VERSION ""

NS_ :

BS_:

BU_: ICC DVR EPC BBCM EAMP CMSM SBOX FLZCU_HCU_IC FLZCU_IC HCU_IC FLZCU_Signal_IC CGW TBOX BNCM CWC FRZCU

BO_ 1072 FLZCU_31: 16 FLZCU_HCU_IC
 SG_ LHTurnlightSts : 19|1@0+ (1,0) [0|1] ""  ICC,DVR
 SG_ RHTurnlightSts : 20|1@0+ (1,0) [0|1] ""  ICC,DVR
 SG_ LHFdoorSts : 23|2@0+ (1,0) [0|3] ""  ICC
 SG_ LHFSeatBeltSW : 31|1@0+ (1,0) [0|1] ""  ICC,DVR
 SG_ TrunkSts : 37|2@0+ (1,0) [0|3] ""  ICC
 SG_ RLWinPosn : 47|7@0+ (1,0) [0|100] "%"  ICC
 SG_ SeatHeatLevelsFL : 49|2@0+ (1,0) [0|3] ""  ICC
 SG_ SeatHeatLevelsRL : 61|2@0+ (1,0) [0|3] ""  ICC
 SG_ SeatVentLevelsFL : 63|2@0+ (1,0) [0|3] ""  ICC
 SG_ SeatVentLevelsRL : 87|2@0+ (1,0) [0|3] ""  ICC
 SG_ FLWinPosn : 94|7@0+ (1,0) [0|100] "%"  ICC
 SG_ FLZCU_FrontWiperMaintenanceSts : 109|2@0+ (1,0) [0|3] ""  ICC
 SG_ FLZCU_RearWiperMaintenanceSts : 107|2@0+ (1,0) [0|3] ""  ICC

BO_ 1209 VCU_2_G: 8 FLZCU_HCU_IC
 SG_ VCU_2_G_CRC : 7|8@0+ (1,0) [0|255] ""  ICC
 SG_ VCU_2_G_RollgCntr : 11|4@0+ (1,0) [0|14] ""  ICC
 SG_ VCU_2_G_Resd : 15|4@0+ (1,0) [0|15] ""  ICC
 SG_ VCU_2_G_GasPedalPosInvalidData : 24|1@0+ (1,0) [0|1] ""  ICC,DVR
 SG_ VCU_2_G_PowerLimit : 25|1@0+ (1,0) [0|1] ""  ICC
 SG_ VCU_2_G_BrakeLightReq : 26|1@0+ (1,0) [0|1] ""  ICC
 SG_ VCU_2_G_VehicleSystemFailure : 27|1@0+ (1,0) [0|1] ""  ICC
 SG_ VCU_2_G_BootloadSts : 29|1@0+ (1,0) [0|1] ""  ICC
 SG_ VCU_2_G_DischgSts : 30|1@0+ (1,0) [0|1] ""  ICC
 SG_ VCU_2_G_BrakePedalStsValidData : 31|1@0+ (1,0) [0|1] ""  ICC,DVR
 SG_ VCU_2_G_ExhibitionMod : 32|1@0+ (1,0) [0|1] ""  ICC
 SG_ VCU_2_G_BrakePedalSts : 36|1@0+ (1,0) [0|1] ""  ICC,DVR
 SG_ VCU_2_G_DCDCEnable : 37|1@0+ (1,0) [0|1] ""  ICC
 SG_ VCU_2_G_HVReady : 38|1@0+ (1,0) [0|1] ""  ICC
 SG_ Res_VCU_2_G_Brake_state : 39|1@0+ (1,0) [0|1] ""  ICC
 SG_ VCU_2_G_VCUEnergyflow : 43|4@0+ (1,0) [0|15] ""  ICC
 SG_ VCU_2_G_DrvGearShiftFailureIndcn : 53|4@0+ (1,0) [0|15] ""  ICC
 SG_ VCU_2_G_GasPedalPosition : 49|10@0+ (0.1,0) [0|100] "%"  ICC,DVR

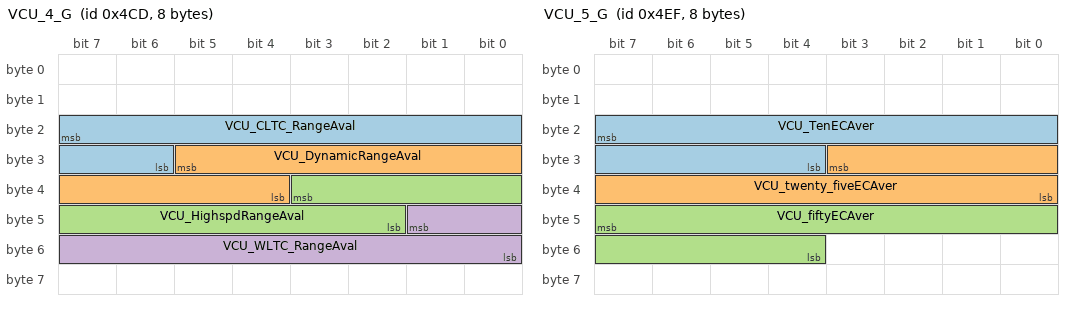
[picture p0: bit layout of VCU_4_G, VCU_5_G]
BO_ 1229 VCU_4_G: 8 FLZCU_HCU_IC
 SG_ VCU_CLTC_RangeAval : 23|10@0+ (1,0) [0|1022] "KM"  ICC
 SG_ VCU_DynamicRangeAval : 29|10@0+ (1,0) [0|1022] "KM"  ICC
 SG_ VCU_HighspdRangeAval : 35|10@0+ (1,0) [0|1022] "KM"  ICC
 SG_ VCU_WLTC_RangeAval : 41|10@0+ (1,0) [0|1022] "KM"  ICC

BO_ 1263 VCU_5_G: 8 FLZCU_HCU_IC
 SG_ VCU_TenECAver : 23|12@0+ (0.01,-10) [-10|25] "kwh"  ICC
 SG_ VCU_twenty_fiveECAver : 27|12@0+ (0.01,-10) [-10|25] "kwh"  ICC
 SG_ VCU_fiftyECAver : 47|12@0+ (0.01,-10) [-10|25] "kwh"  ICC

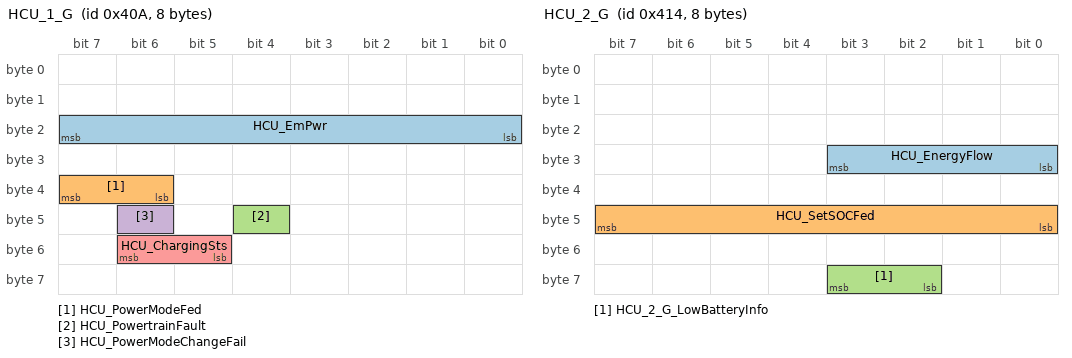
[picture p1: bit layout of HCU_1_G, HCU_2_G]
BO_ 1034 HCU_1_G: 8 FLZCU_HCU_IC
 SG_ HCU_EmPwr : 23|8@0+ (1,-128) [-100|100] "%"  ICC
 SG_ HCU_PowerModeFed : 39|2@0+ (1,0) [0|3] ""  ICC
 SG_ HCU_PowertrainFault : 44|1@0+ (1,0) [0|1] ""  ICC
 SG_ HCU_PowerModeChangeFail : 46|1@0+ (1,0) [0|1] ""  ICC
 SG_ HCU_ChargingSts : 54|2@0+ (1,0) [0|3] ""  ICC

BO_ 1044 HCU_2_G: 8 FLZCU_HCU_IC
 SG_ HCU_EnergyFlow : 27|4@0+ (1,0) [0|15] ""  ICC
 SG_ HCU_SetSOCFed : 47|8@0+ (1,0) [0|100] ""  ICC
 SG_ HCU_2_G_LowBatteryInfo : 59|2@0+ (1,0) [0|3] ""  ICC

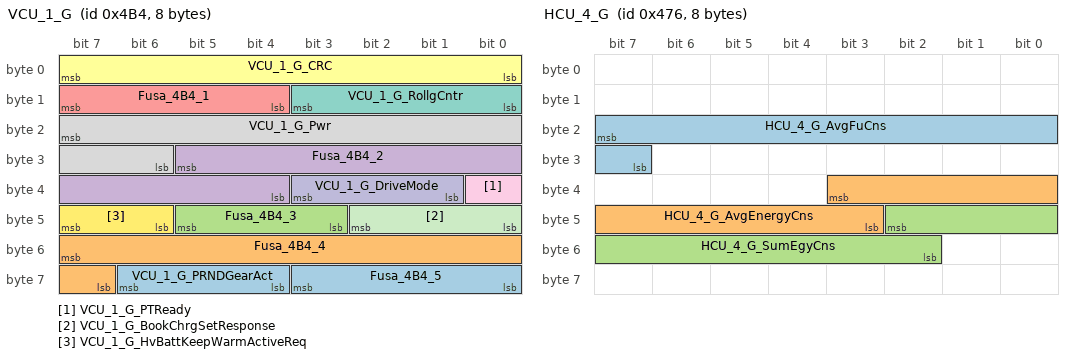
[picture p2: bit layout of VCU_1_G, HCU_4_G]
BO_ 1204 VCU_1_G: 8 FLZCU_HCU_IC
 SG_ Fusa_4B4_5 : 59|4@0+ (1,0) [0|15] ""  ICC
 SG_ Fusa_4B4_4 : 55|9@0+ (1,0) [0|511] ""  ICC
 SG_ Fusa_4B4_3 : 45|3@0+ (1,0) [0|7] ""  ICC
 SG_ Fusa_4B4_2 : 29|10@0+ (1,0) [0|1023] ""  ICC
 SG_ Fusa_4B4_1 : 15|4@0+ (1,0) [0|15] ""  ICC
 SG_ VCU_1_G_CRC : 7|8@0+ (1,0) [0|255] ""  ICC,BBCM
 SG_ VCU_1_G_RollgCntr : 11|4@0+ (1,0) [0|14] ""  ICC,BBCM
 SG_ VCU_1_G_Pwr : 23|10@0+ (1,-500) [-500|500] ""  ICC
 SG_ VCU_1_G_PTReady : 32|1@0+ (1,0) [0|1] ""  ICC
 SG_ VCU_1_G_DriveMode : 35|3@0+ (1,0) [0|7] ""  ICC
 SG_ VCU_1_G_BookChrgSetResponse : 42|3@0+ (1,0) [0|7] ""  ICC
 SG_ VCU_1_G_HvBattKeepWarmActiveReq : 47|2@0+ (1,0) [0|3] ""  ICC
 SG_ VCU_1_G_PRNDGearAct : 62|3@0+ (1,0) [0|7] ""  ICC,DVR,EPC,BBCM,EAMP,CMSM,SBOX

BO_ 1057 VCU_7_G: 32 FLZCU_HCU_IC
 SG_ VCU_TowingMode : 33|2@0+ (1,0) [0|3] ""  ICC
 SG_ VCU_EngyConsuPer50Km : 111|12@0+ (0.1,-100) [-100|100] ""  ICC
 SG_ VCU_BookChrgSetFailRes : 154|3@0+ (1,0) [0|7] ""  ICC
 SG_ VCU_BookChrgFailRes : 158|4@0+ (1,0) [0|15] ""  ICC
 SG_ VCU_BookChrgStsFb : 215|2@0+ (1,0) [0|3] ""  ICC
 SG_ HCU_EngineSelfMaintain : 231|2@0+ (1,0) [0|3] ""  ICC

BO_ 1043 FLZCU_8: 8 FLZCU_HCU_IC
 SG_ EBS_U_BATT : 7|14@0+ (0.0009765625,3) [3|18] "V"  ICC

BO_ 1022 FLZCU_40: 64 FLZCU_HCU_IC
 SG_ FLZCU_FLogolightInhibitSts : 130|1@0+ (1,0) [0|1] ""  ICC
 SG_ MaintenanceOdometer_Backup_3FEh : 175|24@0+ (0.1,0) [0|999999.9] ""  ICC
 SG_ FLZCU_CarMode : 23|3@0+ (1,0) [0|7] ""  ICC,BBCM
 SG_ FLZCU_SteerWhlposSts : 20|3@0+ (1,0) [0|7] ""  ICC
 SG_ FLZCU_MedStatusFb : 17|2@0+ (1,0) [0|3] ""  ICC,BBCM
 SG_ FLZCU_MedFailCause : 31|4@0+ (1,0) [0|15] ""  ICC
 SG_ FLZCU_MedAreaFb : 27|4@0+ (1,0) [0|15] ""  ICC
 SG_ FLZCU_MedClosePrompt : 39|2@0+ (1,0) [0|3] ""  ICC
 SG_ FLZCU_NapArea2Fb : 37|3@0+ (1,0) [0|7] ""  ICC
 SG_ FLZCU_2LSeatLvltargetCmd : 34|7@0+ (1,-1) [-1|100] "%"  ICC
 SG_ FLZCU_2LSeatBackAgtargetCmd : 43|7@0+ (1,-1) [-1|100] "%"  ICC
 SG_ FLZCU_2LSeatLegSpprttargetCmd : 52|7@0+ (1,-1) [-1|100] "%"  ICC
 SG_ FLZCU_FLWinThermalStatus : 61|1@0+ (1,0) [0|1] ""  ICC
 SG_ FLZCU_RLWinThermalStatus : 60|1@0+ (1,0) [0|1] ""  ICC
 SG_ FLZCU_MonoAmbLigSts : 59|1@0+ (1,0) [0|1] ""  ICC
 SG_ FLZCU_LogoChargingSts : 58|2@0+ (1,0) [0|3] ""  ICC
 SG_ FLZCU_2RSeatLvltargetCmd : 87|7@0+ (1,-1) [-1|100] "%"  ICC
 SG_ FLZCU_2RSeatBackAgtargetCmd : 80|7@0+ (1,-1) [-1|100] "%"  ICC
 SG_ FLZCU_2RSeatLegSpprttargetCmd : 89|7@0+ (1,-1) [-1|100] "%"  ICC
 SG_ FLZCU_SeatVentLvlFL2 : 111|4@0+ (1,0) [0|15] ""  ICC
 SG_ FLZCU_SeatVentLvlRL2 : 107|4@0+ (1,0) [0|15] ""  ICC
 SG_ FLZCU_SeatHeatLvlFL2 : 119|4@0+ (1,0) [0|15] ""  ICC
 SG_ FLZCU_SeatHeatLvlRL2 : 115|4@0+ (1,0) [0|15] ""  ICC
 SG_ FLZCU_FLSitPosnSts : 98|3@0+ (1,0) [0|7] ""  ICC
 SG_ FLZCU_SteerOverHeatWarn : 134|1@0+ (1,0) [0|1] ""  ICC

BO_ 1020 FLZCU_41: 64 FLZCU_HCU_IC
 SG_ CSA_2_WiprFrntCmd : 209|2@0+ (1,0) [0|3] ""  ICC
 SG_ ASU_2_RRHeight : 179|12@0+ (0.1,-150) [0|259.4] ""  ICC
 SG_ ASU_2_LRHeight : 175|12@0+ (0.1,-150) [0|259.4] ""  ICC
 SG_ ASU_2_RFHeight : 155|12@0+ (0.1,-150) [0|259.4] ""  ICC
 SG_ ASU_2_LFHeight : 151|12@0+ (0.1,-150) [0|259.4] ""  ICC
 SG_ ASU_2_sensorErrorSts : 143|4@0+ (1,0) [0|15] ""  ICC
 SG_ SAM_1_SteeringAngleSpeed : 23|8@0+ (4,0) [0|1016] "deg/Sec"  ICC
 SG_ SAM_1_SteeringAngle : 31|16@0+ (0.0625,-2048) [-2048|2047.875] "deg"  ICC
 SG_ BMSH_MaxChgPwrPeak : 47|12@0+ (0.1,0) [0|320] "KW"  ICC
 SG_ BMSH_MaxDchgPwrPeak : 51|12@0+ (0.1,0) [0|320] "KW"  ICC
 SG_ FMCU_8_ISGF_SpdAct : 71|16@0+ (1,-32767) [-32767|32766] "rpm"  ICC
 SG_ RMCU_1_Speed : 87|16@0+ (1,-32767) [-32767|32766] "rpm"  ICC
 SG_ SAM_1_SteeringAngleVD : 96|1@0+ (1,0) [0|1] ""  ICC
 SG_ SAM_1_SteeringAngleSpeedVD : 97|1@0+ (1,0) [0|1] ""  ICC
 SG_ CSA_2_AllWarningInfo : 100|3@0+ (1,0) [0|7] ""  ICC
 SG_ RELC_RoofCampLampConfigDisp : 101|1@0+ (1,0) [0|1] ""  ICC
 SG_ RELC_TopLightConfigDisp : 102|1@0+ (1,0) [0|1] ""  ICC
 SG_ EELC_APillarLightConfigDisp : 103|1@0+ (1,0) [0|1] ""  ICC
 SG_ RELC_RoofCampLampStsL : 111|2@0+ (1,0) [0|3] ""  ICC
 SG_ RELC_RoofCampLampStsR : 109|2@0+ (1,0) [0|3] ""  ICC
 SG_ RELC_TopLightSts : 107|2@0+ (1,0) [0|3] ""  ICC
 SG_ EELC_APillarYellowAmbientSts : 105|2@0+ (1,0) [0|3] ""  ICC
 SG_ EELC_APillarWhiteAmbientSts : 119|2@0+ (1,0) [0|3] ""  ICC
 SG_ EELC_APillarSpotLampSts : 117|2@0+ (1,0) [0|3] ""  ICC
 SG_ RMCU_1_TCURErrLvlDis : 127|3@0+ (1,0) [0|4] ""  ICC

BO_ 1142 HCU_4_G: 8 FLZCU_HCU_IC
 SG_ HCU_4_G_AvgFuCns : 23|9@0+ (0.1,0) [0|50] "L/100km"  ICC
 SG_ HCU_4_G_AvgEnergyCns : 35|9@0+ (0.1,0) [0|50] "L/100km"  ICC
 SG_ HCU_4_G_SumEgyCns : 42|9@0+ (0.1,0) [0|50] "L/100km"  ICC

BO_ 1314 HCU_25: 64 FLZCU_HCU_IC
 SG_ DriveModeChangeFailReason_522h : 429|2@0+ (1,0) [0|3] ""  ICC
 SG_ HCU_DeepSnowSts_522h : 427|2@0+ (1,0) [0|3] ""  ICC
 SG_ HCU_CrossBorderSts : 341|2@0+ (1,0) [0|3] ""  ICC
 SG_ HCU_SumElecCns : 339|12@0+ (0.1,-100) [-100|100] "kwh/100km"  ICC
 SG_ HCU_V2lDisChgBck : 17|2@0+ (1,0) [0|3] ""  ICC
 SG_ HCU_DisChgMemFed : 19|2@0+ (1,0) [0|3] ""  ICC
 SG_ HCU_V2VDisChgBck : 21|2@0+ (1,0) [0|3] ""  ICC
 SG_ HCU_V2l_IntlDisChgBck : 23|2@0+ (1,0) [0|3] ""  ICC
 SG_ HCU_FuelDetnOpDefeated : 25|2@0+ (1,0) [0|3] ""  ICC
 SG_ HCU_FuelDetnModSwtFed : 27|2@0+ (1,0) [0|3] ""  ICC
 SG_ HCU_FuelDetnStateFed : 29|2@0+ (1,0) [0|3] ""  ICC
 SG_ HCU_HVDownRepairModeFed : 31|2@0+ (1,0) [0|3] ""  ICC
 SG_ HCU_TrailerMode : 39|2@0+ (1,0) [0|3] ""  ICC
 SG_ HCU_SumFuCns : 37|9@0+ (0.1,0) [0|50] "L/km"  ICC
 SG_ HCU_DrivePowerDispSetFed : 51|2@0+ (1,0) [0|3] ""  ICC
 SG_ HCU_KeyDriveModememory : 49|2@0+ (1,0) [0|3] ""  ICC
 SG_ HCU_DRIFTModeSts : 63|2@0+ (1,0) [0|3] ""  ICC
 SG_ HCU_EXPERTEcoFed : 60|2@0+ (1,0) [0|3] ""  ICC
 SG_ HCU_4LModeFed : 58|1@0+ (1,0) [0|1] ""  ICC
 SG_ HCU_EXPERTNormFed : 57|2@0+ (1,0) [0|3] ""  ICC
 SG_ HCU_SingleRegnRmn : 61|1@0+ (1,0) [0|1] ""  ICC
 SG_ HCU_EXPERTSportFed : 87|2@0+ (1,0) [0|3] ""  ICC
 SG_ HCU_CrossaxisFed : 85|2@0+ (1,0) [0|3] ""  ICC
 SG_ HCU_EXPERTRWDFed : 83|2@0+ (1,0) [0|3] ""  ICC
 SG_ HCU_EXPERTAWDFed : 81|2@0+ (1,0) [0|3] ""  ICC
 SG_ HCU_EXPERTAutoFed : 95|2@0+ (1,0) [0|3] ""  ICC
 SG_ HCU_CLIMBFed : 93|2@0+ (1,0) [0|3] ""  ICC
 SG_ HCU_StopChrgnFed : 91|2@0+ (1,0) [0|3] ""  ICC
 SG_ HCU_StopChrgnModeFed : 89|2@0+ (1,0) [0|3] ""  ICC
 SG_ HCU_ChrgnFctMemSt : 102|2@0+ (1,0) [0|3] ""  ICC
 SG_ HCU_LVPowSupSYSAbn_lit : 100|1@0+ (1,0) [0|1] ""  ICC
 SG_ HCU_IMMOReleaseSignal : 99|1@0+ (1,0) [0|1] ""  ICC
 SG_ HCU_PowerCut : 98|1@0+ (1,0) [0|1] ""  ICC
 SG_ HCU_ParkingChargeReminder : 97|1@0+ (1,0) [0|1] ""  ICC
 SG_ HCU_HEV_FunctionLimit : 96|1@0+ (1,0) [0|1] ""  ICC
 SG_ HCU_SetModeNotChange : 110|1@0+ (1,0) [0|1] ""  ICC
 SG_ HCU_UTURNSnowFed : 111|1@0+ (1,0) [0|1] ""  ICC
 SG_ HCU_DriveInhibit_GearP : 109|1@0+ (1,0) [0|1] ""  ICC
 SG_ HCU_AccleAbility_Limit : 108|1@0+ (1,0) [0|1] ""  ICC
 SG_ HCU_VehicleSpeedMax_Limit : 107|1@0+ (1,0) [0|1] ""  ICC
 SG_ HCU_EngineRunClmReq : 106|1@0+ (1,0) [0|1] ""  ICC
 SG_ HCU_DisconnectChagWarn : 105|1@0+ (1,0) [0|1] ""  ICC
 SG_ HCU_PowerModeChangeInhibit : 104|1@0+ (1,0) [0|1] ""  ICC
 SG_ HCU_DisChargeStopFault : 119|2@0+ (1,0) [0|3] ""  ICC
 SG_ HCU_DedicatedModeInhibit : 117|1@0+ (1,0) [0|1] ""  ICC
 SG_ HCU_LeaveVehicleWarning : 116|1@0+ (1,0) [0|1] ""  ICC
 SG_ HCU_TowingModeEna : 115|1@0+ (1,0) [0|1] ""  ICC
 SG_ HCU_PowerLevel : 114|3@0+ (1,0) [0|7] ""  ICC
 SG_ HCU_FrntEDLSts : 127|4@0+ (1,0) [0|15] ""  ICC
 SG_ HCU_RearEDLSts : 123|4@0+ (1,0) [0|15] ""  ICC
 SG_ HCU_DriveMode_JT : 151|5@0+ (1,0) [0|31] ""  ICC
 SG_ HCU_CruiseLimitSpeedValue : 146|13@0+ (0.0625,0) [0|511.875] "km/h"  ICC
 SG_ HCU_CCOSwtFed : 165|2@0+ (1,0) [0|3] ""  ICC
 SG_ HCU_SinglePedalMemFed : 163|1@0+ (1,0) [0|1] ""  ICC
 SG_ HCU_Pwr : 175|12@0+ (1,-2000) [-2000|2000] "KW"  ICC
 SG_ HCU_SocManageFed : 162|3@0+ (1,0) [0|7] ""  ICC
 SG_ HCU_EgyRegenLevel : 191|3@0+ (1,0) [0|7] ""  ICC
 SG_ HCU_DrvGearShiftFailureIndcn : 179|4@0+ (1,0) [0|15] ""  ICC
 SG_ HCU_EXPERTEESPSet : 188|2@0+ (1,0) [0|3] ""  ICC
 SG_ HCU_UTURNSandFed : 184|1@0+ (1,0) [0|1] ""  ICC
 SG_ HCU_CruiseControlStatus : 186|2@0+ (1,0) [0|3] ""  ICC
 SG_ HCU_LTCDispFed : 215|2@0+ (1,0) [0|3] ""  ICC
 SG_ HCU_UTURNMudFed : 213|1@0+ (1,0) [0|1] ""  ICC
 SG_ HCU_UTURNGrassFed : 212|1@0+ (1,0) [0|1] ""  ICC
 SG_ HCU_EngyFlowToDisp : 211|5@0+ (1,0) [0|31] ""  ICC
 SG_ HCU_DriveModeChangeFail : 222|1@0+ (1,0) [0|1] ""  ICC
 SG_ HCU_iCCO_Warn : 221|4@0+ (1,0) [0|15] ""  ICC
 SG_ HCU_iTAS_Warn : 217|3@0+ (1,0) [0|7] ""  ICC
 SG_ HCU_DraggingModeRemind : 230|3@0+ (1,0) [0|7] ""  ICC
 SG_ HCU_25_EDLFed : 227|2@0+ (1,0) [0|3] ""  ICC
 SG_ HCU_25_Crossaxis_Warn : 225|3@0+ (1,0) [0|7] ""  ICC
 SG_ HCU_iTAS_Active : 238|2@0+ (1,0) [0|3] ""  ICC
 SG_ HCU_ExterTempLowHint : 236|2@0+ (1,0) [0|3] ""  ICC
 SG_ HCU_25_iTAS_SlopWarn : 234|2@0+ (1,0) [0|3] ""  ICC
 SG_ HCU_iTASSceneReq : 232|3@0+ (1,0) [0|7] ""  ICC
 SG_ HCU_DrivingModReq : 245|5@0+ (1,0) [0|31] ""  ICC
 SG_ HCU_25_VehSpdOffroadRmn : 240|1@0+ (1,0) [0|1] ""  ICC
 SG_ HCU_25_LaunchMod_Warn : 303|3@0+ (1,0) [0|7] ""  ICC
 SG_ HCU_25_SetVehSpdOffroad : 300|2@0+ (1,0) [0|3] ""  ICC
 SG_ HCU_25_iDRIFT_Warn : 298|3@0+ (1,0) [0|7] ""  ICC
 SG_ HCU_25_TAB_Warn : 307|3@0+ (1,0) [0|7] ""  ICC
 SG_ HCU_25_CCO_TextDisp : 311|4@0+ (1,0) [0|15] ""  ICC

BO_ 1075 VCC_2: 8 FLZCU_HCU_IC
 SG_ VCC_2_ConfigurationMessageTrg : 23|1@0+ (1,0) [0|1] ""  ICC,BBCM

BO_ 1136 VCC_3: 32 FLZCU_IC
 SG_ VCC_3_CRC : 7|8@0+ (1,0) [0|255] ""  ICC,BBCM
 SG_ VCC_3_RollgCntr : 11|4@0+ (1,0) [0|14] ""  ICC,BBCM
 SG_ VCC_3_Resd1 : 15|4@0+ (1,0) [0|15] ""  ICC,BBCM
 SG_ VCC_3_SN : 23|8@0+ (1,0) [1|32] ""  ICC,BBCM

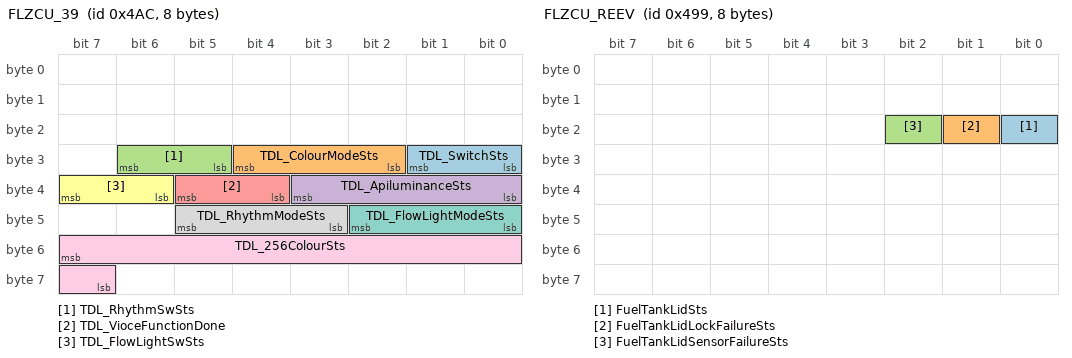
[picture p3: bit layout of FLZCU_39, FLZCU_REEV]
BO_ 1196 FLZCU_39: 8 FLZCU_HCU_IC
 SG_ TDL_SwitchSts : 25|2@0+ (1,0) [0|3] ""  ICC
 SG_ TDL_ColourModeSts : 28|3@0+ (1,0) [0|7] ""  ICC
 SG_ TDL_RhythmSwSts : 30|2@0+ (1,0) [0|3] ""  ICC
 SG_ TDL_ApiluminanceSts : 35|4@0+ (1,0) [0|15] ""  ICC
 SG_ TDL_VioceFunctionDone : 37|2@0+ (1,0) [0|3] ""  ICC
 SG_ TDL_FlowLightSwSts : 39|2@0+ (1,0) [0|3] ""  ICC
 SG_ TDL_FlowLightModeSts : 42|3@0+ (1,0) [0|7] ""  ICC
 SG_ TDL_RhythmModeSts : 45|3@0+ (1,0) [0|7] ""  ICC
 SG_ TDL_256ColourSts : 55|9@0+ (1,0) [0|256] ""  ICC

BO_ 1177 FLZCU_REEV: 8 FLZCU_HCU_IC
 SG_ FuelTankLidSts : 16|1@0+ (1,0) [0|1] ""  ICC
 SG_ FuelTankLidLockFailureSts : 17|1@0+ (1,0) [0|1] ""  ICC
 SG_ FuelTankLidSensorFailureSts : 18|1@0+ (1,0) [0|1] ""  ICC

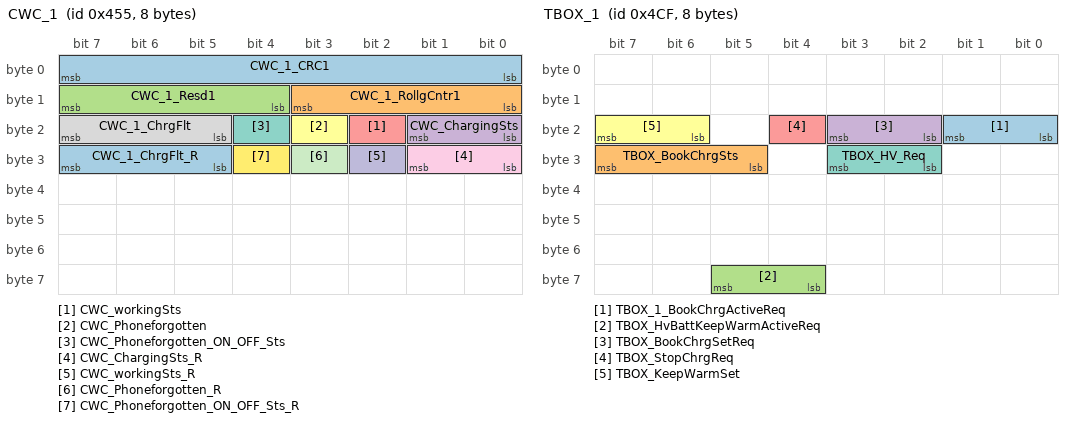
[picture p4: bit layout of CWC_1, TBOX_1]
BO_ 1109 CWC_1: 8 CGW
 SG_ CWC_1_CRC1 : 7|8@0+ (1,0) [0|255] ""  ICC
 SG_ CWC_1_RollgCntr1 : 11|4@0+ (1,0) [0|14] ""  ICC
 SG_ CWC_1_Resd1 : 15|4@0+ (1,0) [0|15] ""  ICC
 SG_ CWC_ChargingSts : 17|2@0+ (1,0) [0|3] ""  ICC
 SG_ CWC_workingSts : 18|1@0+ (1,0) [0|1] ""  ICC
 SG_ CWC_Phoneforgotten : 19|1@0+ (1,0) [0|1] ""  ICC
 SG_ CWC_Phoneforgotten_ON_OFF_Sts : 20|1@0+ (1,0) [0|1] ""  ICC
 SG_ CWC_1_ChrgFlt : 23|3@0+ (1,0) [0|7] ""  ICC
 SG_ CWC_ChargingSts_R : 25|2@0+ (1,0) [0|3] ""  ICC
 SG_ CWC_workingSts_R : 26|1@0+ (1,0) [0|1] ""  ICC
 SG_ CWC_Phoneforgotten_R : 27|1@0+ (1,0) [0|1] ""  ICC
 SG_ CWC_Phoneforgotten_ON_OFF_Sts_R : 28|1@0+ (1,0) [0|1] ""  ICC
 SG_ CWC_1_ChrgFlt_R : 31|3@0+ (1,0) [0|7] ""  ICC

BO_ 1231 TBOX_1: 8 CGW
 SG_ TBOX_1_BookChrgActiveReq : 17|2@0+ (1,0) [0|3] ""  ICC
 SG_ TBOX_BookChrgSts : 31|3@0+ (1,0) [0|7] ""  ICC
 SG_ TBOX_HvBattKeepWarmActiveReq : 61|2@0+ (1,0) [0|3] ""  ICC
 SG_ TBOX_BookChrgSetReq : 19|2@0+ (1,0) [0|3] ""  ICC
 SG_ TBOX_StopChrgReq : 20|1@0+ (1,0) [0|1] ""  ICC
 SG_ TBOX_KeepWarmSet : 23|2@0+ (1,0) [0|3] ""  ICC
 SG_ TBOX_HV_Req : 27|2@0+ (1,0) [0|3] ""  ICC

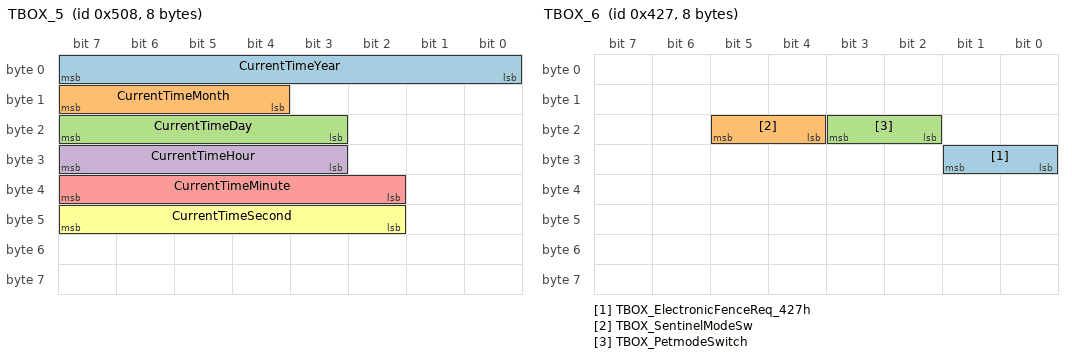
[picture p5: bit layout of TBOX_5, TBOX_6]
BO_ 1288 TBOX_5: 8 CGW
 SG_ CurrentTimeYear : 7|8@0+ (1,2000) [2000|2255] ""  ICC,SBOX
 SG_ CurrentTimeMonth : 15|4@0+ (1,0) [1|12] ""  ICC,SBOX
 SG_ CurrentTimeDay : 23|5@0+ (1,0) [1|31] ""  ICC,SBOX
 SG_ CurrentTimeHour : 31|5@0+ (1,0) [0|23] ""  ICC,SBOX
 SG_ CurrentTimeMinute : 39|6@0+ (1,0) [0|59] ""  ICC,SBOX
 SG_ CurrentTimeSecond : 47|6@0+ (1,0) [0|59] ""  ICC,SBOX

BO_ 1063 TBOX_6: 8 CGW
 SG_ TBOX_ElectronicFenceReq_427h : 25|2@0+ (1,0) [0|3] ""  ICC
 SG_ TBOX_SentinelModeSw : 21|2@0+ (1,0) [0|3] ""  ICC
 SG_ TBOX_PetmodeSwitch : 19|2@0+ (1,0) [0|3] ""  ICC

BO_ 1148 TBOX_7: 32 CGW
 SG_ ReservationSentinelSts_Fed_47Ch : 183|2@0+ (1,0) [0|3] ""  ICC
 SG_ TimeToStopSentinelMinutFed_47Ch : 181|6@0+ (1,0) [0|63] ""  ICC
 SG_ TimeToStopSentinelHourFed_47Ch : 172|5@0+ (1,0) [0|31] ""  ICC
 SG_ TimeToStartSentinelMinutFed_47Ch : 165|6@0+ (1,0) [0|63] ""  ICC
 SG_ TimeToStartSentinelHourFed_47Ch : 158|5@0+ (1,0) [0|31] ""  ICC
 SG_ TimeToStartSentinelDayFed_47Ch : 153|2@0+ (1,0) [0|3] ""  ICC
 SG_ TBOX_BkChrgStartTimeDay : 23|5@0+ (1,0) [1|31] "日"  ICC
 SG_ TBOX_BkChrgStartTimeeHour : 31|5@0+ (1,0) [0|23] "小时"  ICC
 SG_ TBOX_BkChrgStartTimeMin : 39|6@0+ (1,0) [0|59] "分钟"  ICC
 SG_ TBOX_GPSSwitchSts : 33|2@0+ (1,0) [0|3] ""  ICC
 SG_ TBOX_BkChrgStartTimeMonth : 47|4@0+ (1,0) [1|12] "月"  ICC
 SG_ TBOX_BkChrgStartTimeYear : 55|16@0+ (1,1900) [1900|9999] "年"  ICC
 SG_ TBOX_BkChrgDuration : 87|12@0+ (1,0) [0|1440] "min"  ICC
 SG_ TBOX_BkChrgCycleType : 91|3@0+ (1,0) [0|7] ""  ICC
 SG_ TBOX_BkChrgCycleMon : 103|2@0+ (1,0) [0|3] ""  ICC
 SG_ TBOX_BkChrgCycleTues : 101|2@0+ (1,0) [0|3] ""  ICC
 SG_ TBOX_BkChrgCycleWen : 99|2@0+ (1,0) [0|3] ""  ICC
 SG_ TBOX_BkChrgCycleThur : 97|2@0+ (1,0) [0|3] ""  ICC
 SG_ TBOX_BkChrgCycleFri : 111|2@0+ (1,0) [0|3] ""  ICC
 SG_ TBOX_BkChrgCycleSat : 109|2@0+ (1,0) [0|3] ""  ICC
 SG_ TBOX_BkChrgCycleSun : 107|2@0+ (1,0) [0|3] ""  ICC
 SG_ TBOX_KeepWarmStrt : 119|5@0+ (1,0) [1|31] "日"  ICC
 SG_ TBOX_KeepWarmStrtHour : 127|5@0+ (1,0) [0|23] "小时"  ICC
 SG_ TBOX_KeepWarmStrtMin : 151|6@0+ (1,0) [0|59] "分钟"  ICC

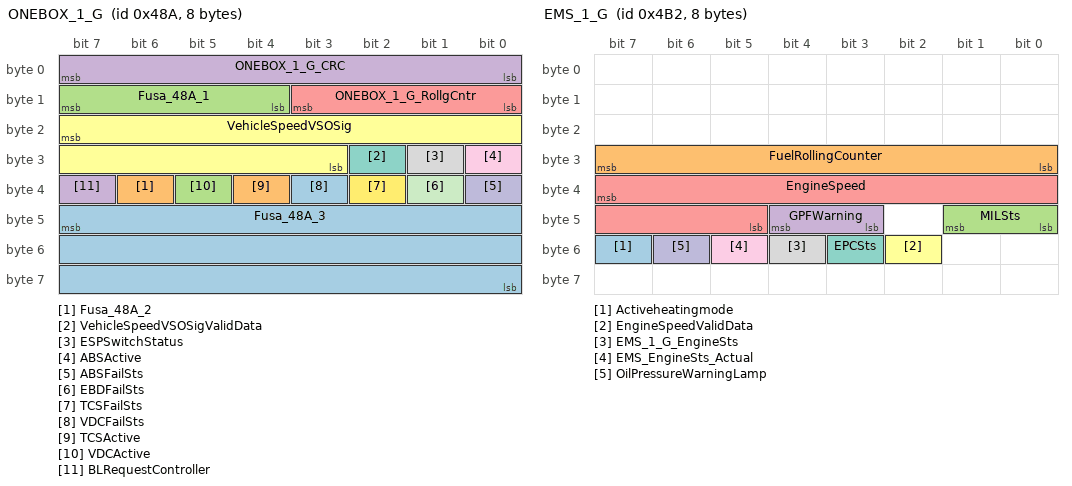
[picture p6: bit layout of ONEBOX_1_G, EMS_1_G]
BO_ 1162 ONEBOX_1_G: 8 CGW
 SG_ Fusa_48A_3 : 47|24@0+ (1,0) [0|16777215] ""  ICC
 SG_ Fusa_48A_2 : 38|1@0+ (1,0) [0|1] ""  ICC
 SG_ Fusa_48A_1 : 15|4@0+ (1,0) [0|15] ""  ICC
 SG_ ONEBOX_1_G_CRC : 7|8@0+ (1,0) [0|255] ""  ICC,BBCM
 SG_ ONEBOX_1_G_RollgCntr : 11|4@0+ (1,0) [0|14] ""  ICC,BBCM
 SG_ VehicleSpeedVSOSig : 23|13@0+ (0.0625,0) [0|511.875] "km/h"  ICC,DVR,EPC,BBCM,EAMP,CMSM,SBOX
 SG_ VehicleSpeedVSOSigValidData : 26|1@0+ (1,0) [0|1] ""  ICC,DVR,EPC,BBCM,EAMP,CMSM,SBOX
 SG_ ESPSwitchStatus : 25|1@0+ (1,0) [0|1] ""  ICC
 SG_ ABSActive : 24|1@0+ (1,0) [0|1] ""  ICC
 SG_ ABSFailSts : 32|1@0+ (1,0) [0|1] ""  ICC
 SG_ EBDFailSts : 33|1@0+ (1,0) [0|1] ""  ICC
 SG_ TCSFailSts : 34|1@0+ (1,0) [0|1] ""  ICC
 SG_ VDCFailSts : 35|1@0+ (1,0) [0|1] ""  ICC
 SG_ TCSActive : 36|1@0+ (1,0) [0|1] ""  ICC
 SG_ VDCActive : 37|1@0+ (1,0) [0|1] ""  ICC
 SG_ BLRequestController : 39|1@0+ (1,0) [0|1] ""  ICC

BO_ 1202 EMS_1_G: 8 CGW
 SG_ Activeheatingmode : 55|1@0+ (1,0) [0|1] ""  ICC
 SG_ FuelRollingCounter : 31|8@0+ (7.88519E-005,0) [0|0.0200283826] "ltr"  ICC
 SG_ MILSts : 41|2@0+ (1,0) [0|3] ""  ICC
 SG_ GPFWarning : 44|2@0+ (1,0) [0|3] ""  ICC
 SG_ EngineSpeed : 39|11@0+ (4,0) [0|8000] "rpm"  ICC
 SG_ EngineSpeedValidData : 50|1@0+ (1,0) [0|1] ""  ICC
 SG_ EPCSts : 51|1@0+ (1,0) [0|1] ""  ICC
 SG_ EMS_1_G_EngineSts : 52|1@0+ (1,0) [0|1] ""  ICC
 SG_ EMS_EngineSts_Actual : 53|1@0+ (1,0) [0|1] ""  ICC,EAMP
 SG_ OilPressureWarningLamp : 54|1@0+ (1,0) [0|1] ""  ICC

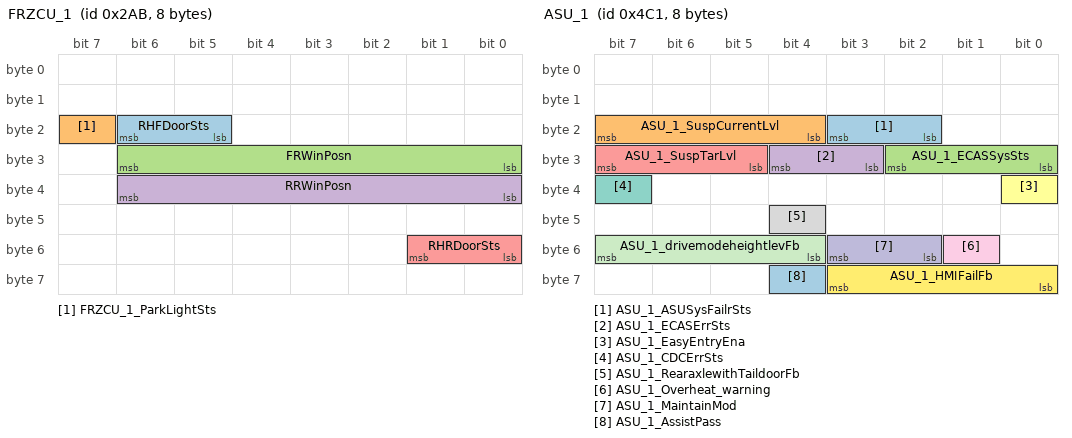
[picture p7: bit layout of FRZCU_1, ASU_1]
BO_ 683 FRZCU_1: 8 CGW
 SG_ RHFDoorSts : 22|2@0+ (1,0) [0|3] ""  ICC,EPC,BBCM,CMSM
 SG_ FRZCU_1_ParkLightSts : 23|1@0+ (1,0) [0|1] ""  ICC
 SG_ FRWinPosn : 30|7@0+ (1,0) [0|100] "%"  ICC
 SG_ RRWinPosn : 38|7@0+ (1,0) [0|100] "%"  ICC
 SG_ RHRDoorSts : 49|2@0+ (1,0) [0|3] ""  ICC,EPC,BBCM,CMSM

BO_ 33 ACU_3: 8 CGW
 SG_ ACU_3_LongitudinalAcceleration : 23|16@0+ (0.001,-2) [-2|2] "g"  ICC
 SG_ ACU_3_LongitudinalAccelerationVD : 39|2@0+ (1,0) [0|3] ""  ICC

BO_ 632 EMS_4: 8 CGW
 SG_ EngineCoolantTemperature : 23|8@0+ (0.75,-48) [-48|142.5] "°C"  ICC

BO_ 1217 ASU_1: 8 CGW
 SG_ ASU_1_ASUSysFailrSts : 19|2@0+ (1,0) [0|3] ""  ICC
 SG_ ASU_1_SuspCurrentLvl : 23|4@0+ (1,0) [0|15] ""  ICC
 SG_ ASU_1_ECASSysSts : 26|3@0+ (1,0) [0|7] ""  ICC
 SG_ ASU_1_ECASErrSts : 28|2@0+ (1,0) [0|3] ""  ICC
 SG_ ASU_1_SuspTarLvl : 31|3@0+ (1,0) [0|7] ""  ICC
 SG_ ASU_1_EasyEntryEna : 32|1@0+ (1,0) [0|1] ""  ICC
 SG_ ASU_1_CDCErrSts : 39|1@0+ (1,0) [0|1] ""  ICC
 SG_ ASU_1_RearaxlewithTaildoorFb : 44|1@0+ (1,0) [0|1] ""  ICC
 SG_ ASU_1_Overheat_warning : 49|1@0+ (1,0) [0|1] ""  ICC
 SG_ ASU_1_MaintainMod : 51|2@0+ (1,0) [0|3] ""  ICC
 SG_ ASU_1_drivemodeheightlevFb : 55|4@0+ (1,0) [0|15] ""  ICC
 SG_ ASU_1_HMIFailFb : 59|4@0+ (1,0) [0|15] ""  ICC
 SG_ ASU_1_AssistPass : 60|1@0+ (1,0) [0|1] ""  ICC

BO_ 258 BMS_1: 48 CGW
 SG_ BMS_1_CRC1 : 7|8@0+ (1,0) [0|255] ""  ICC
 SG_ BMS_1_RollgCntr1 : 11|4@0+ (1,0) [0|14] ""  ICC
 SG_ BMS_1_Resd1 : 15|4@0+ (1,0) [0|15] ""  ICC
 SG_ BMS_PackVoltage : 23|16@0+ (0.1,0) [0|1000] "volt(V)"  ICC
 SG_ BMS_PackCurrent : 39|16@0+ (0.1,-2047) [-2047|2047] "ampere(A)"  ICC
 SG_ BMS_HvBattSts : 51|4@0+ (1,0) [0|15] ""  ICC
 SG_ BMS_SysSelfCheck : 53|2@0+ (1,0) [0|3] ""  ICC
 SG_ BMS_HVBattThermRunaway : 55|2@0+ (1,0) [0|3] ""  ICC
 SG_ BMS_1_CRC2 : 71|8@0+ (1,0) [0|255] ""  ICC
 SG_ BMS_1_RollgCntr2 : 75|4@0+ (1,0) [0|14] ""  ICC
 SG_ BMS_1_Resd2 : 79|4@0+ (1,0) [0|15] ""  ICC
 SG_ BMS_ChargeVoltageReq : 87|14@0+ (0.1,0) [0|1024] "volt(V)"  ICC
 SG_ BMS_ChgCurrReq : 103|14@0+ (0.1,-1024) [-1024|0] "ampere(A)"  ICC
 SG_ BMS_InfraDcUActDc : 119|14@0+ (0.1,0) [0|1024] "volt(V)"  ICC
 SG_ BMS_1_CRC3 : 135|8@0+ (1,0) [0|255] ""  ICC
 SG_ BMS_1_RollgCntr3 : 139|4@0+ (1,0) [0|14] ""  ICC
 SG_ BMS_1_Resd3 : 143|4@0+ (1,0) [0|15] ""  ICC
 SG_ BMS_InfraDcIActDc : 151|14@0+ (0.1,-1024) [-1024|0] "ampere(A)"  ICC
 SG_ BMS_HvBattDynChrgnILim : 167|14@0+ (0.1,-1024) [-1024|0] "ampere(A)"  ICC
 SG_ BMS_HvBattUChrgnLim : 183|14@0+ (0.1,0) [0|1024] "volt(V)"  ICC
 SG_ BMS_1_CRC4 : 199|8@0+ (1,0) [0|255] ""  ICC
 SG_ BMS_1_RollgCntr4 : 203|4@0+ (1,0) [0|14] ""  ICC
 SG_ BMS_1_Resd4 : 207|4@0+ (1,0) [0|15] ""  ICC
 SG_ BMS_DChrgAPlusSt : 217|1@0+ (1,0) [0|1] ""  ICC
 SG_ BMS_ChrgDcIAvl : 215|14@0+ (0.1,-1024) [-1024|0] "ampere(A)"  ICC
 SG_ BMS_Insulation_R : 231|16@0+ (1,0) [0|60000] "kiloohm(kΩ)"  ICC
 SG_ BMS_ChrgDcCnctrDetd : 241|2@0+ (1,0) [0|3] ""  ICC
 SG_ BMS_DCChgMode : 244|3@0+ (1,0) [0|7] ""  ICC
 SG_ BMS_ChrgDcChrgnFltStopReas : 247|3@0+ (1,0) [0|7] ""  ICC
 SG_ BMS_1_CRC5 : 263|8@0+ (1,0) [0|255] ""  ICC
 SG_ BMS_1_RollgCntr5 : 267|4@0+ (1,0) [0|14] ""  ICC
 SG_ BMS_1_Resd5 : 271|4@0+ (1,0) [0|15] ""  ICC
 SG_ BMS_ChargeRequest_Mode : 284|4@0+ (1,0) [0|15] ""  ICC
 SG_ BMS_ChgRemTime : 279|11@0+ (1,0) [0|1440] "min"  ICC
 SG_ BMS_1_StateOfChargeDis : 295|8@0+ (1,0) [0|100] "%"  ICC
 SG_ BMS_StateOfEnergy : 311|16@0+ (0.1,0) [0|999.9] "kWh"  ICC
 SG_ BMS_1_CRC6 : 327|8@0+ (1,0) [0|255] ""  ICC
 SG_ BMS_1_RollgCntr6 : 331|4@0+ (1,0) [0|14] ""  ICC
 SG_ BMS_1_Resd6 : 335|4@0+ (1,0) [0|15] ""  ICC
 SG_ BMS_StateOfHealth : 342|7@0+ (1,0) [0|100] ""  ICC
 SG_ BMS_BlanceState : 343|1@0+ (1,0) [0|1] ""  ICC
 SG_ BMS_IsolationFault : 345|2@0+ (1,0) [0|3] ""  ICC
 SG_ BMS_HVILFault_DC : 346|1@0+ (1,0) [0|1] ""  ICC
 SG_ BMS_HVILFault_FMCU : 347|1@0+ (1,0) [0|1] ""  ICC
 SG_ BMS_HVILFault_RMCU : 348|1@0+ (1,0) [0|1] ""  ICC
 SG_ BMS_SOCDis : 359|14@0+ (0.01,0) [0|100] "%"  ICC
 SG_ BMS_InfraDcIActDcMin : 375|14@0+ (0.1,-1024) [-1024|0] "ampere(A)"  ICC

BO_ 1290 BMS_8: 8 CGW
 SG_ BMS_8_CRC1 : 7|8@0+ (1,0) [0|255] ""  ICC
 SG_ BMS_8_RollgCntr1 : 11|4@0+ (1,0) [0|14] ""  ICC
 SG_ BMS_8_Resd1 : 15|4@0+ (1,0) [0|15] ""  ICC
 SG_ BMS_HvBattCellOverU : 18|3@0+ (1,0) [0|4] ""  ICC
 SG_ BMS_HvBattCellUnderU : 21|3@0+ (1,0) [0|4] ""  ICC
 SG_ BMS_HvBattUnderU : 23|2@0+ (1,0) [0|2] ""  ICC
 SG_ BMS_HvBattDischargeOverCurrent : 26|3@0+ (1,0) [0|4] ""  ICC
 SG_ BMS_HvBattChargeOverCurrent : 29|3@0+ (1,0) [0|4] ""  ICC
 SG_ BMS_HvBattOverU : 31|2@0+ (1,0) [0|2] ""  ICC
 SG_ BMS_HvBattMismatching : 32|1@0+ (1,0) [0|1] ""  ICC
 SG_ BMS_HvBattSocJump : 33|1@0+ (1,0) [0|1] ""  ICC
 SG_ BMS_HvBattCellUUnif : 34|1@0+ (1,0) [0|1] ""  ICC
 SG_ BMS_HvBattLowSoc : 35|1@0+ (1,0) [0|1] ""  ICC
 SG_ BMS_HvBattOverSoc : 36|1@0+ (1,0) [0|1] ""  ICC
 SG_ BMS_HvBattTempUniformity : 37|1@0+ (1,0) [0|1] ""  ICC
 SG_ BMS_BattInterCANErr : 38|1@0+ (1,0) [0|1] ""  ICC
 SG_ BMS_HvBattOverCharging : 39|1@0+ (1,0) [0|1] ""  ICC
 SG_ BMS_HvBattOverTemperature : 47|3@0+ (1,0) [0|4] ""  ICC

BO_ 1163 FMCU_6: 8 CGW
 SG_ FMCU_SysTempOvrInd : 19|1@0+ (1,0) [0|1] ""  ICC

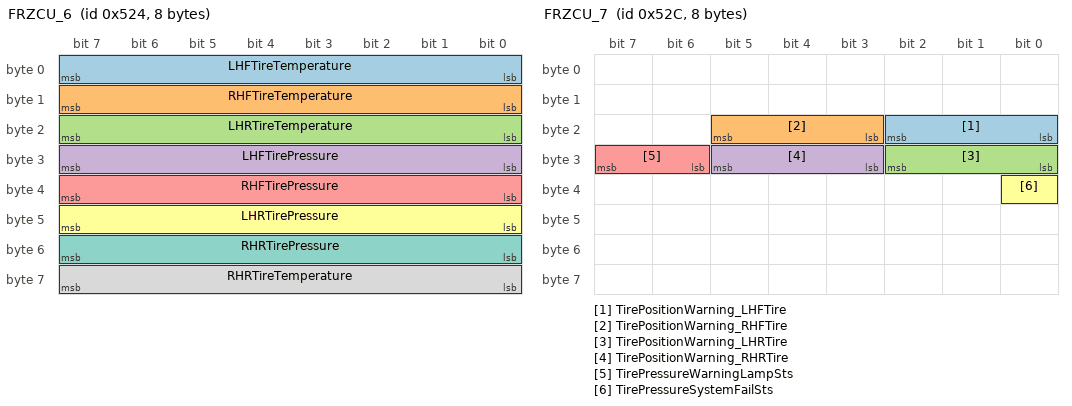
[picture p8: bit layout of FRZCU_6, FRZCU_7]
BO_ 1316 FRZCU_6: 8 CGW
 SG_ LHFTireTemperature : 7|8@0+ (0.65,-40) [-40|125.1] "℃"  ICC
 SG_ RHFTireTemperature : 15|8@0+ (0.65,-40) [-40|125.1] "℃"  ICC
 SG_ LHRTireTemperature : 23|8@0+ (0.65,-40) [-40|125.1] "℃"  ICC
 SG_ LHFTirePressure : 31|8@0+ (1.373,0) [0|350.115] "kPa"  ICC
 SG_ RHFTirePressure : 39|8@0+ (1.373,0) [0|350.115] "kPa"  ICC
 SG_ LHRTirePressure : 47|8@0+ (1.373,0) [0|350.115] "kPa"  ICC
 SG_ RHRTirePressure : 55|8@0+ (1.373,0) [0|350.115] "kPa"  ICC
 SG_ RHRTireTemperature : 63|8@0+ (0.65,-40) [-40|125.1] "℃"  ICC

BO_ 1324 FRZCU_7: 8 CGW
 SG_ TirePositionWarning_LHFTire : 18|3@0+ (1,0) [0|7] ""  ICC
 SG_ TirePositionWarning_RHFTire : 21|3@0+ (1,0) [0|7] ""  ICC
 SG_ TirePositionWarning_LHRTire : 26|3@0+ (1,0) [0|7] ""  ICC
 SG_ TirePositionWarning_RHRTire : 29|3@0+ (1,0) [0|7] ""  ICC
 SG_ TirePressureWarningLampSts : 31|2@0+ (1,0) [0|3] ""  ICC
 SG_ TirePressureSystemFailSts : 32|1@0+ (1,0) [0|1] ""  ICC

BO_ 991 TMS_2: 24 CGW
 SG_ TMS_MotorLoopErrorLevel : 126|3@0+ (1,0) [0|7] ""  ICC
 SG_ TMS_BatteryLoopErrorLevel : 123|3@0+ (1,0) [0|7] ""  ICC

BO_ 1188 TMS_3: 32 CGW
 SG_ FrontDeforestDisplaySts : 16|1@0+ (1,0) [0|1] ""  ICC
 SG_ TMS_DisplayActive : 18|1@0+ (1,0) [0|1] ""  ICC
 SG_ TMS_ZoneSelectionDisplaySts : 19|1@0+ (1,0) [0|1] ""  ICC
 SG_ TMS_AutoDisplaySts : 20|1@0+ (1,0) [0|1] ""  ICC
 SG_ TMS_FiltertchangeDisplaySts : 21|1@0+ (1,0) [0|1] ""  ICC
 SG_ TMS_AUTODefrostOnSts : 22|1@0+ (1,0) [0|1] ""  ICC
 SG_ TMS_AUTODefrostDisplaySts : 23|1@0+ (1,0) [0|1] ""  ICC
 SG_ TMS_RefInSufDispSts : 24|1@0+ (1,0) [0|1] ""  ICC
 SG_ TMS_CooltInSufDispSts : 25|1@0+ (1,0) [0|1] ""  ICC
 SG_ TMS_DLOnOffSts : 26|1@0+ (1,0) [0|1] ""  ICC
 SG_ TMS_DROnOffSts : 27|1@0+ (1,0) [0|1] ""  ICC
 SG_ TMS_PLOnOffSts : 28|1@0+ (1,0) [0|1] ""  ICC
 SG_ WorkingSts : 29|1@0+ (1,0) [0|1] ""  ICC
 SG_ TMS_PROnOffSts : 30|1@0+ (1,0) [0|1] ""  ICC
 SG_ TMS_DCOnOffSts : 31|1@0+ (1,0) [0|1] ""  ICC
 SG_ TMS_ACFastCool : 48|1@0+ (1,0) [0|1] ""  ICC
 SG_ TMS_ACFastHeat : 49|1@0+ (1,0) [0|1] ""  ICC
 SG_ TMS_LoveRemind : 50|1@0+ (1,0) [0|1] ""  ICC
 SG_ TMS_InteCleanCar : 51|1@0+ (1,0) [0|1] ""  ICC
 SG_ TMS_ACVentilationSts : 52|1@0+ (1,0) [0|1] ""  ICC
 SG_ TMS_AutoAirCleanSts : 53|1@0+ (1,0) [0|1] ""  ICC
 SG_ PM25Sts : 54|1@0+ (1,0) [0|1] ""  ICC
 SG_ TMS_ACModeCustomSts : 33|2@0+ (1,0) [0|3] ""  ICC
 SG_ TMS_ACRequestDisplaySts : 36|3@0+ (1,0) [0|7] ""  ICC
 SG_ TMS_AUTODefLevelSts : 39|3@0+ (1,0) [0|7] ""  ICC
 SG_ TMS_KeepWarm : 41|2@0+ (1,0) [0|3] ""  ICC
 SG_ TMS_DSwingSts : 44|3@0+ (1,0) [0|7] ""  ICC
 SG_ TMS_PSwingSts : 47|3@0+ (1,0) [0|7] ""  ICC
 SG_ TMS_TuisongDispSts : 58|3@0+ (1,0) [0|7] ""  ICC
 SG_ TMS_SetTemperature_L_C : 63|5@0+ (0.5,15.5) [15.5|30.5] ""  ICC
 SG_ TMS_SetTemperature_R_C : 68|5@0+ (0.5,15.5) [15.5|30.5] ""  ICC
 SG_ TMS_ModeAdjustDisplaySts : 75|4@0+ (1,0) [0|15] ""  ICC
 SG_ TMS_CirculationModeDisplaySts : 79|2@0+ (1,0) [0|3] ""  ICC
 SG_ TMS_IncarTemp : 87|8@0+ (0.5,-40) [-40|85] ""  ICC
 SG_ TMS_FliterLife : 94|7@0+ (1,0) [0|100] ""  ICC
 SG_ TMS_DLSwingUpDwnWPosn : 102|7@0+ (1,0) [0|100] ""  ICC
 SG_ TMS_DLSwingLeRiWPosn : 110|7@0+ (1,0) [0|100] ""  ICC
 SG_ TMS_DRSwingUpDwnWPosn : 118|7@0+ (1,0) [0|100] ""  ICC
 SG_ TMS_DRSwingLeRiWPosn : 126|7@0+ (1,0) [0|100] ""  ICC
 SG_ TMS_PLSwingUpDwnWPosn : 134|7@0+ (1,0) [0|100] ""  ICC
 SG_ TMS_PLSwingLeRiWPosn : 142|7@0+ (1,0) [0|100] ""  ICC
 SG_ TMS_PRSwingUpDwnWPosn : 150|7@0+ (1,0) [0|100] ""  ICC
 SG_ TMS_PRSwingLeRiWPosn : 158|7@0+ (1,0) [0|100] ""  ICC
 SG_ TMS_DCSwingLeRiWPosn : 166|7@0+ (1,0) [0|100] ""  ICC
 SG_ AirSwingSts : 168|1@0+ (1,0) [0|1] ""  ICC
 SG_ TemperatureUnit : 169|1@0+ (1,0) [0|1] ""  ICC
 SG_ BlowAdvanceOnSts : 170|1@0+ (1,0) [0|1] ""  ICC
 SG_ BlowDelayOffSts : 171|1@0+ (1,0) [0|1] ""  ICC
 SG_ TMS_PM25_ExtSts : 172|1@0+ (1,0) [0|1] ""  ICC
 SG_ TMS_PM25_IncarSts : 173|1@0+ (1,0) [0|1] ""  ICC
 SG_ TMS_AQS_Sts : 174|1@0+ (1,0) [0|1] ""  ICC
 SG_ PM25overproofDisplaySts : 175|1@0+ (1,0) [0|1] ""  ICC
 SG_ AQSDisplaySts : 176|1@0+ (1,0) [0|1] ""  ICC
 SG_ PM25AutoRunSts : 177|1@0+ (1,0) [0|1] ""  ICC
 SG_ PM25AutoRunSetSts : 178|1@0+ (1,0) [0|1] ""  ICC
 SG_ FragranceWelcomeModeSts : 179|1@0+ (1,0) [0|1] ""  ICC
 SG_ FragranceDisplaysts : 180|1@0+ (1,0) [0|1] ""  ICC
 SG_ TMS_AQS_Level : 185|2@0+ (1,0) [0|3] ""  ICC
 SG_ ACRequestCommand : 188|3@0+ (1,0) [0|7] ""  ICC
 SG_ PM25_Outcar_Level : 191|3@0+ (1,0) [0|7] ""  ICC
 SG_ PM25_Incar_Level : 194|3@0+ (1,0) [0|7] ""  ICC
 SG_ SetTemperature_L_F : 215|5@0+ (1,63) [63|93] ""  ICC
 SG_ SetTemperature_R_F : 223|5@0+ (1,63) [63|93] ""  ICC
 SG_ TMS_PM25_incar : 231|10@0+ (1,0) [0|1000] ""  ICC
 SG_ TMS_PM25_ext : 237|10@0+ (1,0) [0|1000] ""  ICC
 SG_ TMS_KeepWarmMemoryFb : 243|2@0+ (1,0) [0|3] ""  ICC

BO_ 612 EPB_R_1: 24 CGW
 SG_ Fusa_264_5 : 40|17@0+ (1,0) [0|131071] ""  ICC
 SG_ Fusa_264_4 : 47|6@0+ (1,0) [0|63] ""  ICC
 SG_ Fusa_264_3 : 24|5@0+ (1,0) [0|31] ""  ICC
 SG_ Fusa_264_2 : 16|7@0+ (1,0) [0|127] ""  ICC
 SG_ Fusa_264_1 : 15|4@0+ (1,0) [0|15] ""  ICC
 SG_ EPB_R_1_CRC1 : 7|8@0+ (1,0) [0|255] ""  ICC
 SG_ EPB_R_1_RollgCntr1 : 11|4@0+ (1,0) [0|14] ""  ICC
 SG_ EPB_1_FltLamp : 18|2@0+ (1,0) [0|3] ""  ICC
 SG_ EPB_1_ParkLamp : 20|2@0+ (1,0) [0|3] ""  ICC
 SG_ EPB_1_ActrSt : 23|3@0+ (1,0) [0|7] ""  ICC,DVR
 SG_ EPB_1_RWUSt : 25|1@0+ (1,0) [0|1] ""  ICC
 SG_ EPB_1_TextDisp : 35|4@0+ (1,0) [0|15] ""  ICC
 SG_ IPB_EPBErrorStatus : 41|1@0+ (1,0) [0|1] ""  ICC

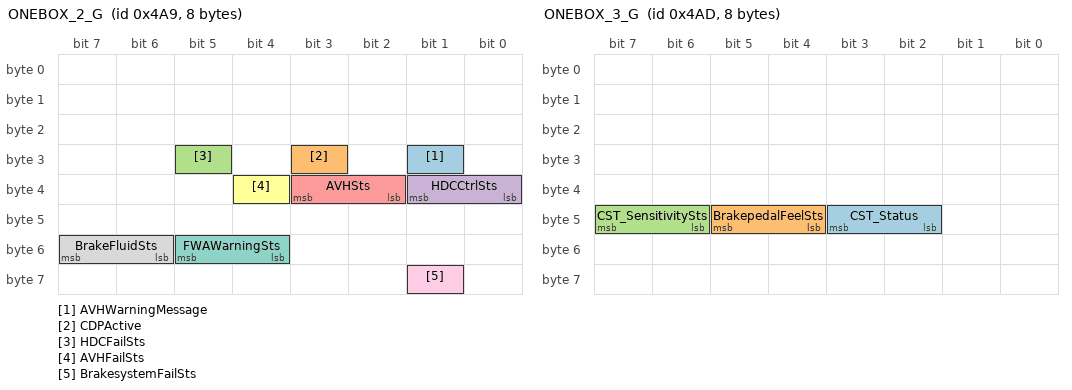
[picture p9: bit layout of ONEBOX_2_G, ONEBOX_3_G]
BO_ 1193 ONEBOX_2_G: 8 CGW
 SG_ AVHWarningMessage : 25|1@0+ (1,0) [0|1] ""  ICC
 SG_ CDPActive : 27|1@0+ (1,0) [0|1] ""  ICC
 SG_ HDCFailSts : 29|1@0+ (1,0) [0|1] ""  ICC
 SG_ HDCCtrlSts : 33|2@0+ (1,0) [0|3] ""  ICC
 SG_ AVHSts : 35|2@0+ (1,0) [0|3] ""  ICC
 SG_ AVHFailSts : 36|1@0+ (1,0) [0|1] ""  ICC
 SG_ FWAWarningSts : 53|2@0+ (1,0) [0|3] ""  ICC
 SG_ BrakeFluidSts : 55|2@0+ (1,0) [0|3] ""  ICC
 SG_ BrakesystemFailSts : 57|1@0+ (1,0) [0|1] ""  ICC

BO_ 1197 ONEBOX_3_G: 8 CGW
 SG_ CST_Status : 43|2@0+ (1,0) [0|3] ""  ICC
 SG_ BrakepedalFeelSts : 45|2@0+ (1,0) [0|3] ""  ICC
 SG_ CST_SensitivitySts : 47|2@0+ (1,0) [0|3] ""  ICC

BO_ 1200 FLZCU_6: 8 CGW
 SG_ EBS_SOC : 7|8@0+ (1,0) [0|100] "%"  ICC

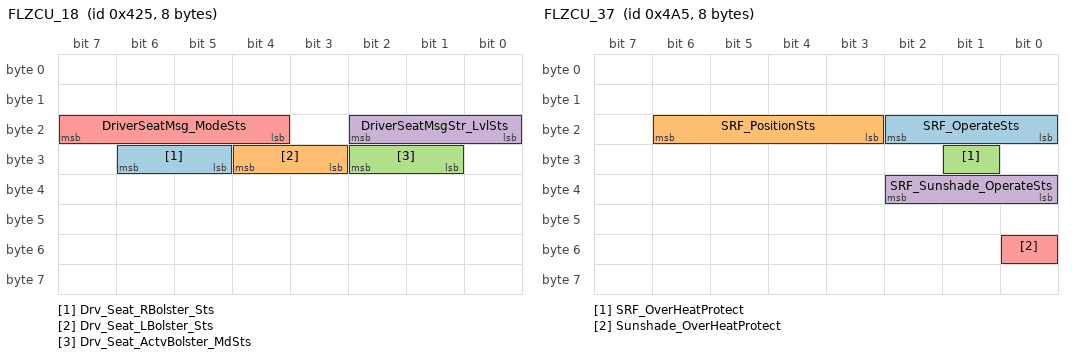
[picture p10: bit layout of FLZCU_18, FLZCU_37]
BO_ 1061 FLZCU_18: 8 CGW
 SG_ Drv_Seat_RBolster_Sts : 30|2@0+ (1,0) [0|3] ""  ICC
 SG_ Drv_Seat_LBolster_Sts : 28|2@0+ (1,0) [0|3] ""  ICC
 SG_ Drv_Seat_ActvBolster_MdSts : 26|2@0+ (1,0) [0|3] ""  ICC
 SG_ DriverSeatMsgStr_LvlSts : 18|3@0+ (1,0) [0|7] ""  ICC
 SG_ DriverSeatMsg_ModeSts : 23|4@0+ (1,0) [0|15] ""  ICC

BO_ 1065 FLZCU_19: 8 CGW
 SG_ LeftSeatMsgStr_LvlSts : 18|3@0+ (1,0) [0|7] ""  ICC
 SG_ LeftSeatMsg_ModeSts : 23|4@0+ (1,0) [0|15] ""  ICC

BO_ 1069 FLZCU_20: 8 CGW
 SG_ PassSeatMsgStr_LvlSts : 18|3@0+ (1,0) [0|7] ""  ICC
 SG_ PassSeatMsg_ModeSts : 23|4@0+ (1,0) [0|15] ""  ICC

BO_ 1087 FLZCU_21: 8 CGW
 SG_ RightSeatMsgStr_LvlSts : 18|3@0+ (1,0) [0|7] ""  ICC
 SG_ RightSeatMsg_ModeSts : 23|4@0+ (1,0) [0|15] ""  ICC

BO_ 1189 FLZCU_37: 8 CGW
 SG_ SRF_OperateSts : 18|3@0+ (1,0) [0|7] ""  ICC
 SG_ SRF_PositionSts : 22|4@0+ (1,0) [0|12] ""  ICC
 SG_ SRF_OverHeatProtect : 25|1@0+ (1,0) [0|1] ""  ICC
 SG_ SRF_Sunshade_OperateSts : 34|3@0+ (1,0) [0|7] ""  ICC
 SG_ Sunshade_OverHeatProtect : 48|1@0+ (1,0) [0|1] ""  ICC

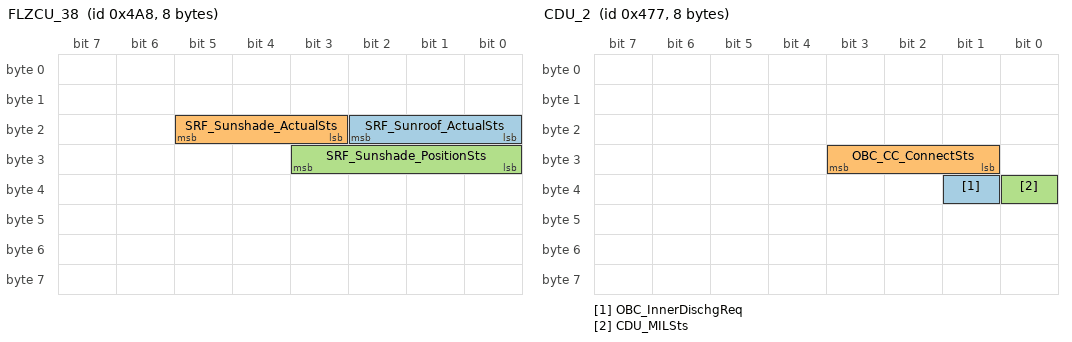
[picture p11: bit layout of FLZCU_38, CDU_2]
BO_ 1192 FLZCU_38: 8 CGW
 SG_ SRF_Sunroof_ActualSts : 18|3@0+ (1,0) [0|7] ""  ICC
 SG_ SRF_Sunshade_ActualSts : 21|3@0+ (1,0) [0|7] ""  ICC
 SG_ SRF_Sunshade_PositionSts : 27|4@0+ (1,0) [0|12] ""  ICC

BO_ 1143 CDU_2: 8 CGW
 SG_ OBC_InnerDischgReq : 33|1@0+ (1,0) [0|1] ""  ICC
 SG_ OBC_CC_ConnectSts : 27|3@0+ (1,0) [0|7] ""  ICC
 SG_ CDU_MILSts : 32|1@0+ (1,0) [0|1] ""  ICC

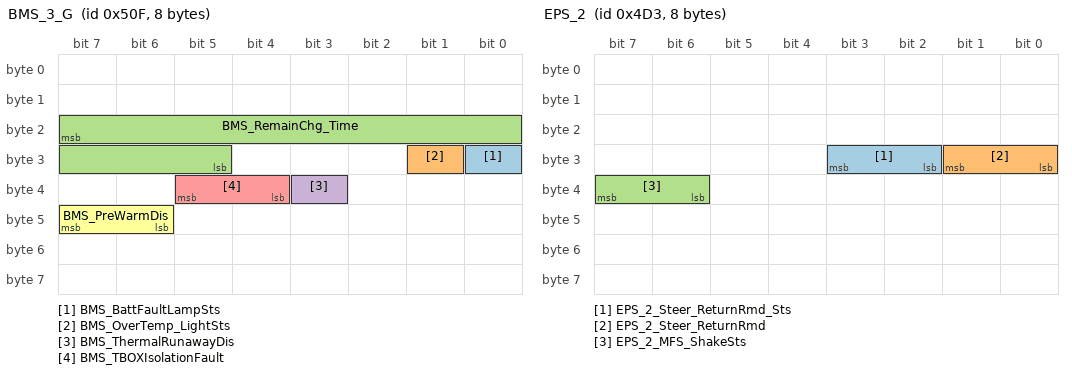
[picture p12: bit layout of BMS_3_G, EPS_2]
BO_ 1295 BMS_3_G: 8 CGW
 SG_ BMS_BattFaultLampSts : 24|1@0+ (1,0) [0|1] ""  ICC
 SG_ BMS_OverTemp_LightSts : 25|1@0+ (1,0) [0|1] ""  ICC
 SG_ BMS_RemainChg_Time : 23|11@0+ (1,0) [0|2047] "min"  ICC
 SG_ BMS_ThermalRunawayDis : 35|1@0+ (1,0) [0|1] ""  ICC
 SG_ BMS_TBOXIsolationFault : 37|2@0+ (1,0) [0|3] ""  ICC
 SG_ BMS_PreWarmDis : 47|2@0+ (1,0) [0|2] ""  ICC

BO_ 1531 BMS_9: 32 CGW
 SG_ BMS_HvBattSoeActDisChaCyc : 23|16@0+ (0.1,0) [0|999.9] "kWh"  ICC
 SG_ BMS_HvBattSoeActReChaCyc : 39|16@0+ (0.1,0) [0|999.9] "kWh"  ICC
 SG_ BMS_HvBattRatedEnergy : 55|14@0+ (0.1,0) [0|999.9] "KW?h"  ICC
 SG_ BMS_HvBattRatedU : 71|14@0+ (0.1,0) [0|999.9] "V"  ICC
 SG_ BMS_HvBattTypeCode : 87|8@0+ (1,0) [0|255] ""  ICC
 SG_ BMS_HvBattManufcCode : 95|32@0+ (1,0) [0|4294967295] ""  ICC
 SG_ BMS_HvBattTempSensorTotalNum : 127|16@0+ (1,0) [0|65534] ""  ICC
 SG_ BMS_HvBattTempSensorTempMaxNum : 143|8@0+ (1,0) [1|250] ""  ICC
 SG_ BMS_HvBattTempSensorTempMinNum : 151|8@0+ (1,0) [1|250] ""  ICC
 SG_ BMS_HvBattTempMaxNum : 159|8@0+ (1,0) [1|250] ""  ICC
 SG_ BMS_HvBattTempMinNum : 167|8@0+ (1,0) [1|250] ""  ICC
 SG_ BMS_BattCellTotalNum : 175|16@0+ (1,0) [0|65531] ""  ICC
 SG_ BMS_HvBattVoltMaxNum : 191|8@0+ (1,0) [1|250] ""  ICC
 SG_ BMS_HvBattVoltMinNum : 199|8@0+ (1,0) [1|250] ""  ICC
 SG_ BMS_ActualSOCMin : 207|12@0+ (0.025,0) [0|100] "%"  ICC
 SG_ BMS_ActualSOCMax : 211|12@0+ (0.025,0) [0|100] "%"  ICC

BO_ 1224 BMS_12: 16 CGW
 SG_ BMS_HvBattCellVoltMax_Num : 23|8@0+ (1,0) [0|250] ""  ICC
 SG_ BMS_HvBattCellVoltMax : 31|16@0+ (0.001,0) [0|15] "V"  ICC
 SG_ BMS_HvBattCellVoltMin_Num : 47|8@0+ (1,0) [0|250] ""  ICC
 SG_ BMS_HvBattCellVoltMin : 55|16@0+ (0.001,0) [0|15] "V"  ICC
 SG_ BMS_Chg_Sts : 87|4@0+ (1,0) [0|15] ""  ICC

BO_ 1235 EPS_2: 8 CGW
 SG_ EPS_2_Steer_ReturnRmd_Sts : 27|2@0+ (1,0) [0|3] ""  ICC
 SG_ EPS_2_Steer_ReturnRmd : 25|2@0+ (1,0) [0|3] ""  ICC
 SG_ EPS_2_MFS_ShakeSts : 39|2@0+ (1,0) [0|3] ""  ICC

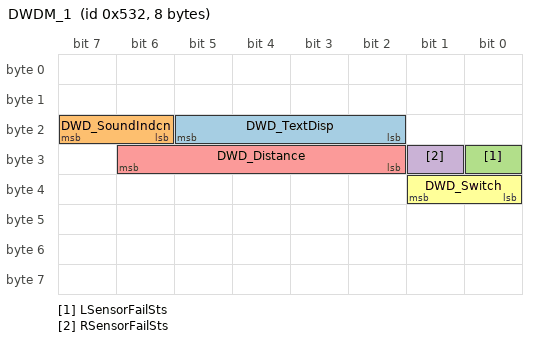
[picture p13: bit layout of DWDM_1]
BO_ 1330 DWDM_1: 8 CGW
 SG_ DWD_TextDisp : 21|4@0+ (1,0) [0|15] ""  ICC
 SG_ DWD_SoundIndcn : 23|2@0+ (1,0) [0|3] ""  ICC
 SG_ LSensorFailSts : 24|1@0+ (1,0) [0|1] ""  ICC
 SG_ RSensorFailSts : 25|1@0+ (1,0) [0|1] ""  ICC
 SG_ DWD_Distance : 30|5@0+ (1,0) [0|31] ""  ICC
 SG_ DWD_Switch : 33|2@0+ (1,0) [0|3] ""  ICC

BO_TX_BU_ 1072 : FLZCU_HCU_IC,FLZCU_IC,FLZCU_Signal_IC;
BO_TX_BU_ 1209 : FLZCU_HCU_IC,HCU_IC;
BO_TX_BU_ 1229 : FLZCU_HCU_IC,HCU_IC;
BO_TX_BU_ 1034 : FLZCU_HCU_IC,HCU_IC;
BO_TX_BU_ 1044 : FLZCU_HCU_IC,HCU_IC;
BO_TX_BU_ 1204 : FLZCU_HCU_IC,HCU_IC;
BO_TX_BU_ 1057 : FLZCU_HCU_IC,HCU_IC;
BO_TX_BU_ 1043 : FLZCU_HCU_IC,FLZCU_Signal_IC;
BO_TX_BU_ 1022 : FLZCU_HCU_IC,FLZCU_IC;
BO_TX_BU_ 1020 : FLZCU_HCU_IC,FLZCU_Signal_IC;
BO_TX_BU_ 1142 : FLZCU_HCU_IC,HCU_IC;
BO_TX_BU_ 1314 : FLZCU_HCU_IC,HCU_IC;
BO_TX_BU_ 1075 : FLZCU_HCU_IC,FLZCU_IC;
BO_TX_BU_ 1136 : FLZCU_HCU_IC,FLZCU_IC;
BO_TX_BU_ 1196 : FLZCU_HCU_IC,FLZCU_Signal_IC;
BO_TX_BU_ 1177 : FLZCU_HCU_IC,FLZCU_IC;
CM_ SG_ 1072 LHTurnlightSts "转向灯（当前可发）";
CM_ SG_ 1072 RHTurnlightSts "转向灯（当前可发）";
CM_ SG_ 1072 LHFdoorSts "主驾门状态（PT3阶段可发）";
CM_ SG_ 1072 LHFSeatBeltSW "安全带检测开关，0为未插入，1为插入";
CM_ SG_ 1072 TrunkSts "（由27E拆帧)";
CM_ SG_ 1072 RLWinPosn "Rear Left Window Position车窗（当前可发）";
CM_ SG_ 1072 SeatHeatLevelsFL "捷途需要改9档";
CM_ SG_ 1072 SeatHeatLevelsRL "捷途需要改9档";
CM_ SG_ 1072 SeatVentLevelsFL "捷途需要改9档";
CM_ SG_ 1072 SeatVentLevelsRL "捷途需要改9档";
CM_ SG_ 1072 FLWinPosn "Front Left Window Position车窗（当前可发）";
CM_ SG_ 1072 FLZCU_FrontWiperMaintenanceSts "前雨刮维修模式开关状态反馈（当前可发）";
CM_ SG_ 1072 FLZCU_RearWiperMaintenanceSts "后雨刮维修模式开关状态反馈（当前可发）";
CM_ SG_ 1209 VCU_2_G_CRC "Profile1A:E2E CRC (SAE J1850 CRC-8) for 8 Bytes
DataID:0x005D";
CM_ SG_ 1209 VCU_2_G_RollgCntr "Profile1A:E2E Rolling message counter(the maximum value of Alive counter is 14)";
CM_ SG_ 1209 VCU_2_G_Resd "Profile1A:E2E Reserved";
CM_ SG_ 1209 VCU_2_G_GasPedalPosInvalidData "油门踏板位置有效位";
CM_ SG_ 1209 VCU_2_G_PowerLimit "power limitation indication功率限制/乌龟灯";
CM_ SG_ 1209 VCU_2_G_BrakeLightReq "break light during regeneration (calibration)制动灯请求";
CM_ SG_ 1209 VCU_2_G_VehicleSystemFailure "vehicle system failure系统故障灯";
CM_ SG_ 1209 VCU_2_G_BootloadSts "0x1:software flash刷写状态（股份信号，D01预留）";
CM_ SG_ 1209 VCU_2_G_DischgSts "ICM indication Discharging state放电状态";
CM_ SG_ 1209 VCU_2_G_BrakePedalStsValidData "制动踏板位置有效位";
CM_ SG_ 1209 VCU_2_G_ExhibitionMod "展厅模式";
CM_ SG_ 1209 VCU_2_G_BrakePedalSts "制动踏板位置";
CM_ SG_ 1209 VCU_2_G_DCDCEnable "DCDC使能";
CM_ SG_ 1209 VCU_2_G_HVReady "HV Ready";
CM_ SG_ 1209 Res_VCU_2_G_Brake_state "break signal
RVM legal request（股份信号，D01预留）";
CM_ SG_ 1209 VCU_2_G_VCUEnergyflow "能量流（股份信号，D01未使用）";
CM_ SG_ 1209 VCU_2_G_DrvGearShiftFailureIndcn "0x0:No Indication；（仪表不显示）
0x1:换挡请踩刹车；（驾驶员期望换挡但没有踩下制动踏板时以此提示驾驶员。触发后驾驶员踩下制动踏板或4s后停发）
0x2:换挡车速过高
0x3:换挡请拔下充电枪（P挡且交流枪连接或直流枪连接时拨动换挡杆）
0x4: EPB无法锁止
0x5: EPB无法释放
0x6: 无法切换行驶方向（车辆D/R挡时EGS通讯丢失）
0x7: 换挡杆需求维修（EGS通讯丢失超过3个驾驶循环或发生故障AllWarningInfo!=0x0）
（股份信号，D01未使用）";
CM_ SG_ 1209 VCU_2_G_GasPedalPosition "Driver/Cruise control
This signal including compositive informations which are actual gas pedal position and dummy Cruise control gas pedal position油门踏板位置";
CM_ SG_ 1229 VCU_CLTC_RangeAval "Remain CLTC available range（CLTC续航里程）";
CM_ SG_ 1229 VCU_DynamicRangeAval "Remain  Dynamic available range动态续航里程（股份信号D01未使用）";
CM_ SG_ 1229 VCU_HighspdRangeAval "Remain highspeed range高速续航里程（股份信号D01未使用）";
CM_ SG_ 1229 VCU_WLTC_RangeAval "Remain WLTC available range（WLTC续航里程）";
CM_ SG_ 1263 VCU_TenECAver "average consumption per ten KM";
CM_ SG_ 1263 VCU_twenty_fiveECAver "average consumption per twenty five KM";
CM_ SG_ 1263 VCU_fiftyECAver "average consumption per fifty KM";
CM_ SG_ 1034 HCU_EmPwr "E-Motor power indication电机功率显示";
CM_ SG_ 1034 HCU_PowerModeFed "Power mode Feedback动力模式反馈";
CM_ SG_ 1034 HCU_PowertrainFault "Powertrain fault动力系统故障";
CM_ SG_ 1034 HCU_PowerModeChangeFail "(Once triggered,send 5 frames 'Active 'immediately, then send 'No active')动力模式切换失败";
CM_ SG_ 1034 HCU_ChargingSts "charge status充电状态指示";
CM_ SG_ 1044 HCU_EnergyFlow "Energy Flow（股份信号D01不使用)";
CM_ SG_ 1044 HCU_SetSOCFed "Set SOC Feedback SOC设置反馈";
CM_ SG_ 1044 HCU_2_G_LowBatteryInfo "No Request  无需显示
Request  弹窗提示“动力电池电量过低，请立即插枪充电或切换到Ready充电”（股份信号D01不使用)";
CM_ SG_ 1204 VCU_1_G_CRC "Profile1A:E2E CRC (SAE J1850 CRC-8) for 8 Bytes
DataID:0x005C";
CM_ SG_ 1204 VCU_1_G_RollgCntr "Profile1A:E2E Rolling message counter(the maximum value of Alive counter is 14)";
CM_ SG_ 1204 VCU_1_G_Pwr "instant power（股份信号D01未使用）";
CM_ SG_ 1204 VCU_1_G_PTReady "PT Ready indication";
CM_ SG_ 1204 VCU_1_G_DriveMode "Driving modes（股份信号D01未使用）";
CM_ SG_ 1204 VCU_1_G_HvBattKeepWarmActiveReq "插枪保温开启请求";
CM_ SG_ 1204 VCU_1_G_PRNDGearAct "Gear indication实际档位";
CM_ SG_ 1057 VCU_TowingMode "上报拖车模式提醒信息";
CM_ SG_ 1057 VCU_EngyConsuPer50Km "最近行驶50Km换算的平均百公里电耗";
CM_ SG_ 1057 VCU_BookChrgSetFailRes "预约失败原因反馈";
CM_ SG_ 1057 VCU_BookChrgFailRes "无法进+AA2082+N20+A2082:AB2082";
CM_ SG_ 1057 VCU_BookChrgStsFb "预约充电状态";
CM_ SG_ 1057 HCU_EngineSelfMaintain "增程发动机自启维护";
CM_ SG_ 1043 EBS_U_BATT "Current measured battery voltage, max value is 18V.Invalid Raw Value:16383.";
CM_ SG_ 1022 FLZCU_CarMode "整车模式";
CM_ SG_ 1022 FLZCU_SteerWhlposSts "管柱电机运行状态
0x0:不工作
0x1:伸长调节中
0x2:缩短调节中
0x3:角度上调中
0x4:角度下调中";
CM_ SG_ 1022 FLZCU_MedStatusFb "冥想模式状态反馈";
CM_ SG_ 1022 FLZCU_MedFailCause "冥想模式开启失败 原因反馈
0x0:Not Active 
0x1:档位非P 档 
0x2:车速≠0km/h 
0x3:前舱盖未关 
0x4:后背门未关 
0x5:左前门未关 
0x6:右前门未关 
0x7:左后门未关 
0x8:右后门未关 
0x9:低压电池电压低，不满足开启条件 
0xA:高压电池电量低，不满足开启条件 
0xB:制动踏板被踩下，不满足开启条件
0xC:电源档位非Comfortable档，不满足开启条件(新增)";
CM_ SG_ 1022 FLZCU_MedAreaFb "冥想模式开启区域设置反馈";
CM_ SG_ 1022 FLZCU_MedClosePrompt "冥想模式关闭提示信号
0x0:Not Active
0x1:低压电池电量低，关闭冥想模式 
0x2:高压电池电量低，关闭冥想模式";
CM_ SG_ 1022 FLZCU_NapArea2Fb "小憩模式开启区域2设置反馈";
CM_ SG_ 1022 FLZCU_2LSeatLvltargetCmd "小憩模式二排左前后设置";
CM_ SG_ 1022 FLZCU_2LSeatBackAgtargetCmd "小憩模式二排左靠背设置";
CM_ SG_ 1022 FLZCU_2LSeatLegSpprttargetCmd "小憩模式二排左腿托设置";
CM_ SG_ 1022 FLZCU_FLWinThermalStatus "左前车窗热保护状态
0：未触发热保护
1：热保护触发中";
CM_ SG_ 1022 FLZCU_RLWinThermalStatus "左后车窗热保护状态
0：未触发热保护
1：热保护触发中";
CM_ SG_ 1022 FLZCU_MonoAmbLigSts "单色氛围灯状态";
CM_ SG_ 1022 FLZCU_LogoChargingSts "前LOGO充电灯效开关状态反馈";
CM_ SG_ 1022 FLZCU_2RSeatLvltargetCmd "小憩模式二排右前后设置";
CM_ SG_ 1022 FLZCU_2RSeatBackAgtargetCmd "小憩模式二排右靠背设置";
CM_ SG_ 1022 FLZCU_2RSeatLegSpprttargetCmd "小憩模式二排右腿托设置";
CM_ SG_ 1022 FLZCU_SeatVentLvlFL2 "主驾座椅通风状态--捷途使用
9档通风给TBOX和ICC";
CM_ SG_ 1022 FLZCU_SeatVentLvlRL2 "二排左侧座椅通风状态--捷途使用
9档通风给TBOX和ICC";
CM_ SG_ 1022 FLZCU_SeatHeatLvlFL2 "主驾座椅加热状态--捷途使用
9档加热给TBOX和ICC";
CM_ SG_ 1022 FLZCU_SeatHeatLvlRL2 "二排左侧座椅加热状态--捷途使用
9档加热给TBOX和ICC";
CM_ SG_ 1022 FLZCU_FLSitPosnSts "主驾座椅记忆位置反馈（含后视镜、管柱）
车机座椅记忆页面有三个位置显示，需新增该信号";
CM_ SG_ 1022 FLZCU_SteerOverHeatWarn "管柱热保护提醒";
CM_ SG_ 1020 BMSH_MaxChgPwrPeak "Maximum Charge Power Peak";
CM_ SG_ 1020 BMSH_MaxDchgPwrPeak "Maximum Discharge Power Peak";
CM_ SG_ 1020 FMCU_8_ISGF_SpdAct "ISG motor actual speed前发电机实际转速";
CM_ SG_ 1020 RMCU_1_Speed "RMCU motor actual speed后驱动电机转速";
CM_ SG_ 1020 CSA_2_AllWarningInfo "EGS全部报警信号
T1C项目，EGS此信号发0x0、0x1、0x4，仪表接收";
CM_ SG_ 1020 RELC_RoofCampLampConfigDisp "车顶生态灯配置显示";
CM_ SG_ 1020 RELC_TopLightConfigDisp "车顶射灯配置显示";
CM_ SG_ 1020 EELC_APillarLightConfigDisp "A柱射灯配置显示";
CM_ SG_ 1020 RELC_RoofCampLampStsL "左侧露营灯状态反馈";
CM_ SG_ 1020 RELC_RoofCampLampStsR "右侧露营灯状态反馈";
CM_ SG_ 1020 RELC_TopLightSts "车顶射灯状态反馈";
CM_ SG_ 1020 EELC_APillarYellowAmbientSts "A柱黄色氛围灯状态反馈";
CM_ SG_ 1020 EELC_APillarWhiteAmbientSts "A柱白色氛围灯状态反馈";
CM_ SG_ 1020 EELC_APillarSpotLampSts "A柱射灯状态反馈";
CM_ SG_ 1020 RMCU_1_TCURErrLvlDis "TCUR故障等级";
CM_ SG_ 1142 HCU_4_G_AvgFuCns "Avg Fuel Consumption
近50km平均百公里油耗 L/100km";
CM_ SG_ 1142 HCU_4_G_AvgEnergyCns "Avg Energy Consumption
近50km平均百公里能耗 L/100km";
CM_ SG_ 1142 HCU_4_G_SumEgyCns "Sum Energy Consumption
自清零后累计百公里能耗 L/100km";
CM_ SG_ 1314 HCU_SumElecCns "自清零后累计百公里电耗显示(仅仪表使用)";
CM_ SG_ 1314 HCU_V2lDisChgBck "V2L外放电开关反馈";
CM_ SG_ 1314 HCU_DisChgMemFed "V2L外放电记忆开关反馈";
CM_ SG_ 1314 HCU_V2VDisChgBck "V2V放电开关反馈";
CM_ SG_ 1314 HCU_V2l_IntlDisChgBck "V2L内放电开关反馈";
CM_ SG_ 1314 HCU_FuelDetnOpDefeated "燃油检测开启失败提示";
CM_ SG_ 1314 HCU_FuelDetnModSwtFed "燃油检测开关反馈";
CM_ SG_ 1314 HCU_FuelDetnStateFed "燃油检测模式状态反馈";
CM_ SG_ 1314 HCU_HVDownRepairModeFed "断高压维修模式开关反馈";
CM_ SG_ 1314 HCU_TrailerMode "被拖模式开关反馈";
CM_ SG_ 1314 HCU_SumFuCns "自清零后累计百公里油耗显示(仅仪表使用)";
CM_ SG_ 1314 HCU_DrivePowerDispSetFed "驱动系统功率显示方式开关反馈";
CM_ SG_ 1314 HCU_KeyDriveModememory "驾驶模式记忆开关反馈";
CM_ SG_ 1314 HCU_DRIFTModeSts "通过大屏设置漂移模式灵敏度开关反馈
0x0:不动作
0x1:入门
0x2:大师
0x3:专家";
CM_ SG_ 1314 HCU_EXPERTEcoFed "专家模式动力设置柔和模式开关反馈";
CM_ SG_ 1314 HCU_4LModeFed "低速四驱开关反馈";
CM_ SG_ 1314 HCU_EXPERTNormFed "专家模式动力设置标准模式开关反馈";
CM_ SG_ 1314 HCU_SingleRegnRmn "当车机收到HCU发送信号“HCU_SingleRegnRmn =0x1”时，弹框提示“单踏板受限已退出，请注意安全驾驶！”，并播放报警音持续3s；
当车机收到HCU发送信号“HCU_SingleRegnRmn=0x0”时，停止提示，并停止报警音；";
CM_ SG_ 1314 HCU_EXPERTSportFed "专家模式动力设置激进模式开关反馈";
CM_ SG_ 1314 HCU_CrossaxisFed "专家模式交叉轴模式开关设置反馈";
CM_ SG_ 1314 HCU_EXPERTRWDFed "专家模式驱动形式后驱开关设置反馈";
CM_ SG_ 1314 HCU_EXPERTAWDFed "专家模式驱动形式四驱开关设置反馈";
CM_ SG_ 1314 HCU_EXPERTAutoFed "专家模式驱动形式Auto开关设置反馈";
CM_ SG_ 1314 HCU_CLIMBFed "防溜设置开关反馈";
CM_ SG_ 1314 HCU_StopChrgnFed "驻车发电开关反馈";
CM_ SG_ 1314 HCU_StopChrgnModeFed "驻车发电模式开关反馈";
CM_ SG_ 1314 HCU_ChrgnFctMemSt "强制保电记忆开关反馈";
CM_ SG_ 1314 HCU_LVPowSupSYSAbn_lit "低压供电系统异常状态";
CM_ SG_ 1314 HCU_IMMOReleaseSignal "防盗报警指示灯信号";
CM_ SG_ 1314 HCU_PowerCut "仪表文字提示“动力即将切断，请靠边停车”";
CM_ SG_ 1314 HCU_ParkingChargeReminder "仪表文字提示“请先驻车再充电”";
CM_ SG_ 1314 HCU_HEV_FunctionLimit "仪表文字提示“HEV模式不可用”";
CM_ SG_ 1314 HCU_SetModeNotChange "仪表文字提示“模式禁止切换”";
CM_ SG_ 1314 HCU_UTURNSnowFed "极限调头雪地场景反馈";
CM_ SG_ 1314 HCU_DriveInhibit_GearP "仪表文字提示“动力受限，进入P挡后无法再次行驶，请尽快联系售后检修”";
CM_ SG_ 1314 HCU_AccleAbility_Limit "仪表文字提示“加速性能受限，请尽快联系售后检修”";
CM_ SG_ 1314 HCU_VehicleSpeedMax_Limit "仪表文字提示“最高车速受限，请尽快联系售后检修”";
CM_ SG_ 1314 HCU_EngineRunClmReq "仪表文字提示“空调请求发动机运行中”";
CM_ SG_ 1314 HCU_DisconnectChagWarn "仪表文字提示“请拔下充电枪”";
CM_ SG_ 1314 HCU_PowerModeChangeInhibit "仪表文字提示“为保障越野性能，模式无法切换”";
CM_ SG_ 1314 HCU_DisChargeStopFault "0x1时仪表文字提示“电池电量过低，放电停止”0x2时仪表文字提示“燃油不足，放电停止”";
CM_ SG_ 1314 HCU_DedicatedModeInhibit "仪表文字提示“当前模式不可用，请切换至越野模式”";
CM_ SG_ 1314 HCU_LeaveVehicleWarning "仪表声音提醒";
CM_ SG_ 1314 HCU_TowingModeEna "大屏被拖提醒文字提示ICC接收
0x1时，大屏文字提示“切换至被拖模式需满足以下条件：1、挡位处于P挡；2、踩下刹车；3、车辆不在充电状态”";
CM_ SG_ 1314 HCU_PowerLevel "仪表驱动能力等级";
CM_ SG_ 1314 HCU_FrntEDLSts "前差速锁状态
0x0: 不锁
0x1: 解锁
0x2：锁止
0x3：切换提醒
0x4：不满足锁止条件
0x5：差速锁无法锁止故障
0x6：差速锁无法解锁故障
0x7：提示需挂入后锁和4L
0x8：提示开启后锁
0x9：提示开启4L";
CM_ SG_ 1314 HCU_RearEDLSts "后差速锁状态
0x0:不锁
0x1:解锁
0x2:锁止
0x3:切换提醒
0x4:不满足锁止条件
0x5:差速锁无法锁止故障
0x6:差速锁无法解锁故障";
CM_ SG_ 1314 HCU_DriveMode_JT "驾驶模式反馈
0x0:经济
0x1:标准
0x2:运动
0x3:雪/草地
0x4:泥地
0x5:越野
0x6:沙地
0x7:岩石
0x8:专家
0x9:智能
0xA:涉水
0xB:极限掉头
0xC:漂移
0xD:拖挂
0xE:越野竞速
0xF~0x1F：预留";
CM_ SG_ 1314 HCU_CruiseLimitSpeedValue "定速巡航设定车速";
CM_ SG_ 1314 HCU_CCOSwtFed "越野蠕行开关反馈";
CM_ SG_ 1314 HCU_SinglePedalMemFed "单踏板记忆开关反馈";
CM_ SG_ 1314 HCU_Pwr "instant_power动力系统瞬时功率";
CM_ SG_ 1314 HCU_SocManageFed "Soc_Manage_Feedback电量模式反馈";
CM_ SG_ 1314 HCU_EgyRegenLevel "power_regeneration_level能量回收等级";
CM_ SG_ 1314 HCU_DrvGearShiftFailureIndcn "换挡失败提醒";
CM_ SG_ 1314 HCU_EXPERTEESPSet "关闭牵引力控制系统&车身稳定控制系统（TCS&VDC_OFF）
全开（TCS、VDC等与ESP有关功能全部开启）
全关（TCS、VDC及RMI放侧翻、DTC发动机拖滞力矩管理）";
CM_ SG_ 1314 HCU_UTURNSandFed "极限调头沙地场景开关反馈";
CM_ SG_ 1314 HCU_CruiseControlStatus "定速巡航指示灯";
CM_ SG_ 1314 HCU_LTCDispFed "续航里程选择开关反馈";
CM_ SG_ 1314 HCU_UTURNMudFed "极限调头泥地场景开关反馈";
CM_ SG_ 1314 HCU_UTURNGrassFed "极限调头草地场景反馈";
CM_ SG_ 1314 HCU_EngyFlowToDisp "能量流显示
0x0：初始化
0x1：无能量流状态
0x2：发动机单独运行
0x3：纯电前驱
0x4：纯电前驱回馈
0x5：纯电后驱
0x6：纯电后驱回馈
0x7：纯电四驱
0x8：纯电四驱回馈
0x9：串联前驱电池充电
0xA：串联前驱电池放电
0xB：串联前驱电池无电流
0xC：串联前驱回馈
0xD：串联后驱电池充电
0xE：串联后驱电池放电
0xF：串联后驱电池无电流
0x10：串联后驱回馈
0x11：串联四驱电池充电
0x12：串联四驱电池放电
0x13：串联四驱电池无电流
0x14：串联四驱回馈
0x15：并联前驱电池充电
0x16：并联前驱电池放电
0x17：并联前驱电池无电流
0x18：并联前驱回馈
0x19：并联四驱电池充电
0x1A：并联四驱电池放电
0x1B：并联四驱电池无电流
0x1C：并联四驱回馈
0x1D：原地发电电池充电
0x1E：原地发电电池放电
0x1F：原地发电电池无电流";
CM_ SG_ 1314 HCU_DriveModeChangeFail "驾驶模式切换不满足条件，提示“请停车后退出当前驾驶模式”";
CM_ SG_ 1314 HCU_iCCO_Warn "越野蠕行功能提示
0x0: 无提示
0x1:请释放EPB
0x2:当前车速过高，请减速
0x3:请关好车门，系好安全带
0x4:请切换至D档开启越野蠕行
0x5:请关闭 APA/ACC/CC巡航
0x6:请退出HDC陡坡缓降
0x7:请手动切换驾驶模式至雪地或泥地或沙地或岩石
0x8:请踩制动踏板
0x9:iCCO越野蠕行已退出";
CM_ SG_ 1314 HCU_iTAS_Warn "极限掉头功能提示
0x0: 无提示
0x1:iTAS功能已激活，无法锁止后桥差速锁
0x2:请释放EPB
0x3:当前车速过高，请减速
0x4：制动盘温度过高，极限掉头功能已退出
0x5：车辆被卡住，极限掉头功能退出
0x6：极限掉头使用时间到达极限，功能退出
0x7：请切换至D档开启极限掉头";
CM_ SG_ 1314 HCU_DraggingModeRemind "拖挂模式功能提示
0x0: 无提示
0x1:禁用ECO和越野模式
0x2:拖挂模式下仅支持Normal和Sport
0x3:ECO和越野模式恢复
0x4~0x7：预留";
CM_ SG_ 1314 HCU_25_EDLFed "中央差速锁显示信号";
CM_ SG_ 1314 HCU_25_Crossaxis_Warn "交叉轴功能提示
0x0: 无提示
0x1:请释放EPB
0x2:当前车速过高，交叉轴功能已退出
0x3:请切换至D档开启交叉轴功能
0x4:请关好车门，系好安全带
0x5:请将车辆静止后踩制动踏板
0x6:进入交叉轴模式后进行空簧高度调节";
CM_ SG_ 1314 HCU_iTAS_Active "极限掉头激活状态（仪表）";
CM_ SG_ 1314 HCU_ExterTempLowHint "环境温度过低提示
0x0:无提示
0x1：环境温度低切换为HEV模式
0x2：环境温度过低发动机运行中";
CM_ SG_ 1314 HCU_25_iTAS_SlopWarn "极限调头坡度条件不满足提醒
0x0:无提示
0x1:地面坡度过大
0x2~0x3:Reserved";
CM_ SG_ 1314 HCU_iTASSceneReq "iTAS场景选择信息";
CM_ SG_ 1314 HCU_DrivingModReq "HCU给IPB映射驾驶模式";
CM_ SG_ 1314 HCU_25_VehSpdOffroadRmn "漂移，掉头，专家，交叉轴，越野蠕行，越野竞速功能，用户在车辆未静止状态下点退出按钮或硬开关，仪表接收该信号0x1后显示“请将车辆禁止后再设置”";
CM_ SG_ 1314 HCU_25_LaunchMod_Warn "越野竞速弹射模式弹窗提示
0x0:无提示
0x1:弹射模式已激活，松开制动踏板，开始弹射
0x2:弹射模式已退出
0x3:条件不满足，弹射模式不可用
0x4~0x7:Reserved";
CM_ SG_ 1314 HCU_25_SetVehSpdOffroad "越野模式切换车速条件不满足提示
0x0:无提示
0x1:请将车辆静止后再设置
0x2~0x3:Reserved";
CM_ SG_ 1314 HCU_25_iDRIFT_Warn "漂移模式功能提示
0x0:无提示
0x1:请关好车门，系好安全带
0x2:请将车辆停止
0x3:系统故障，漂移模式暂无法开启
0x4:进入漂移模式后进行空簧高度调节";
CM_ SG_ 1314 HCU_25_TAB_Warn "TAB功能提醒（T1J Fl2华为智驾项目使用）";
CM_ SG_ 1314 HCU_25_CCO_TextDisp "CC0功能提示信息
越野蠕行功能提示";
CM_ SG_ 1136 VCC_3_CRC "Profile1A:E2E CRC (SAE J1850 CRC-8) for 32 Bytes
DataID:0x0070";
CM_ SG_ 1136 VCC_3_RollgCntr "Profile1A:E2E Rolling message counter(the maximum value of Alive counter is 14)";
CM_ SG_ 1136 VCC_3_Resd1 "Profile1A:E2E Reserved";
CM_ SG_ 1136 VCC_3_SN "Message ID信号值.当VCC成功被写入配置信息时，VCC以100ms的周期滚动发送报文，Message ID信号值从1到32循环发送。";
CM_ SG_ 1196 TDL_SwitchSts "氛围灯开关状态反馈";
CM_ SG_ 1196 TDL_ColourModeSts "氛围灯颜色模式反馈";
CM_ SG_ 1196 TDL_RhythmSwSts "氛围灯音乐律动状态反馈";
CM_ SG_ 1196 TDL_ApiluminanceSts "氛围灯亮度反馈";
CM_ SG_ 1196 TDL_VioceFunctionDone "语音唤醒功能反馈";
CM_ SG_ 1196 TDL_FlowLightSwSts "流水灯开关状态反馈";
CM_ SG_ 1196 TDL_FlowLightModeSts "流水灯模式状态反馈";
CM_ SG_ 1196 TDL_RhythmModeSts "音乐律动模式反馈";
CM_ SG_ 1196 TDL_256ColourSts "多元颜色状态反馈";
CM_ SG_ 1177 FuelTankLidSts "加油小门开关状态";
CM_ SG_ 1177 FuelTankLidLockFailureSts "加油小门门锁故障状态";
CM_ SG_ 1177 FuelTankLidSensorFailureSts "油箱门位置传感器故障信号";
CM_ SG_ 1109 CWC_1_CRC1 "Profile1A:E2E CRC (SAE J1850 CRC-8) for 8 Bytes
DataID:No ASIL requirements.Not configure
CRC Reserved.";
CM_ SG_ 1109 CWC_1_RollgCntr1 "Profile1A:E2E Rolling message counter(the maximum value of Alive counter is 14)";
CM_ SG_ 1109 CWC_1_Resd1 "Profile1A:E2E Reserved";
CM_ SG_ 1109 CWC_ChargingSts "无线充电器充电状态(DVD接收显示)
0x0: 没有充电
0x1: 充电中
0x2: 充电完成
0x3：充电故障";
CM_ SG_ 1109 CWC_workingSts "无线充电器工作状态(DVD接收显示)
0x0: 无线充电器关闭
0x1: 无线充电器打开";
CM_ SG_ 1109 CWC_Phoneforgotten "手机是否遗忘在无线充电器上(DVD接收驱动手机遗忘报警)
0x0:手机没有遗忘
0x1:手机遗忘提醒";
CM_ SG_ 1109 CWC_Phoneforgotten_ON_OFF_Sts "手机遗忘提醒功能是否打开
0x0:功能关闭
0x1:功能打开";
CM_ SG_ 1109 CWC_1_ChrgFlt "无线充电器充电故障
charge fault
0x5:NFC_card_protect_L(左舵车，右侧信号无效)";
CM_ SG_ 1109 CWC_ChargingSts_R "无线充电器充电状态(DVD接收显示)
0x0: 副驾手机没有充电
0x1: 副驾手机充电中
0x2: 副驾手机充电完成
0x3：副驾手机充电故障";
CM_ SG_ 1109 CWC_workingSts_R "无线充电器工作状态(DVD接收显示)
0x0: 副驾无线充电器关闭
0x1: 副驾无线充电器打开";
CM_ SG_ 1109 CWC_Phoneforgotten_R "手机是否遗忘在无线充电器上(DVD接收驱动手机遗忘报警)
0x0:副驾手机没有遗忘
0x1:副驾手机遗忘提醒";
CM_ SG_ 1109 CWC_Phoneforgotten_ON_OFF_Sts_R "副驾手机遗忘提醒功能是否打开
0x0:功能关闭
0x1:功能打开";
CM_ SG_ 1109 CWC_1_ChrgFlt_R "副驾手机无线充电器充电故障
charge fault
0x5:NFC_card_protect_R(右舵车，左侧信号无效)";
CM_ SG_ 1231 TBOX_1_BookChrgActiveReq "起始充电时间到/请求充电;
VCU/IHU收服务化信号，TBOX同步转成CAN信号BNCM收；";
CM_ SG_ 1231 TBOX_BookChrgSts "预约充电状态";
CM_ SG_ 1231 TBOX_HvBattKeepWarmActiveReq "电池保温请求";
CM_ SG_ 1231 TBOX_BookChrgSetReq "TBOX预约充电开启/取消设置请求";
CM_ SG_ 1231 TBOX_StopChrgReq "结束充电请求";
CM_ SG_ 1231 TBOX_KeepWarmSet "TBOX插枪保温设置";
CM_ SG_ 1231 TBOX_HV_Req "TBOX远程高压上下电";
CM_ SG_ 1288 CurrentTimeYear "GPS时间（年）";
CM_ SG_ 1288 CurrentTimeMonth "GPS时间（月）";
CM_ SG_ 1288 CurrentTimeDay "GPS时间（日）";
CM_ SG_ 1288 CurrentTimeHour "GPS时间（时）";
CM_ SG_ 1288 CurrentTimeMinute "GPS时间（分）";
CM_ SG_ 1288 CurrentTimeSecond "GPS时间（秒）";
CM_ SG_ 1063 TBOX_PetmodeSwitch "宠物模式远程开关信号";
CM_ SG_ 1148 TBOX_BkChrgStartTimeDay "预约充电开始时间设置-日";
CM_ SG_ 1148 TBOX_BkChrgStartTimeeHour "预约充电开始时间设置-时";
CM_ SG_ 1148 TBOX_BkChrgStartTimeMin "预约充电开始时间设置-分";
CM_ SG_ 1148 TBOX_GPSSwitchSts "GPS定位开关设置";
CM_ SG_ 1148 TBOX_BkChrgStartTimeMonth "预约充电开始时间设置-月";
CM_ SG_ 1148 TBOX_BkChrgStartTimeYear "预约充电开始时间设置-年";
CM_ SG_ 1148 TBOX_BkChrgDuration "远程预约充电时长设置";
CM_ SG_ 1148 TBOX_BkChrgCycleType "远程预约充电周期循环方式";
CM_ SG_ 1148 TBOX_BkChrgCycleMon "预约充电周期循环_每周一循环";
CM_ SG_ 1148 TBOX_BkChrgCycleTues "预约充电周期循环_每周二循环";
CM_ SG_ 1148 TBOX_BkChrgCycleWen "预约充电周期循环_每周三循环";
CM_ SG_ 1148 TBOX_BkChrgCycleThur "预约充电周期循环_每周四循环";
CM_ SG_ 1148 TBOX_BkChrgCycleFri "预约充电周期循环_每周五循环";
CM_ SG_ 1148 TBOX_BkChrgCycleSat "预约充电周期循环_每周六循环";
CM_ SG_ 1148 TBOX_BkChrgCycleSun "预约充电周期循环_每周日循环";
CM_ SG_ 1148 TBOX_KeepWarmStrt "插枪保温开始时间设置-日";
CM_ SG_ 1148 TBOX_KeepWarmStrtHour "插枪保温开始时间设置-时";
CM_ SG_ 1148 TBOX_KeepWarmStrtMin "插枪保温开始时间设置-分";
CM_ SG_ 1162 ONEBOX_1_G_CRC "Profile1A:E2E CRC (SAE J1850 CRC-8) for 8 Bytes
DataID:0x0056";
CM_ SG_ 1162 ONEBOX_1_G_RollgCntr "Profile1A:E2E Rolling message counter(the maximum value of Alive counter is 14)";
CM_ SG_ 1162 VehicleSpeedVSOSig "Vehicle Speed";
CM_ SG_ 1162 VehicleSpeedVSOSigValidData "Valid check bit of the signal VehicleSpeedVSOSig";
CM_ SG_ 1162 ESPSwitchStatus "“1” means VDC and Engine Traction Control System (PTC) Function and Brake Traction Control System (BTC) Function disabled and Ignit ESP lamp.";
CM_ SG_ 1162 ABSActive "ABS Active";
CM_ SG_ 1162 ABSFailSts "ABS Fail Status";
CM_ SG_ 1162 EBDFailSts "EBD Fail Status";
CM_ SG_ 1162 TCSFailSts "After IGN OFF, this signal should be set to 0 for avoiding ICM ESP warning.";
CM_ SG_ 1162 VDCFailSts "After IGN OFF, this signal should be set to 0 for avoiding ICM ESP warning.";
CM_ SG_ 1162 TCSActive "TCS Active";
CM_ SG_ 1162 VDCActive "VDC Active";
CM_ SG_ 1162 BLRequestController "BL Request Controller";
CM_ SG_ 1202 FuelRollingCounter "Instantaneous fuel consumption pulse signal
瞬时油耗脉冲信号";
CM_ SG_ 1202 MILSts "MIL Status";
CM_ SG_ 1202 GPFWarning "This signal indicates the status of GPF warning which need ICM to  inform driver. 
0x1: Green light, may display 'GPF is full. Need  highspeed road drive to clean GPF”
0x2: Yellow light, may display'GPF is overlimited. Need to contact 4s to check and repair GPF'";
CM_ SG_ 1202 EngineSpeed "Engine Speed
PHEV上此信号发送真实转速（给BCM使用）";
CM_ SG_ 1202 EngineSpeedValidData "Valid check bit of the signal EngineSpeed";
CM_ SG_ 1202 EPCSts "EPC status";
CM_ SG_ 1202 EMS_1_G_EngineSts "Engine Status
If this value is 1, indicate that  the engine is started successfully. 
在PHEV上，此信号发送模拟的发动机状态；";
CM_ SG_ 1202 EMS_EngineSts_Actual "PHEV上，根据发动机真实的状态发送";
CM_ SG_ 1202 OilPressureWarningLamp "Oil Pressure Worning Lamp
机油压力报警灯";
CM_ SG_ 683 FRZCU_1_ParkLightSts "位置灯状态";
CM_ SG_ 683 FRWinPosn "Front_Right_Window_Position";
CM_ SG_ 683 RRWinPosn "Rear_Right_Window_Position";
CM_ SG_ 33 ACU_3_LongitudinalAcceleration "Longitudinal acceleration signal
Sensor accuracy：0.0027680342857143 g";
CM_ SG_ 33 ACU_3_LongitudinalAccelerationVD "If hasn’t been calibrated, after initialization, this signal ‘s value is always10(invalid)";
CM_ SG_ 632 EngineCoolantTemperature "Engine coolant temperture
发动机水温";
CM_ SG_ 1217 ASU_1_ASUSysFailrSts "ASU System failure state.";
CM_ SG_ 1217 ASU_1_SuspCurrentLvl "Suspension Current High Level
0x0：无效
0x1：非常高的等级
0x2：介于非常高和高的等级之间
0x3：高等级
0x4：介于高等级和正常等级之间
0x5：正常等级
0x6：介于正常和低等级之间
0x7：低等级
0x8：介于低等级和极低等级之间
0x9：非常低的等级
0xA：方便上下车高度等级
0xB：便利装载高度等级
0xC~0xF：预留";
CM_ SG_ 1217 ASU_1_ECASSysSts "ECAS System State";
CM_ SG_ 1217 ASU_1_ECASErrSts "ECAS Error Status";
CM_ SG_ 1217 ASU_1_SuspTarLvl "Suspension Target High Level
0x0：无要求
0x1：非常高的等级
0x2：高等级
0x3：正常等级
0x4：低等级
0x5：非常低的等级
0x6：方便上下车高度等级
0x7：便利装载高度等级";
CM_ SG_ 1217 ASU_1_EasyEntryEna "easy Entry Enable.";
CM_ SG_ 1217 ASU_1_CDCErrSts "CDC error Satus";
CM_ SG_ 1217 ASU_1_RearaxlewithTaildoorFb "自动便利装载";
CM_ SG_ 1217 ASU_1_Overheat_warning "空气弹簧过热保护提示";
CM_ SG_ 1217 ASU_1_MaintainMod "indicate the AirSuspension is in maintain mode or not.";
CM_ SG_ 1217 ASU_1_drivemodeheightlevFb "高度调节与驾驶模式关联反馈";
CM_ SG_ 1217 ASU_1_HMIFailFb "ASU HMI failure feedback
悬架人机交互失效反馈";
CM_ SG_ 1217 ASU_1_AssistPass "Assist in passing feedback
辅助通过反馈";
CM_ SG_ 258 BMS_1_CRC1 "Profile1A:E2E CRC (SAE J1850 CRC-8) for 8 Bytes
DataID:0x0014";
CM_ SG_ 258 BMS_1_RollgCntr1 "Profile1A:E2E Rolling message counter(the maximum value of Alive counter is 14)";
CM_ SG_ 258 BMS_1_Resd1 "Profile1A:E2E Reserved";
CM_ SG_ 258 BMS_PackVoltage "Battery Voltage";
CM_ SG_ 258 BMS_PackCurrent "Baattery Current(direction:discharge+ charge -)";
CM_ SG_ 258 BMS_HvBattSts "Battery State";
CM_ SG_ 258 BMS_SysSelfCheck "BMS Slef Check State";
CM_ SG_ 258 BMS_HVBattThermRunaway "Thermal Run-away";
CM_ SG_ 258 BMS_1_CRC2 "Profile1A:E2E CRC (SAE J1850 CRC-8) for 8 Bytes
DataID:No ASIL requirements.Not configure
CRC Reserved.";
CM_ SG_ 258 BMS_1_RollgCntr2 "Profile1A:E2E Rolling message counter(the maximum value of Alive counter is 14)";
CM_ SG_ 258 BMS_1_Resd2 "Profile1A:E2E Reserved";
CM_ SG_ 258 BMS_ChargeVoltageReq "Chagre Voltage Request indiction(only for BMS internal analysis)";
CM_ SG_ 258 BMS_ChgCurrReq "Chagre Current Request t indiction(only for BMS internal analysis)";
CM_ SG_ 258 BMS_InfraDcUActDc "DC-charge station actual ouput voltage(only for BMS internal analysis)";
CM_ SG_ 258 BMS_1_CRC3 "Profile1A:E2E CRC (SAE J1850 CRC-8) for 8 Bytes
DataID:0x0015";
CM_ SG_ 258 BMS_1_RollgCntr3 "Profile1A:E2E Rolling message counter(the maximum value of Alive counter is 14)";
CM_ SG_ 258 BMS_1_Resd3 "Profile1A:E2E Reserved";
CM_ SG_ 258 BMS_InfraDcIActDc "DC-charge station actual ouput current(only for BMS internal analysis)";
CM_ SG_ 258 BMS_HvBattDynChrgnILim "battery chagre current limit";
CM_ SG_ 258 BMS_HvBattUChrgnLim "battery chagre voltage limit";
CM_ SG_ 258 BMS_1_CRC4 "Profile1A:E2E CRC (SAE J1850 CRC-8) for 8 Bytes
DataID:0x0016";
CM_ SG_ 258 BMS_1_RollgCntr4 "Profile1A:E2E Rolling message counter(the maximum value of Alive counter is 14)";
CM_ SG_ 258 BMS_1_Resd4 "Profile1A:E2E Reserved";
CM_ SG_ 258 BMS_DChrgAPlusSt "DC A+ status";
CM_ SG_ 258 BMS_ChrgDcIAvl "DC-charge station charging current limit";
CM_ SG_ 258 BMS_Insulation_R "insulation resistance";
CM_ SG_ 258 BMS_ChrgDcCnctrDetd "CC2 connect state";
CM_ SG_ 258 BMS_DCChgMode "DC charge mode";
CM_ SG_ 258 BMS_ChrgDcChrgnFltStopReas "Dc charge stop reason";
CM_ SG_ 258 BMS_1_CRC5 "Profile1A:E2E CRC (SAE J1850 CRC-8) for 8 Bytes
DataID:0x0017";
CM_ SG_ 258 BMS_1_RollgCntr5 "Profile1A:E2E Rolling message counter(the maximum value of Alive counter is 14)";
CM_ SG_ 258 BMS_1_Resd5 "Profile1A:E2E Reserved";
CM_ SG_ 258 BMS_ChargeRequest_Mode "charge request mode";
CM_ SG_ 258 BMS_ChgRemTime "remain charging time";
CM_ SG_ 258 BMS_1_StateOfChargeDis "battery indication SOC";
CM_ SG_ 258 BMS_StateOfEnergy "battery SOE";
CM_ SG_ 258 BMS_1_CRC6 "Profile1A:E2E CRC (SAE J1850 CRC-8) for 8 Bytes
DataID:0x0018";
CM_ SG_ 258 BMS_1_RollgCntr6 "Profile1A:E2E Rolling message counter(the maximum value of Alive counter is 14)";
CM_ SG_ 258 BMS_1_Resd6 "Profile1A:E2E Reserved";
CM_ SG_ 258 BMS_StateOfHealth "battery SOH";
CM_ SG_ 258 BMS_BlanceState "battery balance state";
CM_ SG_ 258 BMS_IsolationFault "battery insulation fault state";
CM_ SG_ 258 BMS_HVILFault_DC "DC internal HVIL fault
捷途使用该信号发送BMS电池包内部高压互锁故障状态";
CM_ SG_ 258 BMS_HVILFault_FMCU "FMCU internal HVIL fault
捷途使用该信号发送BMS电池包前端高压互锁故障状态";
CM_ SG_ 258 BMS_HVILFault_RMCU "RMCU internal HVIL fault
捷途使用该信号发送BMS电池包后端高压互锁故障状态";
CM_ SG_ 258 BMS_SOCDis "battery indication SOC";
CM_ SG_ 258 BMS_InfraDcIActDcMin "DC-charge station actual ouput current(only for BMS internal analysis)";
CM_ SG_ 1290 BMS_8_CRC1 "Profile1A:E2E CRC (SAE J1850 CRC-8) for 8 Bytes
DataID:0x0023";
CM_ SG_ 1290 BMS_8_RollgCntr1 "Profile1A:E2E Rolling message counter(the maximum value of Alive counter is 14)";
CM_ SG_ 1290 BMS_8_Resd1 "Profile1A:E2E Reserved";
CM_ SG_ 1290 BMS_HvBattCellOverU "battey cell over voltage fault";
CM_ SG_ 1290 BMS_HvBattCellUnderU "battey cell under voltage fault";
CM_ SG_ 1290 BMS_HvBattUnderU "battey over voltage fault";
CM_ SG_ 1290 BMS_HvBattDischargeOverCurrent "dischagre over current";
CM_ SG_ 1290 BMS_HvBattChargeOverCurrent "chagre over current";
CM_ SG_ 1290 BMS_HvBattOverU "battey under voltage fault";
CM_ SG_ 1290 BMS_HvBattMismatching "battery system dis-match";
CM_ SG_ 1290 BMS_HvBattSocJump "battery SOC jump";
CM_ SG_ 1290 BMS_HvBattCellUUnif "battery cell voltage difference fault";
CM_ SG_ 1290 BMS_HvBattLowSoc "SOC too low";
CM_ SG_ 1290 BMS_HvBattOverSoc "SOC too high";
CM_ SG_ 1290 BMS_HvBattTempUniformity "battery temperature difference fault";
CM_ SG_ 1290 BMS_BattInterCANErr "BMS inter CAN fault";
CM_ SG_ 1290 BMS_HvBattOverCharging "battery over charge";
CM_ SG_ 1290 BMS_HvBattOverTemperature "battery over temperature";
CM_ SG_ 1163 FMCU_SysTempOvrInd "Indicator of overheat warning lamp前驱动电机控制器过温报警灯";
CM_ SG_ 1316 LHFTireTemperature "左前轮胎温度";
CM_ SG_ 1316 RHFTireTemperature "右前轮胎温度";
CM_ SG_ 1316 LHRTireTemperature "左后轮胎温度";
CM_ SG_ 1316 LHFTirePressure "左前轮胎胎压";
CM_ SG_ 1316 RHFTirePressure "右前轮胎胎压";
CM_ SG_ 1316 LHRTirePressure "左后轮胎胎压";
CM_ SG_ 1316 RHRTirePressure "左后轮胎胎压";
CM_ SG_ 1316 RHRTireTemperature "右后轮胎温度";
CM_ SG_ 1324 TirePositionWarning_LHFTire "左前方位轮胎胎压报警，含快速失压、低压、高压、高温。";
CM_ SG_ 1324 TirePositionWarning_RHFTire "右前方位轮胎胎压报警，含快速失压、低压、高压、高温。";
CM_ SG_ 1324 TirePositionWarning_LHRTire "左后方位轮胎胎压报警，含快速失压、低压、高压、高温。";
CM_ SG_ 1324 TirePositionWarning_RHRTire "右后方位轮胎胎压报警，含快速失压、低压、高压、高温。";
CM_ SG_ 1324 TirePressureWarningLampSts "胎压报警灯状态，含熄灭、闪烁（快速失压）、常亮（低压）三种状态";
CM_ SG_ 1324 TirePressureSystemFailSts "胎压系统故障";
CM_ SG_ 991 TMS_MotorLoopErrorLevel "Motor Loop Error Level
电驱回路故障等级";
CM_ SG_ 991 TMS_BatteryLoopErrorLevel "Battery Loop Error Level
电池回路故障等级";
CM_ SG_ 1188 FrontDeforestDisplaySts "前除霜工作指示灯
0x0:Off
0x1:On";
CM_ SG_ 1188 TMS_DisplayActive "空调信息显示状态
CLM检测到有面板击键或DVD控制命令，则发送active-1，DVD切屏显示空调信息；如果10秒没有检测到击键或命令，空调发_not_active-0，DVD停止显示空调信息；";
CM_ SG_ 1188 TMS_ZoneSelectionDisplaySts "Zone_Display_Status
空调温区状态显示";
CM_ SG_ 1188 TMS_AutoDisplaySts "Auto_Display_Status
空调自动状态显示";
CM_ SG_ 1188 TMS_FiltertchangeDisplaySts "Filter_replacement_reminder
滤芯重置提示";
CM_ SG_ 1188 TMS_AUTODefrostOnSts "AutoDefrost_Status
自动除雾开关状态";
CM_ SG_ 1188 TMS_AUTODefrostDisplaySts "When_the_AC_is_turned_on,_the_automatic_defogging_function_is_turned_on,_and_sends_this_signal
自动除雾工作状态";
CM_ SG_ 1188 TMS_RefInSufDispSts "Refrigerant_Insufficient_Display_Status
冷媒不足弹窗提醒";
CM_ SG_ 1188 TMS_CooltInSufDispSts "coolant_Insufficient_Display_Status
冷却液不足弹窗提醒";
CM_ SG_ 1188 TMS_DLOnOffSts "Driver_Left_On_Off_Status
主驾左出风口开关状态";
CM_ SG_ 1188 TMS_DROnOffSts "Driver_Right_On_Off_Status
主驾右出风口开关状态";
CM_ SG_ 1188 TMS_PLOnOffSts "Passenger_Left_On_Off_Status
副驾左出风口开关状态";
CM_ SG_ 1188 WorkingSts "Not_active-关闭空调
Active--打开空调
0x0:Off
0x1:On";
CM_ SG_ 1188 TMS_PROnOffSts "Passenger_Right_On_Off_Status
副驾右出风口开关状态";
CM_ SG_ 1188 TMS_DCOnOffSts "Driver_Center_On_Off_Status
中上出风口开关状态";
CM_ SG_ 1188 TMS_ACFastCool "AC_Fast_Cooling_Working_Status
空调极速降温工作状态";
CM_ SG_ 1188 TMS_ACFastHeat "AC_Fast_Heating_Working_Status
空调快速升温工作状态";
CM_ SG_ 1188 TMS_LoveRemind "Love_Remind_Working_Status
爱心提醒工作状态";
CM_ SG_ 1188 TMS_InteCleanCar "Intelligent_Clean_Car_Working_Status
智能除味工作状态";
CM_ SG_ 1188 TMS_ACVentilationSts "AC_Ventilation_Working_Status
新风系统通风状态";
CM_ SG_ 1188 TMS_AutoAirCleanSts "Auto_Air_Clean_Status
座舱自动清洁设置项状态";
CM_ SG_ 1188 PM25Sts "PM2.5_Status
0x0:Off
0x1:On";
CM_ SG_ 1188 TMS_ACModeCustomSts "AC_custom_mode_status_feedback
空调定制模式状态反馈";
CM_ SG_ 1188 TMS_ACRequestDisplaySts "AC请求指示
压缩机状态显示信号,和发给EMS的AC请求信号需区分开";
CM_ SG_ 1188 TMS_AUTODefLevelSts "AUTO_Defrost_Level_Status
自动除雾等级信息";
CM_ SG_ 1188 TMS_KeepWarm "Keep_Warm_Working_Status
恒温模式工作状态";
CM_ SG_ 1188 TMS_DSwingSts "Driver_Air_Swing_Mode_Status
主驾扫风模式显示";
CM_ SG_ 1188 TMS_PSwingSts "Passenge_rAir_Swing_Mode_Status
副驾扫风模式显示";
CM_ SG_ 1188 TMS_TuisongDispSts "Tuisong_Display_Status
不当操作体现";
CM_ SG_ 1188 TMS_SetTemperature_L_C "在单区模式下，调节左旋钮可以同时设定左右两边的温度设定。在双区模式下，左旋钮设定左区温度，右旋钮设定右区温度。
DVD未收到设定温值时，以及收到设定温值为startup_对应的1F时，DVD屏幕上温度显示区域均显示空白。";
CM_ SG_ 1188 TMS_ModeAdjustDisplaySts "Blower_Mode_Display_Status
出风模式现实状态";
CM_ SG_ 1188 TMS_CirculationModeDisplaySts "Circulation_Mode_Status
循环风门状态";
CM_ SG_ 1188 TMS_IncarTemp "Incar_Temperature
车内温度";
CM_ SG_ 1188 TMS_FliterLife "Fliter_Life
滤芯寿命";
CM_ SG_ 1188 TMS_DLSwingUpDwnWPosn "Driver_Left_Swing_Up_Down_Working_Position
主驾左上下扫风电机工作位置";
CM_ SG_ 1188 TMS_DLSwingLeRiWPosn "Driver_Left_Swing_Left_Right_Working_Position
主驾左左右扫风电机工作位置";
CM_ SG_ 1188 TMS_DRSwingUpDwnWPosn "Driver_Right_Swing_Up_Down_Working_Position
主驾右上下扫风电机工作位置";
CM_ SG_ 1188 TMS_DRSwingLeRiWPosn "Driver_Right_Swing_Left_Right_Working_Position
主驾右左右扫风电机工作位置";
CM_ SG_ 1188 TMS_PLSwingUpDwnWPosn "Passenger_Left_Swing_Up_Down_Working_Position
副驾左上下扫风电机工作位置";
CM_ SG_ 1188 TMS_PLSwingLeRiWPosn "Passenger_Left_Swing_Left_Right_Working_Position
副驾左左右扫风电机工作位置";
CM_ SG_ 1188 TMS_PRSwingUpDwnWPosn "Passenger_Right_Swing_Up_Down_Working_Position
副驾右上下扫风电机工作位置";
CM_ SG_ 1188 TMS_PRSwingLeRiWPosn "Passenger_Right_Swing_Left_Right_Working_Position
副驾右左右扫风电机工作位置";
CM_ SG_ 1188 TMS_DCSwingLeRiWPosn "Driver_Center_Swing_Left_Right_Working_Position
主驾中上左右扫风电机工作位置";
CM_ SG_ 1188 AirSwingSts "Air_Swing_Status
扫风状态显示";
CM_ SG_ 1188 BlowAdvanceOnSts "Blower_Advance_On_Status
鼓风机提前通风运行状态";
CM_ SG_ 1188 BlowDelayOffSts "Blower_Delay_Off_Status
鼓风机延迟关闭状态";
CM_ SG_ 1188 TMS_PM25_ExtSts "External_PM2.5_sensor_fault_signal,_send_0X1_to_indicate_short_circuit_or_open_circuit_fault
车外PM2.5传感器故障状态";
CM_ SG_ 1188 TMS_PM25_IncarSts "Incar_PM2.5_sensor_fault_signal,_send_0X1_to_indicate_short_circuit_or_open_circuit_fault
车内PM2.5传感器故障状态";
CM_ SG_ 1188 TMS_AQS_Sts "Send_0X1_to_indicate_a_sensor_failure
AQS传感器故障状态";
CM_ SG_ 1188 PM25overproofDisplaySts "When_the_air_purification_is_not_turned_on_and_the_INcar_PM2.5_exceeds_the_upper_limit,_the_DVD_pop-up_window_prompts_the_user_to_turn_on_the_air_purification_function
PM2.5超标提醒";
CM_ SG_ 1188 AQSDisplaySts "AQS_Display_Status
AQS状态显示";
CM_ SG_ 1188 PM25AutoRunSts "When_the_air_quality_is_poor_and_the_air_purification_automatic_operation_setting_item_is_turned_on,This_signal_indicates_the_actual_working_mode_of_air_purification
PM2.5自动运行状态";
CM_ SG_ 1188 PM25AutoRunSetSts "Air_purification_automatic_operation_status_feedback
PM2.5自动运行开关状态";
CM_ SG_ 1188 FragranceWelcomeModeSts "Welcome_mode_status_feedback
迎宾模式状态反馈";
CM_ SG_ 1188 FragranceDisplaysts "Indicates_the_display_status_of_the_fragrance_interface";
CM_ SG_ 1188 TMS_AQS_Level "AQS_Level
AQS污染等级";
CM_ SG_ 1188 ACRequestCommand "AC_Request
AC请求指示";
CM_ SG_ 1188 PM25_Outcar_Level "Six_levels_of_out-car_air_quality_assessed_according_to_out-car_PM2.5
车外PM2.5等级";
CM_ SG_ 1188 PM25_Incar_Level "Six_levels_of_in-car_air_quality_assessed_according_to_in-car_PM2.5
车内PM2.5等级";
CM_ SG_ 1188 SetTemperature_L_F "SetLTemp_Fahrenheit";
CM_ SG_ 1188 SetTemperature_R_F "SetRTemp_Fahrenheit";
CM_ SG_ 1188 TMS_PM25_incar "In-car_PM2.5_value
车内PM2.5数值";
CM_ SG_ 1188 TMS_PM25_ext "OUTcar_PM2.5_value
车外PM2.5数值";
CM_ SG_ 1188 TMS_KeepWarmMemoryFb "Keep_Warm_Memory_Status
恒温模式记忆状态";
CM_ SG_ 612 EPB_R_1_CRC1 "Profile1A:E2E CRC (SAE J1850 CRC-8) for 8 Bytes
DataID:0x002B";
CM_ SG_ 612 EPB_R_1_RollgCntr1 "Profile1A:E2E Rolling message counter(the maximum value of Alive counter is 14)";
CM_ SG_ 612 EPB_1_FltLamp "EPB故障状态
诊断和转毂测试模式时闪烁";
CM_ SG_ 612 EPB_1_ParkLamp "EPB驻车灯状态
动态制动时闪烁";
CM_ SG_ 612 EPB_1_ActrSt "Current state of APB actuator connected to ECU
EPB卡钳执行状态

备注：
①一边夹紧一边释放，按博世最新平台策略，一按照Applied外发。
②0x5:CompletelyReleased（IPB2.0实际按照Reserved）
③0x6:Half Applied（IPB2.0实际按照Reserved）";
CM_ SG_ 612 EPB_1_RWUSt "EPB 后轮防抱死工作状态：
0x1:active仪表持续提示“紧急制动开启”且仪表红“P”灯闪烁，同时点亮制动尾灯，最后1帧信号显示完后结束";
CM_ SG_ 612 EPB_1_TextDisp "EPB文本提示
备注：
0x1:驻车坡度过大，请注意安全
0x2:IPB2.0实际按照Reserved
0x3:请关好车门并系好安全带
0x4:请同时踩下制动踏板
0x5:IPB2.0新增禁止P档手动释放EPB文字提示“请切换到非P档解除电子驻车”";
CM_ SG_ 612 IPB_EPBErrorStatus "用于EPB故障显示";
CM_ SG_ 1193 AVHWarningMessage "AVH Warning Message";
CM_ SG_ 1193 CDPActive "CDP Active";
CM_ SG_ 1193 HDCFailSts "After IGN OFF, this signal should be set to 0 for avoiding ICM HDC warning.";
CM_ SG_ 1193 HDCCtrlSts "HDC Ctrl Sts";
CM_ SG_ 1193 AVHSts "Auto Hold Status";
CM_ SG_ 1193 AVHFailSts "AVH Fail Status";
CM_ SG_ 1193 FWAWarningSts "FWA:Fading warning Assist
Indicate FWA state, dashboard need warn driver";
CM_ SG_ 1197 CST_Status "CST:Comfortable stop";
CM_ SG_ 1200 EBS_SOC "Battery state of charge calculated from IBS; 101-254 reserved;Invalid Raw Value:255.";
CM_ SG_ 1061 DriverSeatMsgStr_LvlSts "0x0:关
0x1:低
0x2:中
0x3:高";
CM_ SG_ 1061 DriverSeatMsg_ModeSts "0x0:无动作
0x1:脉冲模式
0x2:波浪模式
0x3:猫步模式
0x4:单排模式
0x5:交叉模式
0x6:蝶形模式
0x7:腰部按摩模式
0x8:蛇形模式
0x9:特殊模式1
0xA:特殊模式2
0xB:特殊模式3
0xC:特殊模式4";
CM_ SG_ 1065 LeftSeatMsgStr_LvlSts "0x0:关
0x1:低
0x2:中
0x3:高";
CM_ SG_ 1065 LeftSeatMsg_ModeSts "0x0:无动作
0x1:脉冲模式
0x2:波浪模式
0x3:猫步模式
0x4:单排模式
0x5:交叉模式
0x6:蝶形模式
0x7:腰部按摩模式
0x8:蛇形模式
0x9:特殊模式1
0xA:特殊模式2
0xB:特殊模式3
0xC:特殊模式4";
CM_ SG_ 1069 PassSeatMsgStr_LvlSts "0x0:关
0x1:低
0x2:中
0x3:高";
CM_ SG_ 1069 PassSeatMsg_ModeSts "0x0:无动作
0x1:脉冲模式
0x2:波浪模式
0x3:猫步模式
0x4:单排模式
0x5:交叉模式
0x6:蝶形模式
0x7:腰部按摩模式
0x8:蛇形模式
0x9:特殊模式1
0xA:特殊模式2
0xB:特殊模式3
0xC:特殊模式4";
CM_ SG_ 1087 RightSeatMsgStr_LvlSts "0x0:关
0x1:低
0x2:中
0x3:高";
CM_ SG_ 1087 RightSeatMsg_ModeSts "0x0:无动作
0x1:脉冲模式
0x2:波浪模式
0x3:猫步模式
0x4:单排模式
0x5:交叉模式
0x6:蝶形模式
0x7:腰部按摩模式
0x8:蛇形模式
0x9:特殊模式1
0xA:特殊模式2
0xB:特殊模式3
0xC:特殊模式4";
CM_ SG_ 1189 SRF_OperateSts "天窗玻璃运行状态";
CM_ SG_ 1189 SRF_PositionSts "天窗玻璃开度值";
CM_ SG_ 1189 SRF_OverHeatProtect "天窗过热保护激活状态";
CM_ SG_ 1189 SRF_Sunshade_OperateSts "遮阳帘状运行状态";
CM_ SG_ 1189 Sunshade_OverHeatProtect "遮阳帘过热保护激活状态";
CM_ SG_ 1192 SRF_Sunroof_ActualSts "天窗的实际状态";
CM_ SG_ 1192 SRF_Sunshade_ActualSts "遮阳帘的实际状态";
CM_ SG_ 1192 SRF_Sunshade_PositionSts "遮阳帘开度值";
CM_ SG_ 1143 OBC_CC_ConnectSts "CC connect states";
CM_ SG_ 1143 CDU_MILSts "CDU请求点亮MIL灯
OBD方案增加
0x1表示点亮MIL灯";
CM_ SG_ 1295 BMS_BattFaultLampSts "高压电池故障灯显示";
CM_ SG_ 1295 BMS_OverTemp_LightSts "BMS_OverTemp_LightSts";
CM_ SG_ 1295 BMS_RemainChg_Time "BMS_RemainChg_Time";
CM_ SG_ 1295 BMS_ThermalRunawayDis "Thermal run-away";
CM_ SG_ 1295 BMS_TBOXIsolationFault "battery insulation fault state";
CM_ SG_ 1295 BMS_PreWarmDis "preheat and keepwarm indication";
CM_ SG_ 1531 BMS_HvBattSoeActDisChaCyc "actual discahrge power acumulation in one driving cycle";
CM_ SG_ 1531 BMS_HvBattSoeActReChaCyc "actual recahrge power acumulation in one driving cycle";
CM_ SG_ 1531 BMS_HvBattRatedEnergy "battery  rated energy";
CM_ SG_ 1531 BMS_HvBattRatedU "battery  rated voltage";
CM_ SG_ 1531 BMS_HvBattTypeCode "battery type";
CM_ SG_ 1531 BMS_HvBattManufcCode "battery manufacture code";
CM_ SG_ 1531 BMS_HvBattTempSensorTotalNum "battery cell temperature sensor numbers";
CM_ SG_ 1531 BMS_HvBattTempSensorTempMaxNum "highest cell temperature sensor number";
CM_ SG_ 1531 BMS_HvBattTempSensorTempMinNum "lowest cell temperature sensor number";
CM_ SG_ 1531 BMS_HvBattTempMaxNum "highest temperature module number";
CM_ SG_ 1531 BMS_HvBattTempMinNum "lowest temperature module number";
CM_ SG_ 1531 BMS_BattCellTotalNum "battery cell numbers";
CM_ SG_ 1531 BMS_HvBattVoltMaxNum "highest cell voltage module number";
CM_ SG_ 1531 BMS_HvBattVoltMinNum "lowest cell voltage module number";
CM_ SG_ 1531 BMS_ActualSOCMin "最小真实SOC";
CM_ SG_ 1531 BMS_ActualSOCMax "最大真实SOC";
CM_ SG_ 1224 BMS_HvBattCellVoltMax_Num "highest voltage cell number";
CM_ SG_ 1224 BMS_HvBattCellVoltMax "highest cell voltage";
CM_ SG_ 1224 BMS_HvBattCellVoltMin_Num "lowest voltage cell number";
CM_ SG_ 1224 BMS_HvBattCellVoltMin "lowest cell voltage";
CM_ SG_ 1224 BMS_Chg_Sts "BMS_Chg_Sts";
CM_ SG_ 1235 EPS_2_Steer_ReturnRmd_Sts "Steer  wheeel return Sts(捷途D01）";
CM_ SG_ 1235 EPS_2_Steer_ReturnRmd "Steer  wheeel return remind(捷途D01）";
CM_ SG_ 1235 EPS_2_MFS_ShakeSts "方向盘震动反馈(捷途D01）";
CM_ SG_ 1330 DWD_TextDisp "报警提示内容";
CM_ SG_ 1330 DWD_SoundIndcn "报警声音提示";
CM_ SG_ 1330 LSensorFailSts "0x0：传感器正常
0x1：传感器故障";
CM_ SG_ 1330 RSensorFailSts "0x0：传感器正常
0x1：传感器故障";
CM_ SG_ 1330 DWD_Distance "报警距离分段";
CM_ SG_ 1330 DWD_Switch "涉水雷达开关状态";
BA_DEF_ BO_  "GenMsgCycleTimeFast" INT 0 50000;
BA_DEF_ BO_  "GenMsgNrOfRepetition" INT 0 999999;
BA_DEF_ BO_  "GenMsgDelayTime" INT 0 1000;
BA_DEF_ BO_  "VFrameFormat" ENUM  "StandardCAN","ExtendedCAN","reserved","reserved","reserved","reserved","reserved","reserved","reserved","reserved","reserved","reserved","reserved","reserved","StandardCAN_FD","ExtendedCAN_FD";
BA_DEF_ BO_  "GenMsgILSupport" ENUM  "No","Yes";
BA_DEF_ BO_  "NmMessage" ENUM  "No","Yes";
BA_DEF_ BO_  "GenMsgSendType" ENUM  "Cycle","Event","IfActive","CE","CA","NoMsgSendType";
BA_DEF_ BO_  "GenMsgCycleTime" INT 0 50000;
BA_DEF_ BO_  "CANFD_BRS" INT 0 1;
BA_DEF_ BO_  "NmAsrMessage" ENUM  "No","Yes";
BA_DEF_ BO_  "GRC_ASIL" ENUM  "vector_leerstring","QM","A","B","C","D";
BA_DEF_ BO_  "GRC_History" STRING ;
BA_DEF_ SG_  "GenSigStartValue" FLOAT 0 100000000000;
BA_DEF_ SG_  "GenSigInactiveValue" INT 0 100000;
BA_DEF_ SG_  "GenSigInvalidValue" INT 0 251610920;
BA_DEF_ SG_  "GenSigSendType" ENUM  "Cycle","OnChange","OnWrite","IfActive","OnChangeWithRepetition","OnWriteWithRepetition","IfActiveWithRepetition","NoSigSendType","OnChangeAndIfActive","OnChangeAndIfActiveWithRepetition","CA","CE","Event";
BA_DEF_ SG_  "GRC_Sig_ASIL" ENUM  "vector_leerstring","QM","A","B","C","D";
BA_DEF_ SG_  "E2EDataId" INT 0 0;
BA_DEF_ SG_  "E2EProfile" STRING ;
BA_DEF_ SG_  "E2EDataLength" INT 0 512;
BA_DEF_DEF_  "GenMsgCycleTimeFast" 0;
BA_DEF_DEF_  "GenMsgNrOfRepetition" 0;
BA_DEF_DEF_  "GenMsgDelayTime" 0;
BA_DEF_DEF_  "VFrameFormat" "StandardCAN";
BA_DEF_DEF_  "GenMsgILSupport" "No";
BA_DEF_DEF_  "NmMessage" "No";
BA_DEF_DEF_  "GenMsgSendType" "NoMsgSendType";
BA_DEF_DEF_  "GenMsgCycleTime" 0;
BA_DEF_DEF_  "CANFD_BRS" 0;
BA_DEF_DEF_  "NmAsrMessage" "No";
BA_DEF_DEF_  "GRC_ASIL" "";
BA_DEF_DEF_  "GRC_History" "";
BA_DEF_DEF_  "GenSigStartValue" 0;
BA_DEF_DEF_  "GenSigInactiveValue" 0;
BA_DEF_DEF_  "GenSigInvalidValue" 0;
BA_DEF_DEF_  "GenSigSendType" "NoSigSendType";
BA_DEF_DEF_  "GRC_Sig_ASIL" "";
BA_DEF_DEF_  "E2EDataId" 0;
BA_DEF_DEF_  "E2EProfile" "";
BA_DEF_DEF_  "E2EDataLength" 0;
BA_ "CANFD_BRS" BO_ 1072 1;
BA_ "GenMsgSendType" BO_ 1072 0;
BA_ "GenMsgCycleTime" BO_ 1072 100;
BA_ "GenMsgILSupport" BO_ 1072 1;
BA_ "GRC_History" BO_ 1072 "[{'approvedBy':'贾少辉','author':'吴慧','changesComments':'同步股份，补充所有未填写的初始值,补充为0x0','date':'2024/12/13','ecu':'FLZCU_31(0x430)','ecuName':'FLZCU,ICC,DVR','reviewedBy':'杨华','revision':'V2.1'},{'approvedBy':'贾少辉','author':'吴慧','ch";
BA_ "VFrameFormat" BO_ 1072 14;
BA_ "CANFD_BRS" BO_ 1209 1;
BA_ "GenMsgSendType" BO_ 1209 0;
BA_ "GenMsgCycleTime" BO_ 1209 100;
BA_ "GenMsgILSupport" BO_ 1209 1;
BA_ "GRC_History" BO_ 1209 "[{'approvedBy':'贾少辉','author':'吴慧','changesComments':'信号名更改为VCU_2_G_GasPedalPosInvalidData同步汪苇更新','date':'2024/11/28','ecu':'VCU_2_G(0x4B9)','ecuName':'ICC,DVR','reviewedBy':'杨华','revision':'V2.0'},{'approvedBy':'贾少辉','author':'吴慧";
BA_ "VFrameFormat" BO_ 1209 14;
BA_ "CANFD_BRS" BO_ 1229 1;
BA_ "GenMsgSendType" BO_ 1229 0;
BA_ "GenMsgCycleTime" BO_ 1229 100;
BA_ "GenMsgILSupport" BO_ 1229 1;
BA_ "GRC_History" BO_ 1229 "[{'approvedBy':'贾少辉','author':'吴慧','changesComments':'同步CH网段，补充所有未填写的初始值,补充为0x0','date':'2024/12/13','ecu':'VCU_4_G(0x4CD)','ecuName':'HCU,FLZCU,ICC','reviewedBy':'杨华','revision':'V2.1'}]";
BA_ "VFrameFormat" BO_ 1229 14;
BA_ "CANFD_BRS" BO_ 1263 1;
BA_ "GenMsgSendType" BO_ 1263 0;
BA_ "GenMsgCycleTime" BO_ 1263 100;
BA_ "GenMsgILSupport" BO_ 1263 1;
BA_ "GRC_History" BO_ 1263 "[{'approvedBy':'贾少辉','author':'吴慧','changesComments':'同步股份，补充所有未填写的初始值,补充为0x0和0x3E8，股份信号','date':'2024/12/14','ecu':'VCU_5_G(0x4EF)','ecuName':'ICC','reviewedBy':'杨华','revision':'V2.1'}]";
BA_ "VFrameFormat" BO_ 1263 14;
BA_ "CANFD_BRS" BO_ 1034 1;
BA_ "GenMsgSendType" BO_ 1034 0;
BA_ "GenMsgCycleTime" BO_ 1034 100;
BA_ "GenMsgILSupport" BO_ 1034 1;
BA_ "GRC_History" BO_ 1034 "[{'approvedBy':'贾少辉','author':'吴慧','changesComments':'同步PT网段，补充所有未填写的初始值,补充为0x0和0x80','date':'2024/12/14','ecu':'HCU_1_G(0x40A)','ecuName':'ICC,HCU,FLZCU','reviewedBy':'杨华','revision':'V2.1'},{'approvedBy':'贾少辉','author':'吴";
BA_ "VFrameFormat" BO_ 1034 14;
BA_ "CANFD_BRS" BO_ 1044 1;
BA_ "GenMsgSendType" BO_ 1044 0;
BA_ "GenMsgCycleTime" BO_ 1044 100;
BA_ "GenMsgILSupport" BO_ 1044 1;
BA_ "GRC_History" BO_ 1044 "[{'approvedBy':'贾少辉','author':'吴慧','changesComments':'同步GL网段，补充所有未填写的初始值,补充为0x0','date':'2024/12/13','ecu':'HCU_2_G(0x414)','ecuName':'HCU,FLZCU,ICC','reviewedBy':'杨华','revision':'V2.1'}]";
BA_ "VFrameFormat" BO_ 1044 14;
BA_ "CANFD_BRS" BO_ 1204 1;
BA_ "GenMsgSendType" BO_ 1204 0;
BA_ "GenMsgCycleTime" BO_ 1204 100;
BA_ "GenMsgILSupport" BO_ 1204 1;
BA_ "GRC_History" BO_ 1204 "[{'approvedBy':'贾少辉','author':'吴慧','changesComments':'李思思BBCM新增接收E2E信号CRC计数信号','date':'2024/11/27','ecu':'VCU_1_G(0x4B4)','ecuName':'BBCM,FLZCU,HCU','reviewedBy':'杨华','revision':'V2.0'},{'approvedBy':'贾少辉','author':'吴慧','changesC";
BA_ "VFrameFormat" BO_ 1204 14;
BA_ "CANFD_BRS" BO_ 1057 1;
BA_ "GenMsgSendType" BO_ 1057 0;
BA_ "GenMsgCycleTime" BO_ 1057 100;
BA_ "GenMsgILSupport" BO_ 1057 1;
BA_ "GRC_History" BO_ 1057 "[{'approvedBy':'贾少辉','author':'吴慧','changesComments':'同步PT网段，补充所有未填写的初始值,补充为0x0','date':'2024/12/14','ecu':'VCU_7_G(0x421)','ecuName':'ICC,HCU,FLZCU','reviewedBy':'杨华','revision':'V2.1'}]";
BA_ "VFrameFormat" BO_ 1057 14;
BA_ "CANFD_BRS" BO_ 1043 1;
BA_ "GenMsgSendType" BO_ 1043 0;
BA_ "GenMsgCycleTime" BO_ 1043 100;
BA_ "GenMsgILSupport" BO_ 1043 1;
BA_ "GRC_History" BO_ 1043 "[{'approvedBy':'贾少辉','author':'吴慧','changesComments':'1、EBS_I_RANGE增加无效值0x3;\n2、EBS_U_BATT增加无效值0x3FFF;\n3、EBS_I_BATT最大值变更为65535总线值改为0xFFFF，增加无效值0xFFFF;\n4、EBS_T_BATT增加无效值为0xFF;\n5、EBS_IBATT_QUIESCENT最大值改为0.";
BA_ "VFrameFormat" BO_ 1043 14;
BA_ "CANFD_BRS" BO_ 1022 1;
BA_ "GenMsgSendType" BO_ 1022 0;
BA_ "GenMsgCycleTime" BO_ 1022 100;
BA_ "GenMsgILSupport" BO_ 1022 1;
BA_ "GRC_History" BO_ 1022 "[{'approvedBy':'贾少辉','author':'吴慧','changesComments':'李思思BBCM反馈小憩模式功能规范,BBCM不接受小憩模式相关这6个信号','date':'2024/11/20','ecu':'FLZCU_40(0x3FE)','ecuName':'FLZCU,BBCM','reviewedBy':'杨华','revision':'V1.3.1'},{'approvedBy':'贾少辉',";
BA_ "VFrameFormat" BO_ 1022 14;
BA_ "CANFD_BRS" BO_ 1020 1;
BA_ "GenMsgSendType" BO_ 1020 0;
BA_ "GenMsgCycleTime" BO_ 1020 100;
BA_ "GenMsgILSupport" BO_ 1020 1;
BA_ "GRC_History" BO_ 1020 "[{'approvedBy':'贾少辉','author':'吴慧','changesComments':'删除拆帧路由，ICC不接收RMCU_1_OutputTorque，由报文0x1E5处理为0x3FC刘标朱钊','date':'2024/10/31','ecu':'FLZCU_41(0x3FC)','ecuName':'ICC','reviewedBy':'杨华','revision':'V1.3.1'},{'approvedBy':'贾�";
BA_ "VFrameFormat" BO_ 1020 14;
BA_ "CANFD_BRS" BO_ 1142 1;
BA_ "GenMsgSendType" BO_ 1142 0;
BA_ "GenMsgCycleTime" BO_ 1142 100;
BA_ "GenMsgILSupport" BO_ 1142 1;
BA_ "GRC_History" BO_ 1142 "[{'approvedBy':'贾少辉','author':'吴慧','changesComments':'黄诚刚HCU百公里油耗/能耗单位统一由L/km改为L/100km','date':'2024/11/18','ecu':'HCU_4_G(0x476)','ecuName':'FLZCU,HCU,ICC','reviewedBy':'杨华','revision':'V1.3.1'},{'approvedBy':'贾少辉','author':'�";
BA_ "VFrameFormat" BO_ 1142 14;
BA_ "CANFD_BRS" BO_ 1314 1;
BA_ "GenMsgSendType" BO_ 1314 0;
BA_ "GenMsgCycleTime" BO_ 1314 100;
BA_ "GenMsgILSupport" BO_ 1314 1;
BA_ "GRC_History" BO_ 1314 "[{'approvedBy':'贾少辉','author':'吴慧','changesComments':'ICC新增接收HCU_25_VehSpdOffroadRmn魏睿','date':'2024/11/4','ecu':'HCU_25(0x522)','ecuName':'HCU,ICC','reviewedBy':'杨华','revision':'V1.3.1'},{'approvedBy':'贾少辉','author':'吴慧','changesCommen";
BA_ "VFrameFormat" BO_ 1314 14;
BA_ "CANFD_BRS" BO_ 1075 1;
BA_ "GenMsgSendType" BO_ 1075 1;
BA_ "GenMsgCycleTimeFast" BO_ 1075 100;
BA_ "GenMsgNrOfRepetition" BO_ 1075 3;
BA_ "GenMsgDelayTime" BO_ 1075 5;
BA_ "GenMsgILSupport" BO_ 1075 1;
BA_ "GRC_History" BO_ 1075 "[{'approvedBy':'贾少辉','author':'吴慧','changesComments':'同步CH网段，补充所有未填写的初始值,补充为0x0','date':'2024/12/12','ecu':'VCC_2(0x433)','ecuName':'ICC,BBCM,FLZCU','reviewedBy':'杨华','revision':'V2.1'}]";
BA_ "VFrameFormat" BO_ 1075 14;
BA_ "CANFD_BRS" BO_ 1136 1;
BA_ "GenMsgSendType" BO_ 1136 1;
BA_ "GenMsgCycleTimeFast" BO_ 1136 100;
BA_ "GenMsgNrOfRepetition" BO_ 1136 95;
BA_ "GenMsgDelayTime" BO_ 1136 5;
BA_ "GenMsgILSupport" BO_ 1136 1;
BA_ "GRC_History" BO_ 1136 "[{'approvedBy':'贾少辉','author':'吴慧','changesComments':'参考GL网段更新：修改VCC_3_SN最小值最大值初始值等','date':'2024/12/11','ecu':'VCC_3(0x470)','ecuName':'ICC,BBCM,FLZCU','reviewedBy':'杨华','revision':'V2.1'},{'approvedBy':'贾少辉','author':'吴慧'";
BA_ "VFrameFormat" BO_ 1136 14;
BA_ "CANFD_BRS" BO_ 1196 1;
BA_ "GenMsgSendType" BO_ 1196 0;
BA_ "GenMsgCycleTime" BO_ 1196 100;
BA_ "GenMsgILSupport" BO_ 1196 1;
BA_ "VFrameFormat" BO_ 1196 14;
BA_ "CANFD_BRS" BO_ 1177 1;
BA_ "GenMsgSendType" BO_ 1177 0;
BA_ "GenMsgCycleTime" BO_ 1177 100;
BA_ "GenMsgILSupport" BO_ 1177 1;
BA_ "VFrameFormat" BO_ 1177 14;
BA_ "CANFD_BRS" BO_ 1109 1;
BA_ "GenMsgSendType" BO_ 1109 0;
BA_ "GenMsgCycleTime" BO_ 1109 100;
BA_ "GenMsgILSupport" BO_ 1109 1;
BA_ "VFrameFormat" BO_ 1109 14;
BA_ "CANFD_BRS" BO_ 1231 1;
BA_ "GenMsgSendType" BO_ 1231 3;
BA_ "GenMsgCycleTime" BO_ 1231 100;
BA_ "GenMsgCycleTimeFast" BO_ 1231 100;
BA_ "GenMsgNrOfRepetition" BO_ 1231 3;
BA_ "GenMsgDelayTime" BO_ 1231 5;
BA_ "GenMsgILSupport" BO_ 1231 1;
BA_ "VFrameFormat" BO_ 1231 14;
BA_ "CANFD_BRS" BO_ 1288 1;
BA_ "GenMsgSendType" BO_ 1288 0;
BA_ "GenMsgCycleTime" BO_ 1288 500;
BA_ "GenMsgILSupport" BO_ 1288 1;
BA_ "VFrameFormat" BO_ 1288 14;
BA_ "CANFD_BRS" BO_ 1063 1;
BA_ "GenMsgSendType" BO_ 1063 1;
BA_ "GenMsgCycleTimeFast" BO_ 1063 100;
BA_ "GenMsgNrOfRepetition" BO_ 1063 3;
BA_ "GenMsgDelayTime" BO_ 1063 5;
BA_ "GenMsgILSupport" BO_ 1063 1;
BA_ "VFrameFormat" BO_ 1063 14;
BA_ "CANFD_BRS" BO_ 1148 1;
BA_ "GenMsgSendType" BO_ 1148 0;
BA_ "GenMsgCycleTime" BO_ 1148 100;
BA_ "GenMsgILSupport" BO_ 1148 1;
BA_ "GRC_History" BO_ 1148 "[{'approvedBy':'贾少辉','author':'吴慧','changesComments':'章攀TBOX新增发送：GPS定位开启和关闭设置TBOX_GPSSwitchSts信号，ICC接收','date':'2025/3/24','ecu':'TBOX_7(0x47C)','ecuName':'ICC','reviewedBy':'杨华','revision':'V2.3'}]";
BA_ "VFrameFormat" BO_ 1148 14;
BA_ "CANFD_BRS" BO_ 1162 1;
BA_ "GenMsgSendType" BO_ 1162 0;
BA_ "GenMsgCycleTime" BO_ 1162 100;
BA_ "GenMsgILSupport" BO_ 1162 1;
BA_ "GRC_ASIL" BO_ 1162 3;
BA_ "GRC_History" BO_ 1162 "[{'approvedBy':'贾少辉','author':'吴慧','changesComments':'李思思BBCM新增接收E2E信号CRC计数信号','date':'2024/11/1','ecu':'ONEBOX_1_G(0x48A)','ecuName':'BBCM','reviewedBy':'杨华','revision':'V1.3.1'},{'approvedBy':'贾少辉','author':'吴慧','changesComment";
BA_ "VFrameFormat" BO_ 1162 14;
BA_ "CANFD_BRS" BO_ 1202 1;
BA_ "GenMsgSendType" BO_ 1202 0;
BA_ "GenMsgCycleTime" BO_ 1202 100;
BA_ "GenMsgILSupport" BO_ 1202 1;
BA_ "VFrameFormat" BO_ 1202 14;
BA_ "CANFD_BRS" BO_ 683 1;
BA_ "GenMsgSendType" BO_ 683 0;
BA_ "GenMsgCycleTime" BO_ 683 20;
BA_ "GenMsgILSupport" BO_ 683 1;
BA_ "GRC_ASIL" BO_ 683 2;
BA_ "GRC_History" BO_ 683 "[{'approvedBy':'贾少辉','author':'吴慧','changesComments':'同步GL网段新增RKE_ButtAct信号，无接收端','date':'2024/12/30','ecu':'FRZCU_1(0x2AB)','ecuName':'CGW','reviewedBy':'杨华','revision':'V2.1'},{'approvedBy':'贾少辉','author':'吴慧','changesComments'";
BA_ "VFrameFormat" BO_ 683 14;
BA_ "CANFD_BRS" BO_ 33 1;
BA_ "GenMsgSendType" BO_ 33 0;
BA_ "GenMsgCycleTime" BO_ 33 10;
BA_ "GenMsgILSupport" BO_ 33 1;
BA_ "GRC_History" BO_ 33 "[{'approvedBy':'贾少辉','author':'吴慧','changesComments':'ACU_3_LongitudinalAcceleration、ACU_3_LongitudinalAccelerationVD根据ACU工程师确认，更新初始值、无效值(汪苇)','date':'2024/10/23','ecu':'ACU_3(0x021)','ecuName':'CGW,ICC','reviewedBy':'杨华','revi";
BA_ "VFrameFormat" BO_ 33 14;
BA_ "CANFD_BRS" BO_ 632 1;
BA_ "GenMsgSendType" BO_ 632 0;
BA_ "GenMsgCycleTime" BO_ 632 50;
BA_ "GenMsgILSupport" BO_ 632 1;
BA_ "GRC_History" BO_ 632 "[{'approvedBy':'贾少辉','author':'吴慧','changesComments':'EMS修改EMS_4_EngineSts信号备注，无接收端','date':'2024/11/28','ecu':'EMS_4（0x278）','ecuName':'CGW','reviewedBy':'杨华','revision':'V2.0'}]";
BA_ "VFrameFormat" BO_ 632 14;
BA_ "CANFD_BRS" BO_ 1217 1;
BA_ "GenMsgSendType" BO_ 1217 0;
BA_ "GenMsgCycleTime" BO_ 1217 100;
BA_ "GenMsgILSupport" BO_ 1217 1;
BA_ "GRC_History" BO_ 1217 "[{'approvedBy':'贾少辉','author':'吴慧','changesComments':'同步SU网段，补充所有未填写的初始值,补充为0x0','date':'2024/12/13','ecu':'ASU_1(0x4C1)','ecuName':'ICC','reviewedBy':'杨华','revision':'V2.1'},{'approvedBy':'贾少辉','author':'吴慧','changesCommen";
BA_ "VFrameFormat" BO_ 1217 14;
BA_ "CANFD_BRS" BO_ 258 1;
BA_ "GenMsgSendType" BO_ 258 0;
BA_ "GenMsgCycleTime" BO_ 258 10;
BA_ "GenMsgILSupport" BO_ 258 1;
BA_ "GRC_History" BO_ 258 "[{'approvedBy':'贾少辉','author':'吴慧','changesComments':'同步EP网段，补充所有未填写的初始值,补充为0x0','date':'2024/12/14','ecu':'BMS_1(0x102)','ecuName':'ICC','reviewedBy':'杨华','revision':'V2.1'},{'approvedBy':'贾少辉','author':'吴慧','changesCommen";
BA_ "VFrameFormat" BO_ 258 14;
BA_ "CANFD_BRS" BO_ 1290 1;
BA_ "GenMsgSendType" BO_ 1290 0;
BA_ "GenMsgCycleTime" BO_ 1290 500;
BA_ "GenMsgILSupport" BO_ 1290 1;
BA_ "GRC_History" BO_ 1290 "[{'approvedBy':'贾少辉','author':'吴慧','changesComments':'同步EP网段，补充所有未填写的初始值,补充为0x0','date':'2024/12/14','ecu':'BMS_8(0x50A)','ecuName':'ICC','reviewedBy':'杨华','revision':'V2.1'},{'approvedBy':'贾少辉','author':'吴慧','changesCommen";
BA_ "VFrameFormat" BO_ 1290 14;
BA_ "CANFD_BRS" BO_ 1163 1;
BA_ "GenMsgSendType" BO_ 1163 0;
BA_ "GenMsgCycleTime" BO_ 1163 100;
BA_ "GenMsgILSupport" BO_ 1163 1;
BA_ "GRC_History" BO_ 1163 "[{'approvedBy':'贾少辉','author':'吴慧','changesComments':'同步PT网段，补充所有未填写的初始值,补充为0x0和0x7FFF','date':'2024/12/14','ecu':'FMCU_6(0x48B)','ecuName':'ICC','reviewedBy':'杨华','revision':'V2.1'}]";
BA_ "VFrameFormat" BO_ 1163 14;
BA_ "CANFD_BRS" BO_ 1316 1;
BA_ "GenMsgSendType" BO_ 1316 0;
BA_ "GenMsgCycleTime" BO_ 1316 500;
BA_ "GenMsgILSupport" BO_ 1316 1;
BA_ "VFrameFormat" BO_ 1316 14;
BA_ "CANFD_BRS" BO_ 1324 1;
BA_ "GenMsgSendType" BO_ 1324 0;
BA_ "GenMsgCycleTime" BO_ 1324 500;
BA_ "GenMsgILSupport" BO_ 1324 1;
BA_ "GRC_ASIL" BO_ 1324 3;
BA_ "GRC_History" BO_ 1324 "[{'approvedBy':'贾少辉','author':'吴慧','changesComments':'同步GL网段更新：信号值描述0x3：Reserved改成0x3:Low Batter涉及信号\nTirePositionWarning_LHFTire、TirePositionWarning_RHFTire、TirePositionWarning_LHRTire、TirePositionWarning_RHRTire','date':'2024";
BA_ "VFrameFormat" BO_ 1324 14;
BA_ "CANFD_BRS" BO_ 991 1;
BA_ "GenMsgSendType" BO_ 991 0;
BA_ "GenMsgCycleTime" BO_ 991 50;
BA_ "GenMsgILSupport" BO_ 991 1;
BA_ "VFrameFormat" BO_ 991 14;
BA_ "CANFD_BRS" BO_ 1188 1;
BA_ "GenMsgSendType" BO_ 1188 0;
BA_ "GenMsgCycleTime" BO_ 1188 100;
BA_ "GenMsgILSupport" BO_ 1188 1;
BA_ "VFrameFormat" BO_ 1188 14;
BA_ "CANFD_BRS" BO_ 612 1;
BA_ "GenMsgSendType" BO_ 612 0;
BA_ "GenMsgCycleTime" BO_ 612 20;
BA_ "GenMsgILSupport" BO_ 612 1;
BA_ "GRC_History" BO_ 612 "[{'approvedBy':'贾少辉','author':'吴慧','changesComments':'新增一列信息：E2E SignalGroup功能安全信号组','date':'2025/1/13','ecu':'EPB_R_1(0x264)','ecuName':'ICC,DVR','reviewedBy':'杨华','revision':'V2.1.1'}]";
BA_ "VFrameFormat" BO_ 612 14;
BA_ "CANFD_BRS" BO_ 1193 1;
BA_ "GenMsgSendType" BO_ 1193 0;
BA_ "GenMsgCycleTime" BO_ 1193 100;
BA_ "GenMsgILSupport" BO_ 1193 1;
BA_ "GRC_ASIL" BO_ 1193 3;
BA_ "GRC_History" BO_ 1193 "[{'approvedBy':'贾少辉','author':'吴慧','changesComments':'ICC新增接收FWAWarningSts魏睿','date':'2024/11/4','ecu':'ONEBOX_2_G(0x4A9)','ecuName':'ICC','reviewedBy':'杨华','revision':'V1.3.1'},{'approvedBy':'贾少辉','author':'吴慧','changesComments':'新增�";
BA_ "VFrameFormat" BO_ 1193 14;
BA_ "CANFD_BRS" BO_ 1197 1;
BA_ "GenMsgSendType" BO_ 1197 0;
BA_ "GenMsgCycleTime" BO_ 1197 100;
BA_ "GenMsgILSupport" BO_ 1197 1;
BA_ "GRC_History" BO_ 1197 "[{'approvedBy':'贾少辉','author':'吴慧','changesComments':'ICC新增接收BrakepedalFeelSts，信号状态启用：0x2:Offroad','date':'2024/11/28','ecu':'ONEBOX_3_G(0x4AD)','ecuName':'ICC','reviewedBy':'杨华','revision':'V2.0'}]";
BA_ "VFrameFormat" BO_ 1197 14;
BA_ "CANFD_BRS" BO_ 1200 1;
BA_ "GenMsgSendType" BO_ 1200 0;
BA_ "GenMsgCycleTime" BO_ 1200 100;
BA_ "GenMsgILSupport" BO_ 1200 1;
BA_ "GRC_History" BO_ 1200 "[{'approvedBy':'贾少辉','author':'吴慧','changesComments':'LIN转CAN报文路由：发送端删除FLZCU，改为CGW','date':'2024/12/17','ecu':'FLZCU_6(0x4B0)','ecuName':'ICC,FLZCU,CGW','reviewedBy':'杨华','revision':'V2.1'},{'approvedBy':'贾少辉','author':'吴慧','cha";
BA_ "VFrameFormat" BO_ 1200 14;
BA_ "CANFD_BRS" BO_ 1061 1;
BA_ "GenMsgSendType" BO_ 1061 0;
BA_ "GenMsgCycleTime" BO_ 1061 100;
BA_ "GenMsgILSupport" BO_ 1061 1;
BA_ "GRC_History" BO_ 1061 "[{'approvedBy':'贾少辉','author':'吴慧','changesComments':'LIN转CAN报文路由：发送端删除FLZCU，改为CGW','date':'2024/12/17','ecu':'FLZCU_18(0x425)','ecuName':'ICC,FLZCU,CGW','reviewedBy':'杨华','revision':'V2.1'}]";
BA_ "VFrameFormat" BO_ 1061 14;
BA_ "CANFD_BRS" BO_ 1065 1;
BA_ "GenMsgSendType" BO_ 1065 0;
BA_ "GenMsgCycleTime" BO_ 1065 100;
BA_ "GenMsgILSupport" BO_ 1065 1;
BA_ "GRC_History" BO_ 1065 "[{'approvedBy':'贾少辉','author':'吴慧','changesComments':'LIN转CAN报文路由：发送端删除FLZCU，改为CGW','date':'2024/12/17','ecu':'FLZCU_19(0x429)','ecuName':'ICC,FLZCU,CGW','reviewedBy':'杨华','revision':'V2.1'}]";
BA_ "VFrameFormat" BO_ 1065 14;
BA_ "CANFD_BRS" BO_ 1069 1;
BA_ "GenMsgSendType" BO_ 1069 0;
BA_ "GenMsgCycleTime" BO_ 1069 100;
BA_ "GenMsgILSupport" BO_ 1069 1;
BA_ "GRC_History" BO_ 1069 "[{'approvedBy':'贾少辉','author':'吴慧','changesComments':'LIN转CAN报文路由：发送端删除FLZCU，改为CGW','date':'2024/12/17','ecu':'FLZCU_20(0x42D)','ecuName':'ICC,FLZCU,CGW','reviewedBy':'杨华','revision':'V2.1'}]";
BA_ "VFrameFormat" BO_ 1069 14;
BA_ "CANFD_BRS" BO_ 1087 1;
BA_ "GenMsgSendType" BO_ 1087 0;
BA_ "GenMsgCycleTime" BO_ 1087 100;
BA_ "GenMsgILSupport" BO_ 1087 1;
BA_ "GRC_History" BO_ 1087 "[{'approvedBy':'贾少辉','author':'吴慧','changesComments':'LIN转CAN报文路由：发送端删除FLZCU，改为CGW','date':'2024/12/17','ecu':'FLZCU_21(0x43F)','ecuName':'ICC,FLZCU,CGW','reviewedBy':'杨华','revision':'V2.1'}]";
BA_ "VFrameFormat" BO_ 1087 14;
BA_ "CANFD_BRS" BO_ 1189 1;
BA_ "GenMsgSendType" BO_ 1189 0;
BA_ "GenMsgCycleTime" BO_ 1189 100;
BA_ "GenMsgILSupport" BO_ 1189 1;
BA_ "GRC_History" BO_ 1189 "[{'approvedBy':'贾少辉','author':'吴慧','changesComments':'LIN转CAN报文路由：发送端删除FLZCU，改为CGW','date':'2024/12/17','ecu':'FLZCU_37(0x4A5)','ecuName':'ICC,FLZCU,CGW','reviewedBy':'杨华','revision':'V2.1'},{'approvedBy':'贾少辉','author':'吴慧','ch";
BA_ "VFrameFormat" BO_ 1189 14;
BA_ "CANFD_BRS" BO_ 1192 1;
BA_ "GenMsgSendType" BO_ 1192 0;
BA_ "GenMsgCycleTime" BO_ 1192 100;
BA_ "GenMsgILSupport" BO_ 1192 1;
BA_ "GRC_History" BO_ 1192 "[{'approvedBy':'贾少辉','author':'吴慧','changesComments':'LIN转CAN报文路由：发送端删除FLZCU，改为CGW','date':'2024/12/17','ecu':'FLZCU_38(0x4A8)','ecuName':'ICC,FLZCU,CGW','reviewedBy':'杨华','revision':'V2.1'}]";
BA_ "VFrameFormat" BO_ 1192 14;
BA_ "CANFD_BRS" BO_ 1143 1;
BA_ "GenMsgSendType" BO_ 1143 0;
BA_ "GenMsgCycleTime" BO_ 1143 100;
BA_ "GenMsgILSupport" BO_ 1143 1;
BA_ "GRC_History" BO_ 1143 "[{'approvedBy':'贾少辉','author':'吴慧','changesComments':'同步EP网段，补充所有未填写的初始值,补充为0x0和0x28','date':'2024/12/13','ecu':'CDU_2(0x477)','ecuName':'ICC','reviewedBy':'杨华','revision':'V2.1'},{'approvedBy':'贾少辉','author':'吴慧','changes";
BA_ "VFrameFormat" BO_ 1143 14;
BA_ "CANFD_BRS" BO_ 1295 1;
BA_ "GenMsgSendType" BO_ 1295 0;
BA_ "GenMsgCycleTime" BO_ 1295 500;
BA_ "GenMsgILSupport" BO_ 1295 1;
BA_ "GRC_History" BO_ 1295 "[{'approvedBy':'贾少辉','author':'吴慧','changesComments':'同步EP网段，补充所有未填写的初始值,补充为0x0','date':'2024/12/14','ecu':'BMS_3_G(0x50F)','ecuName':'ICC','reviewedBy':'杨华','revision':'V2.1'},{'approvedBy':'贾少辉','author':'吴慧','changesComm";
BA_ "VFrameFormat" BO_ 1295 14;
BA_ "CANFD_BRS" BO_ 1531 1;
BA_ "GenMsgSendType" BO_ 1531 0;
BA_ "GenMsgCycleTime" BO_ 1531 1000;
BA_ "GenMsgILSupport" BO_ 1531 1;
BA_ "GRC_History" BO_ 1531 "[{'approvedBy':'贾少辉','author':'吴慧','changesComments':'同步EP网段，补充所有未填写的初始值,补充为0x0','date':'2024/12/14','ecu':'BMS_9(0x5FB)','ecuName':'ICC','reviewedBy':'杨华','revision':'V2.1'}]";
BA_ "VFrameFormat" BO_ 1531 14;
BA_ "CANFD_BRS" BO_ 1224 1;
BA_ "GenMsgSendType" BO_ 1224 0;
BA_ "GenMsgCycleTime" BO_ 1224 100;
BA_ "GenMsgILSupport" BO_ 1224 1;
BA_ "GRC_History" BO_ 1224 "[{'approvedBy':'贾少辉','author':'吴慧','changesComments':'同步EP网段，补充BMS_Chg_Sts初始值为0x0','date':'2024/12/14','ecu':'BMS_12(0x4C8)','ecuName':'ICC','reviewedBy':'杨华','revision':'V2.1'}]";
BA_ "VFrameFormat" BO_ 1224 14;
BA_ "CANFD_BRS" BO_ 1235 1;
BA_ "GenMsgSendType" BO_ 1235 0;
BA_ "GenMsgCycleTime" BO_ 1235 100;
BA_ "GenMsgILSupport" BO_ 1235 1;
BA_ "GRC_History" BO_ 1235 "[{'approvedBy':'贾少辉','author':'吴慧','changesComments':'同步CH网段，补充所有未填写的初始值,补充为0x0','date':'2024/12/13','ecu':'EPS_2(0x4D3)','ecuName':'CGW','reviewedBy':'杨华','revision':'V2.1'}]";
BA_ "VFrameFormat" BO_ 1235 14;
BA_ "CANFD_BRS" BO_ 1330 1;
BA_ "GenMsgSendType" BO_ 1330 0;
BA_ "GenMsgCycleTime" BO_ 1330 100;
BA_ "GenMsgILSupport" BO_ 1330 1;
BA_ "VFrameFormat" BO_ 1330 14;
BA_ "GRC_Sig_ASIL" SG_ 1072 LHTurnlightSts 3;
BA_ "GenSigSendType" SG_ 1072 LHTurnlightSts 0;
BA_ "GRC_Sig_ASIL" SG_ 1072 RHTurnlightSts 3;
BA_ "GenSigSendType" SG_ 1072 RHTurnlightSts 0;
BA_ "GRC_Sig_ASIL" SG_ 1072 LHFdoorSts 2;
BA_ "GenSigSendType" SG_ 1072 LHFdoorSts 0;
BA_ "GRC_Sig_ASIL" SG_ 1072 LHFSeatBeltSW 2;
BA_ "GenSigSendType" SG_ 1072 LHFSeatBeltSW 0;
BA_ "GRC_Sig_ASIL" SG_ 1072 TrunkSts 2;
BA_ "GenSigSendType" SG_ 1072 TrunkSts 0;
BA_ "GenSigSendType" SG_ 1072 RLWinPosn 0;
BA_ "GenSigInvalidValue" SG_ 1072 RLWinPosn 127;
BA_ "GenSigStartValue" SG_ 1072 RLWinPosn 127;
BA_ "GenSigSendType" SG_ 1072 SeatHeatLevelsFL 0;
BA_ "GenSigSendType" SG_ 1072 SeatHeatLevelsRL 0;
BA_ "GenSigSendType" SG_ 1072 SeatVentLevelsFL 0;
BA_ "GenSigSendType" SG_ 1072 SeatVentLevelsRL 0;
BA_ "GenSigSendType" SG_ 1072 FLWinPosn 0;
BA_ "GenSigInvalidValue" SG_ 1072 FLWinPosn 127;
BA_ "GenSigStartValue" SG_ 1072 FLWinPosn 127;
BA_ "GenSigSendType" SG_ 1072 FLZCU_FrontWiperMaintenanceSts 0;
BA_ "GenSigSendType" SG_ 1072 FLZCU_RearWiperMaintenanceSts 0;
BA_ "GenSigSendType" SG_ 1209 VCU_2_G_CRC 0;
BA_ "E2EDataId" SG_ 1209 VCU_2_G_CRC 93;
BA_ "E2EProfile" SG_ 1209 VCU_2_G_CRC "P01";
BA_ "E2EDataLength" SG_ 1209 VCU_2_G_CRC 64;
BA_ "GenSigSendType" SG_ 1209 VCU_2_G_RollgCntr 0;
BA_ "E2EDataId" SG_ 1209 VCU_2_G_RollgCntr 93;
BA_ "E2EProfile" SG_ 1209 VCU_2_G_RollgCntr "P01";
BA_ "E2EDataLength" SG_ 1209 VCU_2_G_RollgCntr 64;
BA_ "GenSigSendType" SG_ 1209 VCU_2_G_Resd 0;
BA_ "E2EDataId" SG_ 1209 VCU_2_G_Resd 93;
BA_ "E2EProfile" SG_ 1209 VCU_2_G_Resd "P01";
BA_ "E2EDataLength" SG_ 1209 VCU_2_G_Resd 64;
BA_ "GRC_Sig_ASIL" SG_ 1209 VCU_2_G_GasPedalPosInvalidData 3;
BA_ "GenSigSendType" SG_ 1209 VCU_2_G_GasPedalPosInvalidData 0;
BA_ "E2EDataId" SG_ 1209 VCU_2_G_GasPedalPosInvalidData 93;
BA_ "E2EProfile" SG_ 1209 VCU_2_G_GasPedalPosInvalidData "P01";
BA_ "E2EDataLength" SG_ 1209 VCU_2_G_GasPedalPosInvalidData 64;
BA_ "GRC_Sig_ASIL" SG_ 1209 VCU_2_G_PowerLimit 3;
BA_ "GenSigSendType" SG_ 1209 VCU_2_G_PowerLimit 0;
BA_ "E2EDataId" SG_ 1209 VCU_2_G_PowerLimit 93;
BA_ "E2EProfile" SG_ 1209 VCU_2_G_PowerLimit "P01";
BA_ "E2EDataLength" SG_ 1209 VCU_2_G_PowerLimit 64;
BA_ "GenSigSendType" SG_ 1209 VCU_2_G_BrakeLightReq 0;
BA_ "E2EDataId" SG_ 1209 VCU_2_G_BrakeLightReq 93;
BA_ "E2EProfile" SG_ 1209 VCU_2_G_BrakeLightReq "P01";
BA_ "E2EDataLength" SG_ 1209 VCU_2_G_BrakeLightReq 64;
BA_ "GRC_Sig_ASIL" SG_ 1209 VCU_2_G_VehicleSystemFailure 3;
BA_ "GenSigSendType" SG_ 1209 VCU_2_G_VehicleSystemFailure 0;
BA_ "E2EDataId" SG_ 1209 VCU_2_G_VehicleSystemFailure 93;
BA_ "E2EProfile" SG_ 1209 VCU_2_G_VehicleSystemFailure "P01";
BA_ "E2EDataLength" SG_ 1209 VCU_2_G_VehicleSystemFailure 64;
BA_ "GenSigSendType" SG_ 1209 VCU_2_G_BootloadSts 0;
BA_ "E2EDataId" SG_ 1209 VCU_2_G_BootloadSts 93;
BA_ "E2EProfile" SG_ 1209 VCU_2_G_BootloadSts "P01";
BA_ "E2EDataLength" SG_ 1209 VCU_2_G_BootloadSts 64;
BA_ "GenSigSendType" SG_ 1209 VCU_2_G_DischgSts 0;
BA_ "E2EDataId" SG_ 1209 VCU_2_G_DischgSts 93;
BA_ "E2EProfile" SG_ 1209 VCU_2_G_DischgSts "P01";
BA_ "E2EDataLength" SG_ 1209 VCU_2_G_DischgSts 64;
BA_ "GenSigSendType" SG_ 1209 VCU_2_G_BrakePedalStsValidData 0;
BA_ "E2EDataId" SG_ 1209 VCU_2_G_BrakePedalStsValidData 93;
BA_ "E2EProfile" SG_ 1209 VCU_2_G_BrakePedalStsValidData "P01";
BA_ "E2EDataLength" SG_ 1209 VCU_2_G_BrakePedalStsValidData 64;
BA_ "GenSigSendType" SG_ 1209 VCU_2_G_ExhibitionMod 0;
BA_ "E2EDataId" SG_ 1209 VCU_2_G_ExhibitionMod 93;
BA_ "E2EProfile" SG_ 1209 VCU_2_G_ExhibitionMod "P01";
BA_ "E2EDataLength" SG_ 1209 VCU_2_G_ExhibitionMod 64;
BA_ "GRC_Sig_ASIL" SG_ 1209 VCU_2_G_BrakePedalSts 3;
BA_ "GenSigSendType" SG_ 1209 VCU_2_G_BrakePedalSts 0;
BA_ "E2EDataId" SG_ 1209 VCU_2_G_BrakePedalSts 93;
BA_ "E2EProfile" SG_ 1209 VCU_2_G_BrakePedalSts "P01";
BA_ "E2EDataLength" SG_ 1209 VCU_2_G_BrakePedalSts 64;
BA_ "GenSigSendType" SG_ 1209 VCU_2_G_DCDCEnable 0;
BA_ "E2EDataId" SG_ 1209 VCU_2_G_DCDCEnable 93;
BA_ "E2EProfile" SG_ 1209 VCU_2_G_DCDCEnable "P01";
BA_ "E2EDataLength" SG_ 1209 VCU_2_G_DCDCEnable 64;
BA_ "GRC_Sig_ASIL" SG_ 1209 VCU_2_G_HVReady 3;
BA_ "GenSigSendType" SG_ 1209 VCU_2_G_HVReady 0;
BA_ "E2EDataId" SG_ 1209 VCU_2_G_HVReady 93;
BA_ "E2EProfile" SG_ 1209 VCU_2_G_HVReady "P01";
BA_ "E2EDataLength" SG_ 1209 VCU_2_G_HVReady 64;
BA_ "GenSigSendType" SG_ 1209 Res_VCU_2_G_Brake_state 0;
BA_ "E2EDataId" SG_ 1209 Res_VCU_2_G_Brake_state 93;
BA_ "E2EProfile" SG_ 1209 Res_VCU_2_G_Brake_state "P01";
BA_ "E2EDataLength" SG_ 1209 Res_VCU_2_G_Brake_state 64;
BA_ "GenSigSendType" SG_ 1209 VCU_2_G_VCUEnergyflow 0;
BA_ "E2EDataId" SG_ 1209 VCU_2_G_VCUEnergyflow 93;
BA_ "E2EProfile" SG_ 1209 VCU_2_G_VCUEnergyflow "P01";
BA_ "E2EDataLength" SG_ 1209 VCU_2_G_VCUEnergyflow 64;
BA_ "GenSigSendType" SG_ 1209 VCU_2_G_DrvGearShiftFailureIndcn 0;
BA_ "E2EDataId" SG_ 1209 VCU_2_G_DrvGearShiftFailureIndcn 93;
BA_ "E2EProfile" SG_ 1209 VCU_2_G_DrvGearShiftFailureIndcn "P01";
BA_ "E2EDataLength" SG_ 1209 VCU_2_G_DrvGearShiftFailureIndcn 64;
BA_ "GRC_Sig_ASIL" SG_ 1209 VCU_2_G_GasPedalPosition 3;
BA_ "GenSigSendType" SG_ 1209 VCU_2_G_GasPedalPosition 0;
BA_ "GenSigInvalidValue" SG_ 1209 VCU_2_G_GasPedalPosition 1023;
BA_ "E2EDataId" SG_ 1209 VCU_2_G_GasPedalPosition 93;
BA_ "E2EProfile" SG_ 1209 VCU_2_G_GasPedalPosition "P01";
BA_ "E2EDataLength" SG_ 1209 VCU_2_G_GasPedalPosition 64;
BA_ "GenSigSendType" SG_ 1229 VCU_CLTC_RangeAval 0;
BA_ "GenSigSendType" SG_ 1229 VCU_DynamicRangeAval 0;
BA_ "GenSigSendType" SG_ 1229 VCU_HighspdRangeAval 0;
BA_ "GenSigSendType" SG_ 1229 VCU_WLTC_RangeAval 0;
BA_ "GenSigSendType" SG_ 1263 VCU_TenECAver 0;
BA_ "GenSigInvalidValue" SG_ 1263 VCU_TenECAver 4095;
BA_ "GenSigStartValue" SG_ 1263 VCU_TenECAver 1000;
BA_ "GenSigSendType" SG_ 1263 VCU_twenty_fiveECAver 0;
BA_ "GenSigInvalidValue" SG_ 1263 VCU_twenty_fiveECAver 4095;
BA_ "GenSigStartValue" SG_ 1263 VCU_twenty_fiveECAver 1000;
BA_ "GenSigSendType" SG_ 1263 VCU_fiftyECAver 0;
BA_ "GenSigInvalidValue" SG_ 1263 VCU_fiftyECAver 4095;
BA_ "GenSigStartValue" SG_ 1263 VCU_fiftyECAver 1000;
BA_ "GenSigSendType" SG_ 1034 HCU_EmPwr 0;
BA_ "GenSigStartValue" SG_ 1034 HCU_EmPwr 128;
BA_ "GRC_Sig_ASIL" SG_ 1034 HCU_PowerModeFed 2;
BA_ "GenSigSendType" SG_ 1034 HCU_PowerModeFed 0;
BA_ "GenSigSendType" SG_ 1034 HCU_PowertrainFault 0;
BA_ "GenSigSendType" SG_ 1034 HCU_PowerModeChangeFail 0;
BA_ "GenSigSendType" SG_ 1034 HCU_ChargingSts 0;
BA_ "GenSigSendType" SG_ 1044 HCU_EnergyFlow 0;
BA_ "GenSigSendType" SG_ 1044 HCU_SetSOCFed 0;
BA_ "GenSigInvalidValue" SG_ 1044 HCU_SetSOCFed 255;
BA_ "GenSigSendType" SG_ 1044 HCU_2_G_LowBatteryInfo 0;
BA_ "GenSigSendType" SG_ 1204 Fusa_4B4_5 0;
BA_ "GenSigSendType" SG_ 1204 Fusa_4B4_4 0;
BA_ "GenSigSendType" SG_ 1204 Fusa_4B4_3 0;
BA_ "GenSigSendType" SG_ 1204 Fusa_4B4_2 0;
BA_ "GenSigSendType" SG_ 1204 Fusa_4B4_1 0;
BA_ "GenSigSendType" SG_ 1204 VCU_1_G_CRC 0;
BA_ "E2EDataId" SG_ 1204 VCU_1_G_CRC 92;
BA_ "E2EProfile" SG_ 1204 VCU_1_G_CRC "P01";
BA_ "E2EDataLength" SG_ 1204 VCU_1_G_CRC 64;
BA_ "GenSigSendType" SG_ 1204 VCU_1_G_RollgCntr 0;
BA_ "E2EDataId" SG_ 1204 VCU_1_G_RollgCntr 92;
BA_ "E2EProfile" SG_ 1204 VCU_1_G_RollgCntr "P01";
BA_ "E2EDataLength" SG_ 1204 VCU_1_G_RollgCntr 64;
BA_ "GenSigSendType" SG_ 1204 VCU_1_G_Pwr 0;
BA_ "GenSigStartValue" SG_ 1204 VCU_1_G_Pwr 500;
BA_ "E2EDataId" SG_ 1204 VCU_1_G_Pwr 92;
BA_ "E2EProfile" SG_ 1204 VCU_1_G_Pwr "P01";
BA_ "E2EDataLength" SG_ 1204 VCU_1_G_Pwr 64;
BA_ "GRC_Sig_ASIL" SG_ 1204 VCU_1_G_PTReady 3;
BA_ "GenSigSendType" SG_ 1204 VCU_1_G_PTReady 0;
BA_ "E2EDataId" SG_ 1204 VCU_1_G_PTReady 92;
BA_ "E2EProfile" SG_ 1204 VCU_1_G_PTReady "P01";
BA_ "E2EDataLength" SG_ 1204 VCU_1_G_PTReady 64;
BA_ "GRC_Sig_ASIL" SG_ 1204 VCU_1_G_DriveMode 3;
BA_ "GenSigSendType" SG_ 1204 VCU_1_G_DriveMode 0;
BA_ "GenSigStartValue" SG_ 1204 VCU_1_G_DriveMode 6;
BA_ "E2EDataId" SG_ 1204 VCU_1_G_DriveMode 92;
BA_ "E2EProfile" SG_ 1204 VCU_1_G_DriveMode "P01";
BA_ "E2EDataLength" SG_ 1204 VCU_1_G_DriveMode 64;
BA_ "GenSigSendType" SG_ 1204 VCU_1_G_BookChrgSetResponse 0;
BA_ "E2EDataId" SG_ 1204 VCU_1_G_BookChrgSetResponse 92;
BA_ "E2EProfile" SG_ 1204 VCU_1_G_BookChrgSetResponse "P01";
BA_ "E2EDataLength" SG_ 1204 VCU_1_G_BookChrgSetResponse 64;
BA_ "GenSigSendType" SG_ 1204 VCU_1_G_HvBattKeepWarmActiveReq 0;
BA_ "E2EDataId" SG_ 1204 VCU_1_G_HvBattKeepWarmActiveReq 92;
BA_ "E2EProfile" SG_ 1204 VCU_1_G_HvBattKeepWarmActiveReq "P01";
BA_ "E2EDataLength" SG_ 1204 VCU_1_G_HvBattKeepWarmActiveReq 64;
BA_ "GRC_Sig_ASIL" SG_ 1204 VCU_1_G_PRNDGearAct 3;
BA_ "GenSigSendType" SG_ 1204 VCU_1_G_PRNDGearAct 0;
BA_ "E2EDataId" SG_ 1204 VCU_1_G_PRNDGearAct 92;
BA_ "E2EProfile" SG_ 1204 VCU_1_G_PRNDGearAct "P01";
BA_ "E2EDataLength" SG_ 1204 VCU_1_G_PRNDGearAct 64;
BA_ "GenSigSendType" SG_ 1057 VCU_TowingMode 0;
BA_ "GenSigSendType" SG_ 1057 VCU_EngyConsuPer50Km 0;
BA_ "GenSigSendType" SG_ 1057 VCU_BookChrgSetFailRes 0;
BA_ "GenSigSendType" SG_ 1057 VCU_BookChrgFailRes 0;
BA_ "GenSigSendType" SG_ 1057 VCU_BookChrgStsFb 0;
BA_ "GenSigSendType" SG_ 1057 HCU_EngineSelfMaintain 0;
BA_ "GenSigSendType" SG_ 1043 EBS_U_BATT 0;
BA_ "GenSigInvalidValue" SG_ 1043 EBS_U_BATT 16383;
BA_ "GenSigStartValue" SG_ 1043 EBS_U_BATT 16383;
BA_ "GenSigSendType" SG_ 1022 FLZCU_FLogolightInhibitSts 0;
BA_ "GenSigSendType" SG_ 1022 MaintenanceOdometer_Backup_3FEh 0;
BA_ "GenSigSendType" SG_ 1022 FLZCU_CarMode 0;
BA_ "GenSigSendType" SG_ 1022 FLZCU_SteerWhlposSts 0;
BA_ "GenSigSendType" SG_ 1022 FLZCU_MedStatusFb 0;
BA_ "GenSigSendType" SG_ 1022 FLZCU_MedFailCause 0;
BA_ "GenSigSendType" SG_ 1022 FLZCU_MedAreaFb 0;
BA_ "GenSigSendType" SG_ 1022 FLZCU_MedClosePrompt 0;
BA_ "GenSigSendType" SG_ 1022 FLZCU_NapArea2Fb 0;
BA_ "GenSigSendType" SG_ 1022 FLZCU_2LSeatLvltargetCmd 0;
BA_ "GenSigInvalidValue" SG_ 1022 FLZCU_2LSeatLvltargetCmd 127;
BA_ "GenSigSendType" SG_ 1022 FLZCU_2LSeatBackAgtargetCmd 0;
BA_ "GenSigInvalidValue" SG_ 1022 FLZCU_2LSeatBackAgtargetCmd 127;
BA_ "GenSigSendType" SG_ 1022 FLZCU_2LSeatLegSpprttargetCmd 0;
BA_ "GenSigInvalidValue" SG_ 1022 FLZCU_2LSeatLegSpprttargetCmd 127;
BA_ "GenSigSendType" SG_ 1022 FLZCU_FLWinThermalStatus 0;
BA_ "GenSigSendType" SG_ 1022 FLZCU_RLWinThermalStatus 0;
BA_ "GenSigSendType" SG_ 1022 FLZCU_MonoAmbLigSts 0;
BA_ "GenSigSendType" SG_ 1022 FLZCU_LogoChargingSts 0;
BA_ "GenSigSendType" SG_ 1022 FLZCU_2RSeatLvltargetCmd 0;
BA_ "GenSigInvalidValue" SG_ 1022 FLZCU_2RSeatLvltargetCmd 127;
BA_ "GenSigSendType" SG_ 1022 FLZCU_2RSeatBackAgtargetCmd 0;
BA_ "GenSigInvalidValue" SG_ 1022 FLZCU_2RSeatBackAgtargetCmd 127;
BA_ "GenSigSendType" SG_ 1022 FLZCU_2RSeatLegSpprttargetCmd 0;
BA_ "GenSigInvalidValue" SG_ 1022 FLZCU_2RSeatLegSpprttargetCmd 127;
BA_ "GenSigSendType" SG_ 1022 FLZCU_SeatVentLvlFL2 0;
BA_ "GenSigSendType" SG_ 1022 FLZCU_SeatVentLvlRL2 0;
BA_ "GenSigSendType" SG_ 1022 FLZCU_SeatHeatLvlFL2 0;
BA_ "GenSigSendType" SG_ 1022 FLZCU_SeatHeatLvlRL2 0;
BA_ "GenSigSendType" SG_ 1022 FLZCU_FLSitPosnSts 0;
BA_ "GenSigSendType" SG_ 1022 FLZCU_SteerOverHeatWarn 0;
BA_ "GenSigSendType" SG_ 1020 CSA_2_WiprFrntCmd 0;
BA_ "GenSigStartValue" SG_ 1020 ASU_2_RRHeight 1500;
BA_ "GenSigSendType" SG_ 1020 ASU_2_RRHeight 0;
BA_ "GenSigStartValue" SG_ 1020 ASU_2_LRHeight 1500;
BA_ "GenSigSendType" SG_ 1020 ASU_2_LRHeight 0;
BA_ "GenSigStartValue" SG_ 1020 ASU_2_RFHeight 1500;
BA_ "GenSigSendType" SG_ 1020 ASU_2_RFHeight 0;
BA_ "GenSigStartValue" SG_ 1020 ASU_2_LFHeight 1500;
BA_ "GenSigSendType" SG_ 1020 ASU_2_LFHeight 0;
BA_ "GenSigSendType" SG_ 1020 ASU_2_sensorErrorSts 0;
BA_ "GenSigSendType" SG_ 1020 SAM_1_SteeringAngleSpeed 0;
BA_ "GenSigInvalidValue" SG_ 1020 SAM_1_SteeringAngleSpeed 255;
BA_ "GenSigStartValue" SG_ 1020 SAM_1_SteeringAngleSpeed 255;
BA_ "GenSigSendType" SG_ 1020 SAM_1_SteeringAngle 0;
BA_ "GenSigInvalidValue" SG_ 1020 SAM_1_SteeringAngle 65535;
BA_ "GenSigStartValue" SG_ 1020 SAM_1_SteeringAngle 65535;
BA_ "GenSigSendType" SG_ 1020 BMSH_MaxChgPwrPeak 0;
BA_ "GenSigInvalidValue" SG_ 1020 BMSH_MaxChgPwrPeak 4095;
BA_ "GenSigSendType" SG_ 1020 BMSH_MaxDchgPwrPeak 0;
BA_ "GenSigInvalidValue" SG_ 1020 BMSH_MaxDchgPwrPeak 4095;
BA_ "GRC_Sig_ASIL" SG_ 1020 FMCU_8_ISGF_SpdAct 2;
BA_ "GenSigSendType" SG_ 1020 FMCU_8_ISGF_SpdAct 0;
BA_ "GenSigInvalidValue" SG_ 1020 FMCU_8_ISGF_SpdAct 65535;
BA_ "GenSigStartValue" SG_ 1020 FMCU_8_ISGF_SpdAct 32767;
BA_ "GRC_Sig_ASIL" SG_ 1020 RMCU_1_Speed 4;
BA_ "GenSigSendType" SG_ 1020 RMCU_1_Speed 0;
BA_ "GenSigInvalidValue" SG_ 1020 RMCU_1_Speed 65535;
BA_ "GenSigStartValue" SG_ 1020 RMCU_1_Speed 32767;
BA_ "GenSigSendType" SG_ 1020 SAM_1_SteeringAngleVD 0;
BA_ "GenSigStartValue" SG_ 1020 SAM_1_SteeringAngleVD 1;
BA_ "GenSigSendType" SG_ 1020 SAM_1_SteeringAngleSpeedVD 0;
BA_ "GenSigStartValue" SG_ 1020 SAM_1_SteeringAngleSpeedVD 1;
BA_ "GRC_Sig_ASIL" SG_ 1020 CSA_2_AllWarningInfo 3;
BA_ "GenSigSendType" SG_ 1020 CSA_2_AllWarningInfo 0;
BA_ "GenSigStartValue" SG_ 1020 CSA_2_AllWarningInfo 7;
BA_ "GenSigSendType" SG_ 1020 RELC_RoofCampLampConfigDisp 0;
BA_ "GenSigSendType" SG_ 1020 RELC_TopLightConfigDisp 0;
BA_ "GenSigSendType" SG_ 1020 EELC_APillarLightConfigDisp 0;
BA_ "GenSigSendType" SG_ 1020 RELC_RoofCampLampStsL 0;
BA_ "GenSigSendType" SG_ 1020 RELC_RoofCampLampStsR 0;
BA_ "GenSigSendType" SG_ 1020 RELC_TopLightSts 0;
BA_ "GenSigSendType" SG_ 1020 EELC_APillarYellowAmbientSts 0;
BA_ "GenSigSendType" SG_ 1020 EELC_APillarWhiteAmbientSts 0;
BA_ "GenSigSendType" SG_ 1020 EELC_APillarSpotLampSts 0;
BA_ "GRC_Sig_ASIL" SG_ 1020 RMCU_1_TCURErrLvlDis 1;
BA_ "GenSigSendType" SG_ 1020 RMCU_1_TCURErrLvlDis 0;
BA_ "GenSigSendType" SG_ 1142 HCU_4_G_AvgFuCns 0;
BA_ "GenSigInvalidValue" SG_ 1142 HCU_4_G_AvgFuCns 511;
BA_ "GenSigSendType" SG_ 1142 HCU_4_G_AvgEnergyCns 0;
BA_ "GenSigInvalidValue" SG_ 1142 HCU_4_G_AvgEnergyCns 511;
BA_ "GenSigSendType" SG_ 1142 HCU_4_G_SumEgyCns 0;
BA_ "GenSigInvalidValue" SG_ 1142 HCU_4_G_SumEgyCns 511;
BA_ "GenSigSendType" SG_ 1314 DriveModeChangeFailReason_522h 0;
BA_ "GenSigSendType" SG_ 1314 HCU_DeepSnowSts_522h 0;
BA_ "GenSigSendType" SG_ 1314 HCU_CrossBorderSts 0;
BA_ "GenSigSendType" SG_ 1314 HCU_SumElecCns 0;
BA_ "GenSigInvalidValue" SG_ 1314 HCU_SumElecCns 4095;
BA_ "GenSigSendType" SG_ 1314 HCU_V2lDisChgBck 0;
BA_ "GenSigSendType" SG_ 1314 HCU_DisChgMemFed 0;
BA_ "GenSigSendType" SG_ 1314 HCU_V2VDisChgBck 0;
BA_ "GenSigSendType" SG_ 1314 HCU_V2l_IntlDisChgBck 0;
BA_ "GenSigSendType" SG_ 1314 HCU_FuelDetnOpDefeated 0;
BA_ "GenSigSendType" SG_ 1314 HCU_FuelDetnModSwtFed 0;
BA_ "GenSigSendType" SG_ 1314 HCU_FuelDetnStateFed 0;
BA_ "GenSigSendType" SG_ 1314 HCU_HVDownRepairModeFed 0;
BA_ "GenSigSendType" SG_ 1314 HCU_TrailerMode 0;
BA_ "GenSigSendType" SG_ 1314 HCU_SumFuCns 0;
BA_ "GenSigInvalidValue" SG_ 1314 HCU_SumFuCns 511;
BA_ "GenSigSendType" SG_ 1314 HCU_DrivePowerDispSetFed 0;
BA_ "GenSigSendType" SG_ 1314 HCU_KeyDriveModememory 0;
BA_ "GenSigSendType" SG_ 1314 HCU_DRIFTModeSts 0;
BA_ "GenSigSendType" SG_ 1314 HCU_EXPERTEcoFed 0;
BA_ "GenSigSendType" SG_ 1314 HCU_4LModeFed 0;
BA_ "GenSigSendType" SG_ 1314 HCU_EXPERTNormFed 0;
BA_ "GenSigSendType" SG_ 1314 HCU_SingleRegnRmn 0;
BA_ "GenSigSendType" SG_ 1314 HCU_EXPERTSportFed 0;
BA_ "GenSigSendType" SG_ 1314 HCU_CrossaxisFed 0;
BA_ "GenSigInvalidValue" SG_ 1314 HCU_CrossaxisFed 3;
BA_ "GenSigSendType" SG_ 1314 HCU_EXPERTRWDFed 0;
BA_ "GenSigSendType" SG_ 1314 HCU_EXPERTAWDFed 0;
BA_ "GenSigSendType" SG_ 1314 HCU_EXPERTAutoFed 0;
BA_ "GenSigSendType" SG_ 1314 HCU_CLIMBFed 0;
BA_ "GenSigSendType" SG_ 1314 HCU_StopChrgnFed 0;
BA_ "GenSigSendType" SG_ 1314 HCU_StopChrgnModeFed 0;
BA_ "GenSigSendType" SG_ 1314 HCU_ChrgnFctMemSt 0;
BA_ "GenSigSendType" SG_ 1314 HCU_LVPowSupSYSAbn_lit 0;
BA_ "GenSigSendType" SG_ 1314 HCU_IMMOReleaseSignal 0;
BA_ "GenSigSendType" SG_ 1314 HCU_PowerCut 0;
BA_ "GenSigSendType" SG_ 1314 HCU_ParkingChargeReminder 0;
BA_ "GenSigSendType" SG_ 1314 HCU_HEV_FunctionLimit 0;
BA_ "GenSigSendType" SG_ 1314 HCU_SetModeNotChange 0;
BA_ "GenSigSendType" SG_ 1314 HCU_UTURNSnowFed 0;
BA_ "GenSigSendType" SG_ 1314 HCU_DriveInhibit_GearP 0;
BA_ "GenSigSendType" SG_ 1314 HCU_AccleAbility_Limit 0;
BA_ "GenSigSendType" SG_ 1314 HCU_VehicleSpeedMax_Limit 0;
BA_ "GenSigSendType" SG_ 1314 HCU_EngineRunClmReq 0;
BA_ "GenSigSendType" SG_ 1314 HCU_DisconnectChagWarn 0;
BA_ "GenSigSendType" SG_ 1314 HCU_PowerModeChangeInhibit 0;
BA_ "GenSigSendType" SG_ 1314 HCU_DisChargeStopFault 0;
BA_ "GenSigSendType" SG_ 1314 HCU_DedicatedModeInhibit 0;
BA_ "GenSigSendType" SG_ 1314 HCU_LeaveVehicleWarning 0;
BA_ "GenSigSendType" SG_ 1314 HCU_TowingModeEna 0;
BA_ "GenSigSendType" SG_ 1314 HCU_PowerLevel 0;
BA_ "GenSigSendType" SG_ 1314 HCU_FrntEDLSts 0;
BA_ "GenSigSendType" SG_ 1314 HCU_RearEDLSts 0;
BA_ "GenSigSendType" SG_ 1314 HCU_DriveMode_JT 0;
BA_ "GenSigSendType" SG_ 1314 HCU_CruiseLimitSpeedValue 0;
BA_ "GenSigSendType" SG_ 1314 HCU_CCOSwtFed 0;
BA_ "GenSigSendType" SG_ 1314 HCU_SinglePedalMemFed 0;
BA_ "GenSigSendType" SG_ 1314 HCU_Pwr 0;
BA_ "GenSigInvalidValue" SG_ 1314 HCU_Pwr 4095;
BA_ "GenSigSendType" SG_ 1314 HCU_SocManageFed 0;
BA_ "GenSigSendType" SG_ 1314 HCU_EgyRegenLevel 0;
BA_ "GenSigSendType" SG_ 1314 HCU_DrvGearShiftFailureIndcn 0;
BA_ "GenSigSendType" SG_ 1314 HCU_EXPERTEESPSet 0;
BA_ "GenSigSendType" SG_ 1314 HCU_UTURNSandFed 0;
BA_ "GenSigSendType" SG_ 1314 HCU_CruiseControlStatus 0;
BA_ "GenSigSendType" SG_ 1314 HCU_LTCDispFed 0;
BA_ "GenSigSendType" SG_ 1314 HCU_UTURNMudFed 0;
BA_ "GenSigSendType" SG_ 1314 HCU_UTURNGrassFed 0;
BA_ "GenSigSendType" SG_ 1314 HCU_EngyFlowToDisp 0;
BA_ "GenSigSendType" SG_ 1314 HCU_DriveModeChangeFail 0;
BA_ "GenSigSendType" SG_ 1314 HCU_iCCO_Warn 0;
BA_ "GenSigSendType" SG_ 1314 HCU_iTAS_Warn 0;
BA_ "GenSigSendType" SG_ 1314 HCU_DraggingModeRemind 0;
BA_ "GenSigSendType" SG_ 1314 HCU_25_EDLFed 0;
BA_ "GenSigSendType" SG_ 1314 HCU_25_Crossaxis_Warn 0;
BA_ "GenSigSendType" SG_ 1314 HCU_iTAS_Active 0;
BA_ "GenSigSendType" SG_ 1314 HCU_ExterTempLowHint 0;
BA_ "GRC_Sig_ASIL" SG_ 1314 HCU_25_iTAS_SlopWarn 1;
BA_ "GenSigSendType" SG_ 1314 HCU_25_iTAS_SlopWarn 0;
BA_ "GenSigSendType" SG_ 1314 HCU_iTASSceneReq 0;
BA_ "GenSigSendType" SG_ 1314 HCU_DrivingModReq 0;
BA_ "GRC_Sig_ASIL" SG_ 1314 HCU_25_VehSpdOffroadRmn 1;
BA_ "GenSigSendType" SG_ 1314 HCU_25_VehSpdOffroadRmn 0;
BA_ "GRC_Sig_ASIL" SG_ 1314 HCU_25_LaunchMod_Warn 1;
BA_ "GenSigSendType" SG_ 1314 HCU_25_LaunchMod_Warn 0;
BA_ "GRC_Sig_ASIL" SG_ 1314 HCU_25_SetVehSpdOffroad 1;
BA_ "GenSigSendType" SG_ 1314 HCU_25_SetVehSpdOffroad 0;
BA_ "GenSigSendType" SG_ 1314 HCU_25_iDRIFT_Warn 0;
BA_ "GRC_Sig_ASIL" SG_ 1314 HCU_25_TAB_Warn 1;
BA_ "GenSigSendType" SG_ 1314 HCU_25_TAB_Warn 0;
BA_ "GRC_Sig_ASIL" SG_ 1314 HCU_25_CCO_TextDisp 1;
BA_ "GenSigSendType" SG_ 1314 HCU_25_CCO_TextDisp 0;
BA_ "GenSigSendType" SG_ 1075 VCC_2_ConfigurationMessageTrg 5;
BA_ "GenSigSendType" SG_ 1136 VCC_3_CRC 5;
BA_ "E2EDataId" SG_ 1136 VCC_3_CRC 112;
BA_ "E2EProfile" SG_ 1136 VCC_3_CRC "P01";
BA_ "E2EDataLength" SG_ 1136 VCC_3_CRC 64;
BA_ "GenSigSendType" SG_ 1136 VCC_3_RollgCntr 5;
BA_ "E2EDataId" SG_ 1136 VCC_3_RollgCntr 112;
BA_ "E2EProfile" SG_ 1136 VCC_3_RollgCntr "P01";
BA_ "E2EDataLength" SG_ 1136 VCC_3_RollgCntr 64;
BA_ "GenSigSendType" SG_ 1136 VCC_3_Resd1 5;
BA_ "E2EDataId" SG_ 1136 VCC_3_Resd1 112;
BA_ "E2EProfile" SG_ 1136 VCC_3_Resd1 "P01";
BA_ "E2EDataLength" SG_ 1136 VCC_3_Resd1 64;
BA_ "GenSigSendType" SG_ 1136 VCC_3_SN 5;
BA_ "GenSigStartValue" SG_ 1136 VCC_3_SN 1;
BA_ "E2EDataId" SG_ 1136 VCC_3_SN 112;
BA_ "E2EProfile" SG_ 1136 VCC_3_SN "P01";
BA_ "E2EDataLength" SG_ 1136 VCC_3_SN 64;
BA_ "GenSigSendType" SG_ 1196 TDL_SwitchSts 0;
BA_ "GenSigSendType" SG_ 1196 TDL_ColourModeSts 0;
BA_ "GenSigSendType" SG_ 1196 TDL_RhythmSwSts 0;
BA_ "GenSigSendType" SG_ 1196 TDL_ApiluminanceSts 0;
BA_ "GenSigSendType" SG_ 1196 TDL_VioceFunctionDone 0;
BA_ "GenSigSendType" SG_ 1196 TDL_FlowLightSwSts 0;
BA_ "GenSigSendType" SG_ 1196 TDL_FlowLightModeSts 0;
BA_ "GenSigSendType" SG_ 1196 TDL_RhythmModeSts 0;
BA_ "GenSigSendType" SG_ 1196 TDL_256ColourSts 0;
BA_ "GenSigStartValue" SG_ 1196 TDL_256ColourSts 127;
BA_ "GenSigSendType" SG_ 1177 FuelTankLidSts 0;
BA_ "GenSigSendType" SG_ 1177 FuelTankLidLockFailureSts 0;
BA_ "GenSigSendType" SG_ 1177 FuelTankLidSensorFailureSts 0;
BA_ "GenSigSendType" SG_ 1109 CWC_1_CRC1 0;
BA_ "GenSigSendType" SG_ 1109 CWC_1_RollgCntr1 0;
BA_ "GenSigSendType" SG_ 1109 CWC_1_Resd1 0;
BA_ "GenSigSendType" SG_ 1109 CWC_ChargingSts 0;
BA_ "GenSigSendType" SG_ 1109 CWC_workingSts 0;
BA_ "GenSigStartValue" SG_ 1109 CWC_workingSts 1;
BA_ "GenSigSendType" SG_ 1109 CWC_Phoneforgotten 0;
BA_ "GenSigSendType" SG_ 1109 CWC_Phoneforgotten_ON_OFF_Sts 0;
BA_ "GenSigStartValue" SG_ 1109 CWC_Phoneforgotten_ON_OFF_Sts 1;
BA_ "GenSigSendType" SG_ 1109 CWC_1_ChrgFlt 0;
BA_ "GenSigSendType" SG_ 1109 CWC_ChargingSts_R 0;
BA_ "GenSigSendType" SG_ 1109 CWC_workingSts_R 0;
BA_ "GenSigStartValue" SG_ 1109 CWC_workingSts_R 1;
BA_ "GenSigSendType" SG_ 1109 CWC_Phoneforgotten_R 0;
BA_ "GenSigSendType" SG_ 1109 CWC_Phoneforgotten_ON_OFF_Sts_R 0;
BA_ "GenSigStartValue" SG_ 1109 CWC_Phoneforgotten_ON_OFF_Sts_R 1;
BA_ "GenSigSendType" SG_ 1109 CWC_1_ChrgFlt_R 0;
BA_ "GenSigSendType" SG_ 1231 TBOX_1_BookChrgActiveReq 0;
BA_ "GenSigSendType" SG_ 1231 TBOX_BookChrgSts 0;
BA_ "GenSigSendType" SG_ 1231 TBOX_HvBattKeepWarmActiveReq 5;
BA_ "GenSigSendType" SG_ 1231 TBOX_BookChrgSetReq 5;
BA_ "GenSigSendType" SG_ 1231 TBOX_StopChrgReq 5;
BA_ "GenSigSendType" SG_ 1231 TBOX_KeepWarmSet 0;
BA_ "GenSigSendType" SG_ 1231 TBOX_HV_Req 0;
BA_ "GenSigSendType" SG_ 1288 CurrentTimeYear 0;
BA_ "GenSigSendType" SG_ 1288 CurrentTimeMonth 0;
BA_ "GenSigStartValue" SG_ 1288 CurrentTimeMonth 1;
BA_ "GenSigSendType" SG_ 1288 CurrentTimeDay 0;
BA_ "GenSigStartValue" SG_ 1288 CurrentTimeDay 1;
BA_ "GenSigSendType" SG_ 1288 CurrentTimeHour 0;
BA_ "GenSigSendType" SG_ 1288 CurrentTimeMinute 0;
BA_ "GenSigSendType" SG_ 1288 CurrentTimeSecond 0;
BA_ "GenSigSendType" SG_ 1063 TBOX_ElectronicFenceReq_427h 5;
BA_ "GenSigSendType" SG_ 1063 TBOX_SentinelModeSw 5;
BA_ "GenSigSendType" SG_ 1063 TBOX_PetmodeSwitch 5;
BA_ "GenSigSendType" SG_ 1148 ReservationSentinelSts_Fed_47Ch 0;
BA_ "GenSigInvalidValue" SG_ 1148 TimeToStopSentinelMinutFed_47Ch 63;
BA_ "GenSigStartValue" SG_ 1148 TimeToStopSentinelMinutFed_47Ch 62;
BA_ "GenSigSendType" SG_ 1148 TimeToStopSentinelMinutFed_47Ch 0;
BA_ "GenSigInvalidValue" SG_ 1148 TimeToStopSentinelHourFed_47Ch 31;
BA_ "GenSigStartValue" SG_ 1148 TimeToStopSentinelHourFed_47Ch 30;
BA_ "GenSigSendType" SG_ 1148 TimeToStopSentinelHourFed_47Ch 0;
BA_ "GenSigInvalidValue" SG_ 1148 TimeToStartSentinelMinutFed_47Ch 63;
BA_ "GenSigStartValue" SG_ 1148 TimeToStartSentinelMinutFed_47Ch 62;
BA_ "GenSigSendType" SG_ 1148 TimeToStartSentinelMinutFed_47Ch 0;
BA_ "GenSigInvalidValue" SG_ 1148 TimeToStartSentinelHourFed_47Ch 31;
BA_ "GenSigStartValue" SG_ 1148 TimeToStartSentinelHourFed_47Ch 30;
BA_ "GenSigSendType" SG_ 1148 TimeToStartSentinelHourFed_47Ch 0;
BA_ "GenSigSendType" SG_ 1148 TimeToStartSentinelDayFed_47Ch 0;
BA_ "GenSigSendType" SG_ 1148 TBOX_BkChrgStartTimeDay 0;
BA_ "GenSigStartValue" SG_ 1148 TBOX_BkChrgStartTimeDay 1;
BA_ "GenSigSendType" SG_ 1148 TBOX_BkChrgStartTimeeHour 0;
BA_ "GenSigSendType" SG_ 1148 TBOX_BkChrgStartTimeMin 0;
BA_ "GenSigSendType" SG_ 1148 TBOX_GPSSwitchSts 0;
BA_ "GenSigSendType" SG_ 1148 TBOX_BkChrgStartTimeMonth 0;
BA_ "GenSigStartValue" SG_ 1148 TBOX_BkChrgStartTimeMonth 1;
BA_ "GenSigSendType" SG_ 1148 TBOX_BkChrgStartTimeYear 0;
BA_ "GenSigSendType" SG_ 1148 TBOX_BkChrgDuration 0;
BA_ "GenSigSendType" SG_ 1148 TBOX_BkChrgCycleType 0;
BA_ "GenSigSendType" SG_ 1148 TBOX_BkChrgCycleMon 0;
BA_ "GenSigSendType" SG_ 1148 TBOX_BkChrgCycleTues 0;
BA_ "GenSigSendType" SG_ 1148 TBOX_BkChrgCycleWen 0;
BA_ "GenSigSendType" SG_ 1148 TBOX_BkChrgCycleThur 0;
BA_ "GenSigSendType" SG_ 1148 TBOX_BkChrgCycleFri 0;
BA_ "GenSigSendType" SG_ 1148 TBOX_BkChrgCycleSat 0;
BA_ "GenSigSendType" SG_ 1148 TBOX_BkChrgCycleSun 0;
BA_ "GenSigSendType" SG_ 1148 TBOX_KeepWarmStrt 0;
BA_ "GenSigStartValue" SG_ 1148 TBOX_KeepWarmStrt 1;
BA_ "GenSigSendType" SG_ 1148 TBOX_KeepWarmStrtHour 0;
BA_ "GenSigSendType" SG_ 1148 TBOX_KeepWarmStrtMin 0;
BA_ "GenSigSendType" SG_ 1162 Fusa_48A_3 0;
BA_ "GenSigSendType" SG_ 1162 Fusa_48A_2 0;
BA_ "GenSigSendType" SG_ 1162 Fusa_48A_1 0;
BA_ "GenSigSendType" SG_ 1162 ONEBOX_1_G_CRC 0;
BA_ "E2EDataId" SG_ 1162 ONEBOX_1_G_CRC 86;
BA_ "E2EProfile" SG_ 1162 ONEBOX_1_G_CRC "P01";
BA_ "E2EDataLength" SG_ 1162 ONEBOX_1_G_CRC 64;
BA_ "GenSigSendType" SG_ 1162 ONEBOX_1_G_RollgCntr 0;
BA_ "E2EDataId" SG_ 1162 ONEBOX_1_G_RollgCntr 86;
BA_ "E2EProfile" SG_ 1162 ONEBOX_1_G_RollgCntr "P01";
BA_ "E2EDataLength" SG_ 1162 ONEBOX_1_G_RollgCntr 64;
BA_ "GRC_Sig_ASIL" SG_ 1162 VehicleSpeedVSOSig 3;
BA_ "GenSigSendType" SG_ 1162 VehicleSpeedVSOSig 0;
BA_ "GenSigInvalidValue" SG_ 1162 VehicleSpeedVSOSig 8191;
BA_ "E2EDataId" SG_ 1162 VehicleSpeedVSOSig 86;
BA_ "E2EProfile" SG_ 1162 VehicleSpeedVSOSig "P01";
BA_ "E2EDataLength" SG_ 1162 VehicleSpeedVSOSig 64;
BA_ "GRC_Sig_ASIL" SG_ 1162 VehicleSpeedVSOSigValidData 3;
BA_ "GenSigSendType" SG_ 1162 VehicleSpeedVSOSigValidData 0;
BA_ "GenSigStartValue" SG_ 1162 VehicleSpeedVSOSigValidData 1;
BA_ "E2EDataId" SG_ 1162 VehicleSpeedVSOSigValidData 86;
BA_ "E2EProfile" SG_ 1162 VehicleSpeedVSOSigValidData "P01";
BA_ "E2EDataLength" SG_ 1162 VehicleSpeedVSOSigValidData 64;
BA_ "GRC_Sig_ASIL" SG_ 1162 ESPSwitchStatus 3;
BA_ "GenSigSendType" SG_ 1162 ESPSwitchStatus 0;
BA_ "E2EDataId" SG_ 1162 ESPSwitchStatus 86;
BA_ "E2EProfile" SG_ 1162 ESPSwitchStatus "P01";
BA_ "E2EDataLength" SG_ 1162 ESPSwitchStatus 64;
BA_ "GRC_Sig_ASIL" SG_ 1162 ABSActive 3;
BA_ "GenSigSendType" SG_ 1162 ABSActive 0;
BA_ "E2EDataId" SG_ 1162 ABSActive 86;
BA_ "E2EProfile" SG_ 1162 ABSActive "P01";
BA_ "E2EDataLength" SG_ 1162 ABSActive 64;
BA_ "GRC_Sig_ASIL" SG_ 1162 ABSFailSts 3;
BA_ "GenSigSendType" SG_ 1162 ABSFailSts 0;
BA_ "E2EDataId" SG_ 1162 ABSFailSts 86;
BA_ "E2EProfile" SG_ 1162 ABSFailSts "P01";
BA_ "E2EDataLength" SG_ 1162 ABSFailSts 64;
BA_ "GRC_Sig_ASIL" SG_ 1162 EBDFailSts 3;
BA_ "GenSigSendType" SG_ 1162 EBDFailSts 0;
BA_ "E2EDataId" SG_ 1162 EBDFailSts 86;
BA_ "E2EProfile" SG_ 1162 EBDFailSts "P01";
BA_ "E2EDataLength" SG_ 1162 EBDFailSts 64;
BA_ "GRC_Sig_ASIL" SG_ 1162 TCSFailSts 3;
BA_ "GenSigSendType" SG_ 1162 TCSFailSts 0;
BA_ "E2EDataId" SG_ 1162 TCSFailSts 86;
BA_ "E2EProfile" SG_ 1162 TCSFailSts "P01";
BA_ "E2EDataLength" SG_ 1162 TCSFailSts 64;
BA_ "GRC_Sig_ASIL" SG_ 1162 VDCFailSts 3;
BA_ "GenSigSendType" SG_ 1162 VDCFailSts 0;
BA_ "E2EDataId" SG_ 1162 VDCFailSts 86;
BA_ "E2EProfile" SG_ 1162 VDCFailSts "P01";
BA_ "E2EDataLength" SG_ 1162 VDCFailSts 64;
BA_ "GRC_Sig_ASIL" SG_ 1162 TCSActive 3;
BA_ "GenSigSendType" SG_ 1162 TCSActive 0;
BA_ "E2EDataId" SG_ 1162 TCSActive 86;
BA_ "E2EProfile" SG_ 1162 TCSActive "P01";
BA_ "E2EDataLength" SG_ 1162 TCSActive 64;
BA_ "GRC_Sig_ASIL" SG_ 1162 VDCActive 3;
BA_ "GenSigSendType" SG_ 1162 VDCActive 0;
BA_ "E2EDataId" SG_ 1162 VDCActive 86;
BA_ "E2EProfile" SG_ 1162 VDCActive "P01";
BA_ "E2EDataLength" SG_ 1162 VDCActive 64;
BA_ "GenSigSendType" SG_ 1162 BLRequestController 0;
BA_ "E2EDataId" SG_ 1162 BLRequestController 86;
BA_ "E2EProfile" SG_ 1162 BLRequestController "P01";
BA_ "E2EDataLength" SG_ 1162 BLRequestController 64;
BA_ "GenSigSendType" SG_ 1202 Activeheatingmode 0;
BA_ "GenSigSendType" SG_ 1202 FuelRollingCounter 0;
BA_ "GenSigInvalidValue" SG_ 1202 FuelRollingCounter 255;
BA_ "GenSigStartValue" SG_ 1202 FuelRollingCounter 255;
BA_ "GenSigSendType" SG_ 1202 MILSts 0;
BA_ "GenSigStartValue" SG_ 1202 MILSts 2;
BA_ "GenSigSendType" SG_ 1202 GPFWarning 0;
BA_ "GenSigSendType" SG_ 1202 EngineSpeed 0;
BA_ "GenSigInvalidValue" SG_ 1202 EngineSpeed 2047;
BA_ "GenSigSendType" SG_ 1202 EngineSpeedValidData 0;
BA_ "GenSigSendType" SG_ 1202 EPCSts 0;
BA_ "GenSigStartValue" SG_ 1202 EPCSts 1;
BA_ "GenSigSendType" SG_ 1202 EMS_1_G_EngineSts 0;
BA_ "GenSigSendType" SG_ 1202 EMS_EngineSts_Actual 0;
BA_ "GenSigSendType" SG_ 1202 OilPressureWarningLamp 0;
BA_ "GRC_Sig_ASIL" SG_ 683 RHFDoorSts 2;
BA_ "GenSigSendType" SG_ 683 RHFDoorSts 0;
BA_ "GenSigSendType" SG_ 683 FRZCU_1_ParkLightSts 0;
BA_ "GenSigSendType" SG_ 683 FRWinPosn 0;
BA_ "GenSigInvalidValue" SG_ 683 FRWinPosn 127;
BA_ "GenSigStartValue" SG_ 683 FRWinPosn 127;
BA_ "GenSigSendType" SG_ 683 RRWinPosn 0;
BA_ "GenSigInvalidValue" SG_ 683 RRWinPosn 127;
BA_ "GenSigStartValue" SG_ 683 RRWinPosn 127;
BA_ "GRC_Sig_ASIL" SG_ 683 RHRDoorSts 2;
BA_ "GenSigSendType" SG_ 683 RHRDoorSts 0;
BA_ "GRC_Sig_ASIL" SG_ 33 ACU_3_LongitudinalAcceleration 3;
BA_ "GenSigSendType" SG_ 33 ACU_3_LongitudinalAcceleration 0;
BA_ "GenSigInvalidValue" SG_ 33 ACU_3_LongitudinalAcceleration 65535;
BA_ "GenSigStartValue" SG_ 33 ACU_3_LongitudinalAcceleration 2000;
BA_ "GRC_Sig_ASIL" SG_ 33 ACU_3_LongitudinalAccelerationVD 3;
BA_ "GenSigSendType" SG_ 33 ACU_3_LongitudinalAccelerationVD 0;
BA_ "GenSigStartValue" SG_ 33 ACU_3_LongitudinalAccelerationVD 3;
BA_ "GenSigSendType" SG_ 632 EngineCoolantTemperature 0;
BA_ "GenSigInvalidValue" SG_ 632 EngineCoolantTemperature 255;
BA_ "GenSigStartValue" SG_ 632 EngineCoolantTemperature 91;
BA_ "GRC_Sig_ASIL" SG_ 1217 ASU_1_ASUSysFailrSts 3;
BA_ "GenSigSendType" SG_ 1217 ASU_1_ASUSysFailrSts 0;
BA_ "GenSigStartValue" SG_ 1217 ASU_1_ASUSysFailrSts 1;
BA_ "GRC_Sig_ASIL" SG_ 1217 ASU_1_SuspCurrentLvl 3;
BA_ "GenSigSendType" SG_ 1217 ASU_1_SuspCurrentLvl 0;
BA_ "GRC_Sig_ASIL" SG_ 1217 ASU_1_ECASSysSts 3;
BA_ "GenSigSendType" SG_ 1217 ASU_1_ECASSysSts 0;
BA_ "GRC_Sig_ASIL" SG_ 1217 ASU_1_ECASErrSts 3;
BA_ "GenSigSendType" SG_ 1217 ASU_1_ECASErrSts 0;
BA_ "GRC_Sig_ASIL" SG_ 1217 ASU_1_SuspTarLvl 3;
BA_ "GenSigSendType" SG_ 1217 ASU_1_SuspTarLvl 0;
BA_ "GRC_Sig_ASIL" SG_ 1217 ASU_1_EasyEntryEna 3;
BA_ "GenSigSendType" SG_ 1217 ASU_1_EasyEntryEna 0;
BA_ "GRC_Sig_ASIL" SG_ 1217 ASU_1_CDCErrSts 3;
BA_ "GenSigSendType" SG_ 1217 ASU_1_CDCErrSts 0;
BA_ "GenSigSendType" SG_ 1217 ASU_1_RearaxlewithTaildoorFb 0;
BA_ "GenSigSendType" SG_ 1217 ASU_1_Overheat_warning 0;
BA_ "GRC_Sig_ASIL" SG_ 1217 ASU_1_MaintainMod 3;
BA_ "GenSigSendType" SG_ 1217 ASU_1_MaintainMod 0;
BA_ "GenSigSendType" SG_ 1217 ASU_1_drivemodeheightlevFb 0;
BA_ "GenSigSendType" SG_ 1217 ASU_1_HMIFailFb 0;
BA_ "GenSigSendType" SG_ 1217 ASU_1_AssistPass 0;
BA_ "GenSigSendType" SG_ 258 BMS_1_CRC1 0;
BA_ "E2EDataId" SG_ 258 BMS_1_CRC1 20;
BA_ "E2EProfile" SG_ 258 BMS_1_CRC1 "P01";
BA_ "E2EDataLength" SG_ 258 BMS_1_CRC1 64;
BA_ "GenSigSendType" SG_ 258 BMS_1_RollgCntr1 0;
BA_ "E2EDataId" SG_ 258 BMS_1_RollgCntr1 20;
BA_ "E2EProfile" SG_ 258 BMS_1_RollgCntr1 "P01";
BA_ "E2EDataLength" SG_ 258 BMS_1_RollgCntr1 64;
BA_ "GenSigSendType" SG_ 258 BMS_1_Resd1 0;
BA_ "E2EDataId" SG_ 258 BMS_1_Resd1 20;
BA_ "E2EProfile" SG_ 258 BMS_1_Resd1 "P01";
BA_ "E2EDataLength" SG_ 258 BMS_1_Resd1 64;
BA_ "GRC_Sig_ASIL" SG_ 258 BMS_PackVoltage 4;
BA_ "GenSigSendType" SG_ 258 BMS_PackVoltage 0;
BA_ "GenSigInvalidValue" SG_ 258 BMS_PackVoltage 65535;
BA_ "GenSigStartValue" SG_ 258 BMS_PackVoltage 65535;
BA_ "E2EDataId" SG_ 258 BMS_PackVoltage 20;
BA_ "E2EProfile" SG_ 258 BMS_PackVoltage "P01";
BA_ "E2EDataLength" SG_ 258 BMS_PackVoltage 64;
BA_ "GRC_Sig_ASIL" SG_ 258 BMS_PackCurrent 4;
BA_ "GenSigSendType" SG_ 258 BMS_PackCurrent 0;
BA_ "GenSigInvalidValue" SG_ 258 BMS_PackCurrent 65535;
BA_ "GenSigStartValue" SG_ 258 BMS_PackCurrent 65535;
BA_ "E2EDataId" SG_ 258 BMS_PackCurrent 20;
BA_ "E2EProfile" SG_ 258 BMS_PackCurrent "P01";
BA_ "E2EDataLength" SG_ 258 BMS_PackCurrent 64;
BA_ "GRC_Sig_ASIL" SG_ 258 BMS_HvBattSts 2;
BA_ "GenSigSendType" SG_ 258 BMS_HvBattSts 0;
BA_ "E2EDataId" SG_ 258 BMS_HvBattSts 20;
BA_ "E2EProfile" SG_ 258 BMS_HvBattSts "P01";
BA_ "E2EDataLength" SG_ 258 BMS_HvBattSts 64;
BA_ "GenSigSendType" SG_ 258 BMS_SysSelfCheck 0;
BA_ "E2EDataId" SG_ 258 BMS_SysSelfCheck 20;
BA_ "E2EProfile" SG_ 258 BMS_SysSelfCheck "P01";
BA_ "E2EDataLength" SG_ 258 BMS_SysSelfCheck 64;
BA_ "GRC_Sig_ASIL" SG_ 258 BMS_HVBattThermRunaway 4;
BA_ "GenSigSendType" SG_ 258 BMS_HVBattThermRunaway 0;
BA_ "GenSigInvalidValue" SG_ 258 BMS_HVBattThermRunaway 2;
BA_ "E2EDataId" SG_ 258 BMS_HVBattThermRunaway 20;
BA_ "E2EProfile" SG_ 258 BMS_HVBattThermRunaway "P01";
BA_ "E2EDataLength" SG_ 258 BMS_HVBattThermRunaway 64;
BA_ "GenSigSendType" SG_ 258 BMS_1_CRC2 0;
BA_ "GenSigSendType" SG_ 258 BMS_1_RollgCntr2 0;
BA_ "GenSigSendType" SG_ 258 BMS_1_Resd2 0;
BA_ "GenSigSendType" SG_ 258 BMS_ChargeVoltageReq 0;
BA_ "GenSigStartValue" SG_ 258 BMS_ChargeVoltageReq 16382;
BA_ "GenSigSendType" SG_ 258 BMS_ChgCurrReq 0;
BA_ "GenSigStartValue" SG_ 258 BMS_ChgCurrReq 16382;
BA_ "GenSigSendType" SG_ 258 BMS_InfraDcUActDc 0;
BA_ "GenSigStartValue" SG_ 258 BMS_InfraDcUActDc 16382;
BA_ "GenSigSendType" SG_ 258 BMS_1_CRC3 0;
BA_ "E2EDataId" SG_ 258 BMS_1_CRC3 21;
BA_ "E2EProfile" SG_ 258 BMS_1_CRC3 "P01";
BA_ "E2EDataLength" SG_ 258 BMS_1_CRC3 64;
BA_ "GenSigSendType" SG_ 258 BMS_1_RollgCntr3 0;
BA_ "E2EDataId" SG_ 258 BMS_1_RollgCntr3 21;
BA_ "E2EProfile" SG_ 258 BMS_1_RollgCntr3 "P01";
BA_ "E2EDataLength" SG_ 258 BMS_1_RollgCntr3 64;
BA_ "GenSigSendType" SG_ 258 BMS_1_Resd3 0;
BA_ "E2EDataId" SG_ 258 BMS_1_Resd3 21;
BA_ "E2EProfile" SG_ 258 BMS_1_Resd3 "P01";
BA_ "E2EDataLength" SG_ 258 BMS_1_Resd3 64;
BA_ "GenSigSendType" SG_ 258 BMS_InfraDcIActDc 0;
BA_ "GenSigStartValue" SG_ 258 BMS_InfraDcIActDc 16382;
BA_ "E2EDataId" SG_ 258 BMS_InfraDcIActDc 21;
BA_ "E2EProfile" SG_ 258 BMS_InfraDcIActDc "P01";
BA_ "E2EDataLength" SG_ 258 BMS_InfraDcIActDc 64;
BA_ "GRC_Sig_ASIL" SG_ 258 BMS_HvBattDynChrgnILim 4;
BA_ "GenSigSendType" SG_ 258 BMS_HvBattDynChrgnILim 0;
BA_ "GenSigStartValue" SG_ 258 BMS_HvBattDynChrgnILim 16382;
BA_ "E2EDataId" SG_ 258 BMS_HvBattDynChrgnILim 21;
BA_ "E2EProfile" SG_ 258 BMS_HvBattDynChrgnILim "P01";
BA_ "E2EDataLength" SG_ 258 BMS_HvBattDynChrgnILim 64;
BA_ "GRC_Sig_ASIL" SG_ 258 BMS_HvBattUChrgnLim 4;
BA_ "GenSigSendType" SG_ 258 BMS_HvBattUChrgnLim 0;
BA_ "GenSigStartValue" SG_ 258 BMS_HvBattUChrgnLim 16382;
BA_ "E2EDataId" SG_ 258 BMS_HvBattUChrgnLim 21;
BA_ "E2EProfile" SG_ 258 BMS_HvBattUChrgnLim "P01";
BA_ "E2EDataLength" SG_ 258 BMS_HvBattUChrgnLim 64;
BA_ "GenSigSendType" SG_ 258 BMS_1_CRC4 0;
BA_ "E2EDataId" SG_ 258 BMS_1_CRC4 22;
BA_ "E2EProfile" SG_ 258 BMS_1_CRC4 "P01";
BA_ "E2EDataLength" SG_ 258 BMS_1_CRC4 64;
BA_ "GenSigSendType" SG_ 258 BMS_1_RollgCntr4 0;
BA_ "E2EDataId" SG_ 258 BMS_1_RollgCntr4 22;
BA_ "E2EProfile" SG_ 258 BMS_1_RollgCntr4 "P01";
BA_ "E2EDataLength" SG_ 258 BMS_1_RollgCntr4 64;
BA_ "GenSigSendType" SG_ 258 BMS_1_Resd4 0;
BA_ "E2EDataId" SG_ 258 BMS_1_Resd4 22;
BA_ "E2EProfile" SG_ 258 BMS_1_Resd4 "P01";
BA_ "E2EDataLength" SG_ 258 BMS_1_Resd4 64;
BA_ "GenSigSendType" SG_ 258 BMS_DChrgAPlusSt 0;
BA_ "E2EDataId" SG_ 258 BMS_DChrgAPlusSt 22;
BA_ "E2EProfile" SG_ 258 BMS_DChrgAPlusSt "P01";
BA_ "E2EDataLength" SG_ 258 BMS_DChrgAPlusSt 64;
BA_ "GenSigSendType" SG_ 258 BMS_ChrgDcIAvl 0;
BA_ "GenSigStartValue" SG_ 258 BMS_ChrgDcIAvl 16382;
BA_ "E2EDataId" SG_ 258 BMS_ChrgDcIAvl 22;
BA_ "E2EProfile" SG_ 258 BMS_ChrgDcIAvl "P01";
BA_ "E2EDataLength" SG_ 258 BMS_ChrgDcIAvl 64;
BA_ "GRC_Sig_ASIL" SG_ 258 BMS_Insulation_R 3;
BA_ "GenSigSendType" SG_ 258 BMS_Insulation_R 0;
BA_ "E2EDataId" SG_ 258 BMS_Insulation_R 22;
BA_ "E2EProfile" SG_ 258 BMS_Insulation_R "P01";
BA_ "E2EDataLength" SG_ 258 BMS_Insulation_R 64;
BA_ "GRC_Sig_ASIL" SG_ 258 BMS_ChrgDcCnctrDetd 3;
BA_ "GenSigSendType" SG_ 258 BMS_ChrgDcCnctrDetd 0;
BA_ "E2EDataId" SG_ 258 BMS_ChrgDcCnctrDetd 22;
BA_ "E2EProfile" SG_ 258 BMS_ChrgDcCnctrDetd "P01";
BA_ "E2EDataLength" SG_ 258 BMS_ChrgDcCnctrDetd 64;
BA_ "GenSigSendType" SG_ 258 BMS_DCChgMode 0;
BA_ "E2EDataId" SG_ 258 BMS_DCChgMode 22;
BA_ "E2EProfile" SG_ 258 BMS_DCChgMode "P01";
BA_ "E2EDataLength" SG_ 258 BMS_DCChgMode 64;
BA_ "GenSigSendType" SG_ 258 BMS_ChrgDcChrgnFltStopReas 0;
BA_ "E2EDataId" SG_ 258 BMS_ChrgDcChrgnFltStopReas 22;
BA_ "E2EProfile" SG_ 258 BMS_ChrgDcChrgnFltStopReas "P01";
BA_ "E2EDataLength" SG_ 258 BMS_ChrgDcChrgnFltStopReas 64;
BA_ "GenSigSendType" SG_ 258 BMS_1_CRC5 0;
BA_ "E2EDataId" SG_ 258 BMS_1_CRC5 23;
BA_ "E2EProfile" SG_ 258 BMS_1_CRC5 "P01";
BA_ "E2EDataLength" SG_ 258 BMS_1_CRC5 64;
BA_ "GenSigSendType" SG_ 258 BMS_1_RollgCntr5 0;
BA_ "E2EDataId" SG_ 258 BMS_1_RollgCntr5 23;
BA_ "E2EProfile" SG_ 258 BMS_1_RollgCntr5 "P01";
BA_ "E2EDataLength" SG_ 258 BMS_1_RollgCntr5 64;
BA_ "GenSigSendType" SG_ 258 BMS_1_Resd5 0;
BA_ "E2EDataId" SG_ 258 BMS_1_Resd5 23;
BA_ "E2EProfile" SG_ 258 BMS_1_Resd5 "P01";
BA_ "E2EDataLength" SG_ 258 BMS_1_Resd5 64;
BA_ "GRC_Sig_ASIL" SG_ 258 BMS_ChargeRequest_Mode 2;
BA_ "GenSigSendType" SG_ 258 BMS_ChargeRequest_Mode 0;
BA_ "E2EDataId" SG_ 258 BMS_ChargeRequest_Mode 23;
BA_ "E2EProfile" SG_ 258 BMS_ChargeRequest_Mode "P01";
BA_ "E2EDataLength" SG_ 258 BMS_ChargeRequest_Mode 64;
BA_ "GenSigSendType" SG_ 258 BMS_ChgRemTime 0;
BA_ "GenSigStartValue" SG_ 258 BMS_ChgRemTime 2047;
BA_ "E2EDataId" SG_ 258 BMS_ChgRemTime 23;
BA_ "E2EProfile" SG_ 258 BMS_ChgRemTime "P01";
BA_ "E2EDataLength" SG_ 258 BMS_ChgRemTime 64;
BA_ "GRC_Sig_ASIL" SG_ 258 BMS_1_StateOfChargeDis 2;
BA_ "GenSigSendType" SG_ 258 BMS_1_StateOfChargeDis 0;
BA_ "GenSigInvalidValue" SG_ 258 BMS_1_StateOfChargeDis 255;
BA_ "GenSigStartValue" SG_ 258 BMS_1_StateOfChargeDis 255;
BA_ "E2EDataId" SG_ 258 BMS_1_StateOfChargeDis 23;
BA_ "E2EProfile" SG_ 258 BMS_1_StateOfChargeDis "P01";
BA_ "E2EDataLength" SG_ 258 BMS_1_StateOfChargeDis 64;
BA_ "GenSigSendType" SG_ 258 BMS_StateOfEnergy 0;
BA_ "GenSigInvalidValue" SG_ 258 BMS_StateOfEnergy 65535;
BA_ "GenSigStartValue" SG_ 258 BMS_StateOfEnergy 65535;
BA_ "E2EDataId" SG_ 258 BMS_StateOfEnergy 23;
BA_ "E2EProfile" SG_ 258 BMS_StateOfEnergy "P01";
BA_ "E2EDataLength" SG_ 258 BMS_StateOfEnergy 64;
BA_ "GenSigSendType" SG_ 258 BMS_1_CRC6 0;
BA_ "E2EDataId" SG_ 258 BMS_1_CRC6 24;
BA_ "E2EProfile" SG_ 258 BMS_1_CRC6 "P01";
BA_ "E2EDataLength" SG_ 258 BMS_1_CRC6 64;
BA_ "GenSigSendType" SG_ 258 BMS_1_RollgCntr6 0;
BA_ "E2EDataId" SG_ 258 BMS_1_RollgCntr6 24;
BA_ "E2EProfile" SG_ 258 BMS_1_RollgCntr6 "P01";
BA_ "E2EDataLength" SG_ 258 BMS_1_RollgCntr6 64;
BA_ "GenSigSendType" SG_ 258 BMS_1_Resd6 0;
BA_ "E2EDataId" SG_ 258 BMS_1_Resd6 24;
BA_ "E2EProfile" SG_ 258 BMS_1_Resd6 "P01";
BA_ "E2EDataLength" SG_ 258 BMS_1_Resd6 64;
BA_ "GenSigSendType" SG_ 258 BMS_StateOfHealth 0;
BA_ "E2EDataId" SG_ 258 BMS_StateOfHealth 24;
BA_ "E2EProfile" SG_ 258 BMS_StateOfHealth "P01";
BA_ "E2EDataLength" SG_ 258 BMS_StateOfHealth 64;
BA_ "GenSigSendType" SG_ 258 BMS_BlanceState 0;
BA_ "E2EDataId" SG_ 258 BMS_BlanceState 24;
BA_ "E2EProfile" SG_ 258 BMS_BlanceState "P01";
BA_ "E2EDataLength" SG_ 258 BMS_BlanceState 64;
BA_ "GRC_Sig_ASIL" SG_ 258 BMS_IsolationFault 3;
BA_ "GenSigSendType" SG_ 258 BMS_IsolationFault 0;
BA_ "E2EDataId" SG_ 258 BMS_IsolationFault 24;
BA_ "E2EProfile" SG_ 258 BMS_IsolationFault "P01";
BA_ "E2EDataLength" SG_ 258 BMS_IsolationFault 64;
BA_ "GRC_Sig_ASIL" SG_ 258 BMS_HVILFault_DC 3;
BA_ "GenSigSendType" SG_ 258 BMS_HVILFault_DC 0;
BA_ "E2EDataId" SG_ 258 BMS_HVILFault_DC 24;
BA_ "E2EProfile" SG_ 258 BMS_HVILFault_DC "P01";
BA_ "E2EDataLength" SG_ 258 BMS_HVILFault_DC 64;
BA_ "GRC_Sig_ASIL" SG_ 258 BMS_HVILFault_FMCU 3;
BA_ "GenSigSendType" SG_ 258 BMS_HVILFault_FMCU 0;
BA_ "E2EDataId" SG_ 258 BMS_HVILFault_FMCU 24;
BA_ "E2EProfile" SG_ 258 BMS_HVILFault_FMCU "P01";
BA_ "E2EDataLength" SG_ 258 BMS_HVILFault_FMCU 64;
BA_ "GRC_Sig_ASIL" SG_ 258 BMS_HVILFault_RMCU 3;
BA_ "GenSigSendType" SG_ 258 BMS_HVILFault_RMCU 0;
BA_ "E2EDataId" SG_ 258 BMS_HVILFault_RMCU 24;
BA_ "E2EProfile" SG_ 258 BMS_HVILFault_RMCU "P01";
BA_ "E2EDataLength" SG_ 258 BMS_HVILFault_RMCU 64;
BA_ "GenSigSendType" SG_ 258 BMS_SOCDis 0;
BA_ "GenSigInvalidValue" SG_ 258 BMS_SOCDis 16383;
BA_ "GenSigStartValue" SG_ 258 BMS_SOCDis 16383;
BA_ "E2EDataId" SG_ 258 BMS_SOCDis 24;
BA_ "E2EProfile" SG_ 258 BMS_SOCDis "P01";
BA_ "E2EDataLength" SG_ 258 BMS_SOCDis 64;
BA_ "GenSigSendType" SG_ 258 BMS_InfraDcIActDcMin 0;
BA_ "GenSigStartValue" SG_ 258 BMS_InfraDcIActDcMin 16383;
BA_ "E2EDataId" SG_ 258 BMS_InfraDcIActDcMin 24;
BA_ "E2EProfile" SG_ 258 BMS_InfraDcIActDcMin "P01";
BA_ "E2EDataLength" SG_ 258 BMS_InfraDcIActDcMin 64;
BA_ "GenSigSendType" SG_ 1290 BMS_8_CRC1 0;
BA_ "E2EDataId" SG_ 1290 BMS_8_CRC1 35;
BA_ "E2EProfile" SG_ 1290 BMS_8_CRC1 "P01";
BA_ "E2EDataLength" SG_ 1290 BMS_8_CRC1 64;
BA_ "GenSigSendType" SG_ 1290 BMS_8_RollgCntr1 0;
BA_ "E2EDataId" SG_ 1290 BMS_8_RollgCntr1 35;
BA_ "E2EProfile" SG_ 1290 BMS_8_RollgCntr1 "P01";
BA_ "E2EDataLength" SG_ 1290 BMS_8_RollgCntr1 64;
BA_ "GenSigSendType" SG_ 1290 BMS_8_Resd1 0;
BA_ "E2EDataId" SG_ 1290 BMS_8_Resd1 35;
BA_ "E2EProfile" SG_ 1290 BMS_8_Resd1 "P01";
BA_ "E2EDataLength" SG_ 1290 BMS_8_Resd1 64;
BA_ "GRC_Sig_ASIL" SG_ 1290 BMS_HvBattCellOverU 4;
BA_ "GenSigSendType" SG_ 1290 BMS_HvBattCellOverU 0;
BA_ "E2EDataId" SG_ 1290 BMS_HvBattCellOverU 35;
BA_ "E2EProfile" SG_ 1290 BMS_HvBattCellOverU "P01";
BA_ "E2EDataLength" SG_ 1290 BMS_HvBattCellOverU 64;
BA_ "GRC_Sig_ASIL" SG_ 1290 BMS_HvBattCellUnderU 4;
BA_ "GenSigSendType" SG_ 1290 BMS_HvBattCellUnderU 0;
BA_ "E2EDataId" SG_ 1290 BMS_HvBattCellUnderU 35;
BA_ "E2EProfile" SG_ 1290 BMS_HvBattCellUnderU "P01";
BA_ "E2EDataLength" SG_ 1290 BMS_HvBattCellUnderU 64;
BA_ "GRC_Sig_ASIL" SG_ 1290 BMS_HvBattUnderU 4;
BA_ "GenSigSendType" SG_ 1290 BMS_HvBattUnderU 0;
BA_ "E2EDataId" SG_ 1290 BMS_HvBattUnderU 35;
BA_ "E2EProfile" SG_ 1290 BMS_HvBattUnderU "P01";
BA_ "E2EDataLength" SG_ 1290 BMS_HvBattUnderU 64;
BA_ "GRC_Sig_ASIL" SG_ 1290 BMS_HvBattDischargeOverCurrent 4;
BA_ "GenSigSendType" SG_ 1290 BMS_HvBattDischargeOverCurrent 0;
BA_ "E2EDataId" SG_ 1290 BMS_HvBattDischargeOverCurrent 35;
BA_ "E2EProfile" SG_ 1290 BMS_HvBattDischargeOverCurrent "P01";
BA_ "E2EDataLength" SG_ 1290 BMS_HvBattDischargeOverCurrent 64;
BA_ "GRC_Sig_ASIL" SG_ 1290 BMS_HvBattChargeOverCurrent 4;
BA_ "GenSigSendType" SG_ 1290 BMS_HvBattChargeOverCurrent 0;
BA_ "E2EDataId" SG_ 1290 BMS_HvBattChargeOverCurrent 35;
BA_ "E2EProfile" SG_ 1290 BMS_HvBattChargeOverCurrent "P01";
BA_ "E2EDataLength" SG_ 1290 BMS_HvBattChargeOverCurrent 64;
BA_ "GRC_Sig_ASIL" SG_ 1290 BMS_HvBattOverU 4;
BA_ "GenSigSendType" SG_ 1290 BMS_HvBattOverU 0;
BA_ "E2EDataId" SG_ 1290 BMS_HvBattOverU 35;
BA_ "E2EProfile" SG_ 1290 BMS_HvBattOverU "P01";
BA_ "E2EDataLength" SG_ 1290 BMS_HvBattOverU 64;
BA_ "GenSigSendType" SG_ 1290 BMS_HvBattMismatching 0;
BA_ "E2EDataId" SG_ 1290 BMS_HvBattMismatching 35;
BA_ "E2EProfile" SG_ 1290 BMS_HvBattMismatching "P01";
BA_ "E2EDataLength" SG_ 1290 BMS_HvBattMismatching 64;
BA_ "GenSigSendType" SG_ 1290 BMS_HvBattSocJump 0;
BA_ "E2EDataId" SG_ 1290 BMS_HvBattSocJump 35;
BA_ "E2EProfile" SG_ 1290 BMS_HvBattSocJump "P01";
BA_ "E2EDataLength" SG_ 1290 BMS_HvBattSocJump 64;
BA_ "GenSigSendType" SG_ 1290 BMS_HvBattCellUUnif 0;
BA_ "E2EDataId" SG_ 1290 BMS_HvBattCellUUnif 35;
BA_ "E2EProfile" SG_ 1290 BMS_HvBattCellUUnif "P01";
BA_ "E2EDataLength" SG_ 1290 BMS_HvBattCellUUnif 64;
BA_ "GenSigSendType" SG_ 1290 BMS_HvBattLowSoc 0;
BA_ "E2EDataId" SG_ 1290 BMS_HvBattLowSoc 35;
BA_ "E2EProfile" SG_ 1290 BMS_HvBattLowSoc "P01";
BA_ "E2EDataLength" SG_ 1290 BMS_HvBattLowSoc 64;
BA_ "GenSigSendType" SG_ 1290 BMS_HvBattOverSoc 0;
BA_ "E2EDataId" SG_ 1290 BMS_HvBattOverSoc 35;
BA_ "E2EProfile" SG_ 1290 BMS_HvBattOverSoc "P01";
BA_ "E2EDataLength" SG_ 1290 BMS_HvBattOverSoc 64;
BA_ "GenSigSendType" SG_ 1290 BMS_HvBattTempUniformity 0;
BA_ "E2EDataId" SG_ 1290 BMS_HvBattTempUniformity 35;
BA_ "E2EProfile" SG_ 1290 BMS_HvBattTempUniformity "P01";
BA_ "E2EDataLength" SG_ 1290 BMS_HvBattTempUniformity 64;
BA_ "GenSigSendType" SG_ 1290 BMS_BattInterCANErr 0;
BA_ "E2EDataId" SG_ 1290 BMS_BattInterCANErr 35;
BA_ "E2EProfile" SG_ 1290 BMS_BattInterCANErr "P01";
BA_ "E2EDataLength" SG_ 1290 BMS_BattInterCANErr 64;
BA_ "GRC_Sig_ASIL" SG_ 1290 BMS_HvBattOverCharging 4;
BA_ "GenSigSendType" SG_ 1290 BMS_HvBattOverCharging 0;
BA_ "E2EDataId" SG_ 1290 BMS_HvBattOverCharging 35;
BA_ "E2EProfile" SG_ 1290 BMS_HvBattOverCharging "P01";
BA_ "E2EDataLength" SG_ 1290 BMS_HvBattOverCharging 64;
BA_ "GRC_Sig_ASIL" SG_ 1290 BMS_HvBattOverTemperature 4;
BA_ "GenSigSendType" SG_ 1290 BMS_HvBattOverTemperature 0;
BA_ "E2EDataId" SG_ 1290 BMS_HvBattOverTemperature 35;
BA_ "E2EProfile" SG_ 1290 BMS_HvBattOverTemperature "P01";
BA_ "E2EDataLength" SG_ 1290 BMS_HvBattOverTemperature 64;
BA_ "GenSigSendType" SG_ 1163 FMCU_SysTempOvrInd 0;
BA_ "GenSigSendType" SG_ 1316 LHFTireTemperature 0;
BA_ "GenSigInvalidValue" SG_ 1316 LHFTireTemperature 255;
BA_ "GenSigSendType" SG_ 1316 RHFTireTemperature 0;
BA_ "GenSigInvalidValue" SG_ 1316 RHFTireTemperature 255;
BA_ "GenSigSendType" SG_ 1316 LHRTireTemperature 0;
BA_ "GenSigInvalidValue" SG_ 1316 LHRTireTemperature 255;
BA_ "GenSigSendType" SG_ 1316 LHFTirePressure 0;
BA_ "GenSigInvalidValue" SG_ 1316 LHFTirePressure 255;
BA_ "GenSigSendType" SG_ 1316 RHFTirePressure 0;
BA_ "GenSigInvalidValue" SG_ 1316 RHFTirePressure 255;
BA_ "GenSigSendType" SG_ 1316 LHRTirePressure 0;
BA_ "GenSigInvalidValue" SG_ 1316 LHRTirePressure 255;
BA_ "GenSigSendType" SG_ 1316 RHRTirePressure 0;
BA_ "GenSigInvalidValue" SG_ 1316 RHRTirePressure 255;
BA_ "GenSigSendType" SG_ 1316 RHRTireTemperature 0;
BA_ "GenSigInvalidValue" SG_ 1316 RHRTireTemperature 255;
BA_ "GenSigSendType" SG_ 1324 TirePositionWarning_LHFTire 0;
BA_ "GenSigSendType" SG_ 1324 TirePositionWarning_RHFTire 0;
BA_ "GenSigSendType" SG_ 1324 TirePositionWarning_LHRTire 0;
BA_ "GenSigSendType" SG_ 1324 TirePositionWarning_RHRTire 0;
BA_ "GRC_Sig_ASIL" SG_ 1324 TirePressureWarningLampSts 3;
BA_ "GenSigSendType" SG_ 1324 TirePressureWarningLampSts 0;
BA_ "GRC_Sig_ASIL" SG_ 1324 TirePressureSystemFailSts 3;
BA_ "GenSigSendType" SG_ 1324 TirePressureSystemFailSts 0;
BA_ "GenSigSendType" SG_ 991 TMS_MotorLoopErrorLevel 0;
BA_ "GenSigSendType" SG_ 991 TMS_BatteryLoopErrorLevel 0;
BA_ "GenSigSendType" SG_ 1188 FrontDeforestDisplaySts 0;
BA_ "GenSigSendType" SG_ 1188 TMS_DisplayActive 0;
BA_ "GenSigSendType" SG_ 1188 TMS_ZoneSelectionDisplaySts 0;
BA_ "GenSigSendType" SG_ 1188 TMS_AutoDisplaySts 0;
BA_ "GenSigSendType" SG_ 1188 TMS_FiltertchangeDisplaySts 0;
BA_ "GenSigSendType" SG_ 1188 TMS_AUTODefrostOnSts 0;
BA_ "GenSigSendType" SG_ 1188 TMS_AUTODefrostDisplaySts 0;
BA_ "GenSigSendType" SG_ 1188 TMS_RefInSufDispSts 0;
BA_ "GenSigSendType" SG_ 1188 TMS_CooltInSufDispSts 0;
BA_ "GenSigSendType" SG_ 1188 TMS_DLOnOffSts 0;
BA_ "GenSigSendType" SG_ 1188 TMS_DROnOffSts 0;
BA_ "GenSigSendType" SG_ 1188 TMS_PLOnOffSts 0;
BA_ "GenSigSendType" SG_ 1188 WorkingSts 0;
BA_ "GenSigSendType" SG_ 1188 TMS_PROnOffSts 0;
BA_ "GenSigSendType" SG_ 1188 TMS_DCOnOffSts 0;
BA_ "GenSigSendType" SG_ 1188 TMS_ACFastCool 0;
BA_ "GenSigSendType" SG_ 1188 TMS_ACFastHeat 0;
BA_ "GenSigSendType" SG_ 1188 TMS_LoveRemind 0;
BA_ "GenSigSendType" SG_ 1188 TMS_InteCleanCar 0;
BA_ "GenSigSendType" SG_ 1188 TMS_ACVentilationSts 0;
BA_ "GenSigSendType" SG_ 1188 TMS_AutoAirCleanSts 0;
BA_ "GenSigSendType" SG_ 1188 PM25Sts 0;
BA_ "GenSigSendType" SG_ 1188 TMS_ACModeCustomSts 0;
BA_ "GenSigSendType" SG_ 1188 TMS_ACRequestDisplaySts 0;
BA_ "GenSigSendType" SG_ 1188 TMS_AUTODefLevelSts 0;
BA_ "GenSigSendType" SG_ 1188 TMS_KeepWarm 0;
BA_ "GenSigSendType" SG_ 1188 TMS_DSwingSts 0;
BA_ "GenSigSendType" SG_ 1188 TMS_PSwingSts 0;
BA_ "GenSigSendType" SG_ 1188 TMS_TuisongDispSts 0;
BA_ "GenSigSendType" SG_ 1188 TMS_SetTemperature_L_C 0;
BA_ "GenSigInvalidValue" SG_ 1188 TMS_SetTemperature_L_C 31;
BA_ "GenSigStartValue" SG_ 1188 TMS_SetTemperature_L_C 31;
BA_ "GenSigSendType" SG_ 1188 TMS_SetTemperature_R_C 0;
BA_ "GenSigInvalidValue" SG_ 1188 TMS_SetTemperature_R_C 31;
BA_ "GenSigStartValue" SG_ 1188 TMS_SetTemperature_R_C 31;
BA_ "GenSigSendType" SG_ 1188 TMS_ModeAdjustDisplaySts 0;
BA_ "GenSigStartValue" SG_ 1188 TMS_ModeAdjustDisplaySts 5;
BA_ "GenSigSendType" SG_ 1188 TMS_CirculationModeDisplaySts 0;
BA_ "GenSigStartValue" SG_ 1188 TMS_CirculationModeDisplaySts 1;
BA_ "GenSigSendType" SG_ 1188 TMS_IncarTemp 0;
BA_ "GenSigStartValue" SG_ 1188 TMS_IncarTemp 254;
BA_ "GenSigSendType" SG_ 1188 TMS_FliterLife 0;
BA_ "GenSigSendType" SG_ 1188 TMS_DLSwingUpDwnWPosn 0;
BA_ "GenSigInvalidValue" SG_ 1188 TMS_DLSwingUpDwnWPosn 127;
BA_ "GenSigSendType" SG_ 1188 TMS_DLSwingLeRiWPosn 0;
BA_ "GenSigInvalidValue" SG_ 1188 TMS_DLSwingLeRiWPosn 127;
BA_ "GenSigSendType" SG_ 1188 TMS_DRSwingUpDwnWPosn 0;
BA_ "GenSigInvalidValue" SG_ 1188 TMS_DRSwingUpDwnWPosn 127;
BA_ "GenSigSendType" SG_ 1188 TMS_DRSwingLeRiWPosn 0;
BA_ "GenSigInvalidValue" SG_ 1188 TMS_DRSwingLeRiWPosn 127;
BA_ "GenSigSendType" SG_ 1188 TMS_PLSwingUpDwnWPosn 0;
BA_ "GenSigInvalidValue" SG_ 1188 TMS_PLSwingUpDwnWPosn 127;
BA_ "GenSigSendType" SG_ 1188 TMS_PLSwingLeRiWPosn 0;
BA_ "GenSigInvalidValue" SG_ 1188 TMS_PLSwingLeRiWPosn 127;
BA_ "GenSigSendType" SG_ 1188 TMS_PRSwingUpDwnWPosn 0;
BA_ "GenSigInvalidValue" SG_ 1188 TMS_PRSwingUpDwnWPosn 127;
BA_ "GenSigSendType" SG_ 1188 TMS_PRSwingLeRiWPosn 0;
BA_ "GenSigInvalidValue" SG_ 1188 TMS_PRSwingLeRiWPosn 127;
BA_ "GenSigSendType" SG_ 1188 TMS_DCSwingLeRiWPosn 0;
BA_ "GenSigInvalidValue" SG_ 1188 TMS_DCSwingLeRiWPosn 127;
BA_ "GenSigSendType" SG_ 1188 AirSwingSts 0;
BA_ "GenSigSendType" SG_ 1188 TemperatureUnit 0;
BA_ "GenSigSendType" SG_ 1188 BlowAdvanceOnSts 0;
BA_ "GenSigSendType" SG_ 1188 BlowDelayOffSts 0;
BA_ "GenSigSendType" SG_ 1188 TMS_PM25_ExtSts 0;
BA_ "GenSigSendType" SG_ 1188 TMS_PM25_IncarSts 0;
BA_ "GenSigSendType" SG_ 1188 TMS_AQS_Sts 0;
BA_ "GenSigSendType" SG_ 1188 PM25overproofDisplaySts 0;
BA_ "GenSigSendType" SG_ 1188 AQSDisplaySts 0;
BA_ "GenSigSendType" SG_ 1188 PM25AutoRunSts 0;
BA_ "GenSigSendType" SG_ 1188 PM25AutoRunSetSts 0;
BA_ "GenSigSendType" SG_ 1188 FragranceWelcomeModeSts 0;
BA_ "GenSigSendType" SG_ 1188 FragranceDisplaysts 0;
BA_ "GenSigSendType" SG_ 1188 TMS_AQS_Level 0;
BA_ "GenSigSendType" SG_ 1188 ACRequestCommand 0;
BA_ "GenSigSendType" SG_ 1188 PM25_Outcar_Level 0;
BA_ "GenSigSendType" SG_ 1188 PM25_Incar_Level 0;
BA_ "GenSigSendType" SG_ 1188 SetTemperature_L_F 0;
BA_ "GenSigInvalidValue" SG_ 1188 SetTemperature_L_F 31;
BA_ "GenSigStartValue" SG_ 1188 SetTemperature_L_F 31;
BA_ "GenSigSendType" SG_ 1188 SetTemperature_R_F 0;
BA_ "GenSigInvalidValue" SG_ 1188 SetTemperature_R_F 31;
BA_ "GenSigStartValue" SG_ 1188 SetTemperature_R_F 31;
BA_ "GenSigSendType" SG_ 1188 TMS_PM25_incar 0;
BA_ "GenSigSendType" SG_ 1188 TMS_PM25_ext 0;
BA_ "GenSigSendType" SG_ 1188 TMS_KeepWarmMemoryFb 0;
BA_ "GenSigSendType" SG_ 612 Fusa_264_5 0;
BA_ "GenSigSendType" SG_ 612 Fusa_264_4 0;
BA_ "GenSigSendType" SG_ 612 Fusa_264_3 0;
BA_ "GenSigSendType" SG_ 612 Fusa_264_2 0;
BA_ "GenSigSendType" SG_ 612 Fusa_264_1 0;
BA_ "GenSigSendType" SG_ 612 EPB_R_1_CRC1 0;
BA_ "E2EDataId" SG_ 612 EPB_R_1_CRC1 43;
BA_ "E2EProfile" SG_ 612 EPB_R_1_CRC1 "P01";
BA_ "E2EDataLength" SG_ 612 EPB_R_1_CRC1 64;
BA_ "GenSigSendType" SG_ 612 EPB_R_1_RollgCntr1 0;
BA_ "E2EDataId" SG_ 612 EPB_R_1_RollgCntr1 43;
BA_ "E2EProfile" SG_ 612 EPB_R_1_RollgCntr1 "P01";
BA_ "E2EDataLength" SG_ 612 EPB_R_1_RollgCntr1 64;
BA_ "GenSigSendType" SG_ 612 EPB_1_FltLamp 0;
BA_ "E2EDataId" SG_ 612 EPB_1_FltLamp 43;
BA_ "E2EProfile" SG_ 612 EPB_1_FltLamp "P01";
BA_ "E2EDataLength" SG_ 612 EPB_1_FltLamp 64;
BA_ "GenSigSendType" SG_ 612 EPB_1_ParkLamp 0;
BA_ "E2EDataId" SG_ 612 EPB_1_ParkLamp 43;
BA_ "E2EProfile" SG_ 612 EPB_1_ParkLamp "P01";
BA_ "E2EDataLength" SG_ 612 EPB_1_ParkLamp 64;
BA_ "GenSigSendType" SG_ 612 EPB_1_ActrSt 0;
BA_ "E2EDataId" SG_ 612 EPB_1_ActrSt 43;
BA_ "E2EProfile" SG_ 612 EPB_1_ActrSt "P01";
BA_ "E2EDataLength" SG_ 612 EPB_1_ActrSt 64;
BA_ "GenSigSendType" SG_ 612 EPB_1_RWUSt 0;
BA_ "E2EDataId" SG_ 612 EPB_1_RWUSt 43;
BA_ "E2EProfile" SG_ 612 EPB_1_RWUSt "P01";
BA_ "E2EDataLength" SG_ 612 EPB_1_RWUSt 64;
BA_ "GenSigSendType" SG_ 612 EPB_1_TextDisp 0;
BA_ "E2EDataId" SG_ 612 EPB_1_TextDisp 43;
BA_ "E2EProfile" SG_ 612 EPB_1_TextDisp "P01";
BA_ "E2EDataLength" SG_ 612 EPB_1_TextDisp 64;
BA_ "GenSigSendType" SG_ 612 IPB_EPBErrorStatus 0;
BA_ "E2EDataId" SG_ 612 IPB_EPBErrorStatus 43;
BA_ "E2EProfile" SG_ 612 IPB_EPBErrorStatus "P01";
BA_ "E2EDataLength" SG_ 612 IPB_EPBErrorStatus 64;
BA_ "GenSigSendType" SG_ 1193 AVHWarningMessage 0;
BA_ "GenSigSendType" SG_ 1193 CDPActive 0;
BA_ "GenSigSendType" SG_ 1193 HDCFailSts 0;
BA_ "GenSigSendType" SG_ 1193 HDCCtrlSts 0;
BA_ "GenSigSendType" SG_ 1193 AVHSts 0;
BA_ "GenSigSendType" SG_ 1193 AVHFailSts 0;
BA_ "GenSigSendType" SG_ 1193 FWAWarningSts 0;
BA_ "GRC_Sig_ASIL" SG_ 1193 BrakeFluidSts 3;
BA_ "GenSigSendType" SG_ 1193 BrakeFluidSts 0;
BA_ "GRC_Sig_ASIL" SG_ 1193 BrakesystemFailSts 3;
BA_ "GenSigSendType" SG_ 1193 BrakesystemFailSts 0;
BA_ "GenSigSendType" SG_ 1197 CST_Status 0;
BA_ "GenSigStartValue" SG_ 1197 CST_Status 1;
BA_ "GenSigSendType" SG_ 1197 BrakepedalFeelSts 0;
BA_ "GenSigSendType" SG_ 1197 CST_SensitivitySts 0;
BA_ "GenSigStartValue" SG_ 1197 CST_SensitivitySts 2;
BA_ "GenSigSendType" SG_ 1200 EBS_SOC 0;
BA_ "GenSigInvalidValue" SG_ 1200 EBS_SOC 255;
BA_ "GenSigStartValue" SG_ 1200 EBS_SOC 255;
BA_ "GenSigSendType" SG_ 1061 Drv_Seat_RBolster_Sts 0;
BA_ "GenSigSendType" SG_ 1061 Drv_Seat_LBolster_Sts 0;
BA_ "GenSigSendType" SG_ 1061 Drv_Seat_ActvBolster_MdSts 0;
BA_ "GenSigSendType" SG_ 1061 DriverSeatMsgStr_LvlSts 0;
BA_ "GenSigSendType" SG_ 1061 DriverSeatMsg_ModeSts 0;
BA_ "GenSigSendType" SG_ 1065 LeftSeatMsgStr_LvlSts 0;
BA_ "GenSigSendType" SG_ 1065 LeftSeatMsg_ModeSts 0;
BA_ "GenSigSendType" SG_ 1069 PassSeatMsgStr_LvlSts 0;
BA_ "GenSigSendType" SG_ 1069 PassSeatMsg_ModeSts 0;
BA_ "GenSigSendType" SG_ 1087 RightSeatMsgStr_LvlSts 0;
BA_ "GenSigSendType" SG_ 1087 RightSeatMsg_ModeSts 0;
BA_ "GenSigSendType" SG_ 1189 SRF_OperateSts 0;
BA_ "GenSigSendType" SG_ 1189 SRF_PositionSts 0;
BA_ "GenSigSendType" SG_ 1189 SRF_OverHeatProtect 0;
BA_ "GenSigSendType" SG_ 1189 SRF_Sunshade_OperateSts 0;
BA_ "GenSigSendType" SG_ 1189 Sunshade_OverHeatProtect 0;
BA_ "GenSigSendType" SG_ 1192 SRF_Sunroof_ActualSts 0;
BA_ "GenSigSendType" SG_ 1192 SRF_Sunshade_ActualSts 0;
BA_ "GenSigSendType" SG_ 1192 SRF_Sunshade_PositionSts 0;
BA_ "GenSigSendType" SG_ 1143 OBC_InnerDischgReq 0;
BA_ "GRC_Sig_ASIL" SG_ 1143 OBC_CC_ConnectSts 2;
BA_ "GenSigSendType" SG_ 1143 OBC_CC_ConnectSts 0;
BA_ "GenSigSendType" SG_ 1143 CDU_MILSts 0;
BA_ "GenSigSendType" SG_ 1295 BMS_BattFaultLampSts 0;
BA_ "GenSigSendType" SG_ 1295 BMS_OverTemp_LightSts 0;
BA_ "GenSigSendType" SG_ 1295 BMS_RemainChg_Time 0;
BA_ "GRC_Sig_ASIL" SG_ 1295 BMS_ThermalRunawayDis 4;
BA_ "GenSigSendType" SG_ 1295 BMS_ThermalRunawayDis 0;
BA_ "GRC_Sig_ASIL" SG_ 1295 BMS_TBOXIsolationFault 3;
BA_ "GenSigSendType" SG_ 1295 BMS_TBOXIsolationFault 0;
BA_ "GenSigSendType" SG_ 1295 BMS_PreWarmDis 0;
BA_ "GenSigSendType" SG_ 1531 BMS_HvBattSoeActDisChaCyc 0;
BA_ "GenSigStartValue" SG_ 1531 BMS_HvBattSoeActDisChaCyc 65535;
BA_ "GenSigSendType" SG_ 1531 BMS_HvBattSoeActReChaCyc 0;
BA_ "GenSigStartValue" SG_ 1531 BMS_HvBattSoeActReChaCyc 65535;
BA_ "GenSigSendType" SG_ 1531 BMS_HvBattRatedEnergy 0;
BA_ "GenSigStartValue" SG_ 1531 BMS_HvBattRatedEnergy 16382;
BA_ "GenSigSendType" SG_ 1531 BMS_HvBattRatedU 0;
BA_ "GenSigStartValue" SG_ 1531 BMS_HvBattRatedU 16382;
BA_ "GenSigSendType" SG_ 1531 BMS_HvBattTypeCode 0;
BA_ "GenSigStartValue" SG_ 1531 BMS_HvBattTypeCode 255;
BA_ "GenSigSendType" SG_ 1531 BMS_HvBattManufcCode 0;
BA_ "GenSigSendType" SG_ 1531 BMS_HvBattTempSensorTotalNum 0;
BA_ "GenSigStartValue" SG_ 1531 BMS_HvBattTempSensorTotalNum 65535;
BA_ "GenSigSendType" SG_ 1531 BMS_HvBattTempSensorTempMaxNum 0;
BA_ "GenSigStartValue" SG_ 1531 BMS_HvBattTempSensorTempMaxNum 255;
BA_ "GenSigSendType" SG_ 1531 BMS_HvBattTempSensorTempMinNum 0;
BA_ "GenSigStartValue" SG_ 1531 BMS_HvBattTempSensorTempMinNum 255;
BA_ "GenSigSendType" SG_ 1531 BMS_HvBattTempMaxNum 0;
BA_ "GenSigStartValue" SG_ 1531 BMS_HvBattTempMaxNum 255;
BA_ "GenSigSendType" SG_ 1531 BMS_HvBattTempMinNum 0;
BA_ "GenSigStartValue" SG_ 1531 BMS_HvBattTempMinNum 255;
BA_ "GenSigSendType" SG_ 1531 BMS_BattCellTotalNum 0;
BA_ "GenSigStartValue" SG_ 1531 BMS_BattCellTotalNum 65535;
BA_ "GenSigSendType" SG_ 1531 BMS_HvBattVoltMaxNum 0;
BA_ "GenSigStartValue" SG_ 1531 BMS_HvBattVoltMaxNum 255;
BA_ "GenSigSendType" SG_ 1531 BMS_HvBattVoltMinNum 0;
BA_ "GenSigStartValue" SG_ 1531 BMS_HvBattVoltMinNum 255;
BA_ "GenSigSendType" SG_ 1531 BMS_ActualSOCMin 0;
BA_ "GenSigStartValue" SG_ 1531 BMS_ActualSOCMin 4095;
BA_ "GenSigSendType" SG_ 1531 BMS_ActualSOCMax 0;
BA_ "GenSigStartValue" SG_ 1531 BMS_ActualSOCMax 4095;
BA_ "GenSigSendType" SG_ 1224 BMS_HvBattCellVoltMax_Num 0;
BA_ "GenSigStartValue" SG_ 1224 BMS_HvBattCellVoltMax_Num 255;
BA_ "GRC_Sig_ASIL" SG_ 1224 BMS_HvBattCellVoltMax 4;
BA_ "GenSigSendType" SG_ 1224 BMS_HvBattCellVoltMax 0;
BA_ "GenSigStartValue" SG_ 1224 BMS_HvBattCellVoltMax 65534;
BA_ "GenSigSendType" SG_ 1224 BMS_HvBattCellVoltMin_Num 0;
BA_ "GenSigStartValue" SG_ 1224 BMS_HvBattCellVoltMin_Num 255;
BA_ "GRC_Sig_ASIL" SG_ 1224 BMS_HvBattCellVoltMin 4;
BA_ "GenSigSendType" SG_ 1224 BMS_HvBattCellVoltMin 0;
BA_ "GenSigStartValue" SG_ 1224 BMS_HvBattCellVoltMin 65534;
BA_ "GenSigSendType" SG_ 1224 BMS_Chg_Sts 0;
BA_ "GenSigSendType" SG_ 1235 EPS_2_Steer_ReturnRmd_Sts 0;
BA_ "GenSigSendType" SG_ 1235 EPS_2_Steer_ReturnRmd 0;
BA_ "GenSigSendType" SG_ 1235 EPS_2_MFS_ShakeSts 0;
BA_ "GenSigSendType" SG_ 1330 DWD_TextDisp 0;
BA_ "GenSigSendType" SG_ 1330 DWD_SoundIndcn 0;
BA_ "GenSigSendType" SG_ 1330 LSensorFailSts 0;
BA_ "GenSigSendType" SG_ 1330 RSensorFailSts 0;
BA_ "GenSigSendType" SG_ 1330 DWD_Distance 0;
BA_ "GenSigSendType" SG_ 1330 DWD_Switch 0;
VAL_ 1072 LHTurnlightSts 0 "Not Active" 1 "Active" ;
VAL_ 1072 RHTurnlightSts 0 "Not Active" 1 "Active" ;
VAL_ 1072 LHFdoorSts 0 "Close" 1 "Ajar" 2 "full_open" 3 "Reserved" ;
VAL_ 1072 LHFSeatBeltSW 0 "Not Active" 1 "Active" ;
VAL_ 1072 TrunkSts 0 "Close" 1 "Ajar" 2 "full_open" 3 "Reserved" ;
VAL_ 1072 RLWinPosn 127 "Invalid" ;
VAL_ 1072 SeatHeatLevelsFL 0 "OFF" 1 "Level1" 2 "Level2" 3 "Level3" ;
VAL_ 1072 SeatHeatLevelsRL 0 "OFF" 1 "Level1" 2 "Level2" 3 "Level3" ;
VAL_ 1072 SeatVentLevelsFL 0 "OFF" 1 "Level1" 2 "Level2" 3 "Level3" ;
VAL_ 1072 SeatVentLevelsRL 0 "OFF" 1 "Level1" 2 "Level2" 3 "Level3" ;
VAL_ 1072 FLWinPosn 127 "Invalid" ;
VAL_ 1072 FLZCU_FrontWiperMaintenanceSts 0 "Not Active" 1 "ON" 2 "OFF" ;
VAL_ 1072 FLZCU_RearWiperMaintenanceSts 0 "Not Active" 1 "ON" 2 "OFF" ;
VAL_ 1209 VCU_2_G_GasPedalPosInvalidData 0 "Valid" 1 "Invalid" ;
VAL_ 1209 VCU_2_G_PowerLimit 0 "LmpOFF" 1 "LmpON" ;
VAL_ 1209 VCU_2_G_BrakeLightReq 0 "LmpOFF" 1 "LmpON" ;
VAL_ 1209 VCU_2_G_VehicleSystemFailure 0 "Fail not present" 1 "Fail present" ;
VAL_ 1209 VCU_2_G_BootloadSts 0 "No Display" 1 "Display" ;
VAL_ 1209 VCU_2_G_DischgSts 0 "No Active" 1 "Active" ;
VAL_ 1209 VCU_2_G_BrakePedalStsValidData 0 "Valid" 1 "Not Valid" ;
VAL_ 1209 VCU_2_G_ExhibitionMod 0 "No Active" 1 "Active" ;
VAL_ 1209 VCU_2_G_BrakePedalSts 0 "Not applied" 1 "Applied" ;
VAL_ 1209 VCU_2_G_DCDCEnable 0 "Disable" 1 "Enable" ;
VAL_ 1209 VCU_2_G_HVReady 0 "LmpOFF" 1 "LmpON" ;
VAL_ 1209 Res_VCU_2_G_Brake_state 0 "Not braking" 1 "Braking" ;
VAL_ 1209 VCU_2_G_VCUEnergyflow 0 "NotHvReady" 1 "charging" 2 "RWD" 3 "recycle" 4 "external_discharge" 5 "battery_heat" 6 "AWD" 7 "FWD" 8 "HV_ON" 9 "Reserved" ;
VAL_ 1209 VCU_2_G_DrvGearShiftFailureIndcn 0 "No Command" 1 "rake pedal applied" 2 "Over Speed" 3 "Charge Gun Connect" 4 "EPB Can Not Lock" 5 "EPB Can Not Release" 6 "Invalid shift" 7 "Shift fault" ;
VAL_ 1209 VCU_2_G_GasPedalPosition 1023 "Invalid" ;
VAL_ 1229 VCU_CLTC_RangeAval 1023 "Invalid" ;
VAL_ 1229 VCU_DynamicRangeAval 1023 "Invalid" ;
VAL_ 1229 VCU_HighspdRangeAval 1023 "Invalid" ;
VAL_ 1229 VCU_WLTC_RangeAval 1023 "Invalid" ;
VAL_ 1263 VCU_TenECAver 4095 "Invalid" ;
VAL_ 1263 VCU_twenty_fiveECAver 4095 "Invalid" ;
VAL_ 1263 VCU_fiftyECAver 4095 "Invalid" ;
VAL_ 1034 HCU_EmPwr 255 "Invalid" ;
VAL_ 1034 HCU_PowerModeFed 0 "Not Active" 1 "EV" 2 "HEV" 3 "EV+" ;
VAL_ 1034 HCU_PowertrainFault 0 "No Fault" 1 "Fault" ;
VAL_ 1034 HCU_PowerModeChangeFail 0 "NOT FAIL" 1 "FAIL" ;
VAL_ 1034 HCU_ChargingSts 0 "No Charging" 1 "Stop Charging" 2 "Run Charging" 3 "Charge Complete" ;
VAL_ 1044 HCU_EnergyFlow 0 "OFF" 1 "Ready" 2 "2WD_EV" 3 "4WD_EV" 4 "2WD_ExtendRangeDisCharge" 5 "2WD_ExtendRangeCharge" 6 "4WD_ExtendRangeDisCharge" 7 "4WD_ExtendRangeCharge" 8 "2WD_Parallel" 9 "4WD_Parallel" 10 "Engine" 11 "Running_Generate" 12 "Parking_Generate" 13 "2WD_ReGenerateBrake" 14 "4WD_ReGenerateBrake" 15 "Charge" ;
VAL_ 1044 HCU_SetSOCFed 255 "Invalid" ;
VAL_ 1044 HCU_2_G_LowBatteryInfo 0 "Not Active" 1 "NoRequest" 2 "Request" 3 "Reserved" ;
VAL_ 1204 VCU_1_G_PTReady 0 "LmpOFF" 1 "LmpON" ;
VAL_ 1204 VCU_1_G_DriveMode 0 "Not Active" 1 "ECO" 2 "Normal" 3 "Sport" 4 "Snow" 5 "Off Road" 6 "Individual" 7 "Reserved" ;
VAL_ 1204 VCU_1_G_BookChrgSetResponse 0 "Default" 1 "Success" 2 "Cancelled" 3 "Fail" 4 "Reserved" ;
VAL_ 1204 VCU_1_G_HvBattKeepWarmActiveReq 0 "default" 1 "StartWarm" 2 "EndWarm" 3 "Reserved" ;
VAL_ 1204 VCU_1_G_PRNDGearAct 0 "Init" 1 "P" 2 "R" 3 "N" 4 "D" 5 "Reserved" 6 "Reserved" 7 "Reserved" ;
VAL_ 1057 VCU_TowingMode 0 "NotActive" 1 "Active" 2 "Reserved" 3 "Reserved" ;
VAL_ 1057 VCU_EngyConsuPer50Km 4095 "Invalid" ;
VAL_ 1057 VCU_BookChrgSetFailRes 0 "Default" 1 "OBC Fault" 2 "HvBatt Fault" 3 "DCDC Fault" 4 "Vehicle Fault" 5 "Reserved" 6 "Reserved" 7 "Reserved" ;
VAL_ 1057 VCU_BookChrgFailRes 0 "Default" 1 "OBC Fault" 2 "HvBatt Fault" 3 "DCDC Fault" 4 "Vehicle Fault" 5 "ChargeStationFault" 6 "BNCMfault" 7 "EVSEandBNCMConnectFault" 8 "Reserved" ;
VAL_ 1057 VCU_BookChrgStsFb 0 "Default" 1 "Charging" 2 "ChargeFinished" 3 "Reserved" ;
VAL_ 1057 HCU_EngineSelfMaintain 0 "Not Active" 1 "Active" 2 "Reserved" 3 "Reserved" ;
VAL_ 1043 EBS_U_BATT 16383 "Invalid" ;
VAL_ 1022 FLZCU_CarMode 0 "Normal Mode" 1 "Factory Mode" 2 "Transport Mode" 3 "Exhibition Mode" 4 "Reserved" 5 "Reserved" 6 "Reserved" 7 "Not active" ;
VAL_ 1022 FLZCU_SteerWhlposSts 0 "Not Active" 1 "Elongation regulation" 2 "Shortening in regulation" 3 "Angle elevation" 4 "Angle centering" ;
VAL_ 1022 FLZCU_MedStatusFb 0 "Not Active" 1 "ON" 2 "OFF" ;
VAL_ 1022 FLZCU_MedFailCause 0 "Not Active" 1 "Gear Not P" 2 "Vehicle Speed#0km/h" 3 "Hood Unlock" 4 "Trunk Unlock" 5 "FLDoor Unlock" 6 "FRDoor Unlock" 7 "RLDoor Unlock" 8 "RRDoor Unlock" 9 "Low Voltage Battery Voltage Low" 10 "High Voltage Battery Low" 11 "Brake Pedal Depressed" 12 "PowerMode Not Comfortable" ;
VAL_ 1022 FLZCU_MedAreaFb 0 "Not Active" 1 "Front Left" 2 "Front Right" 3 "Front Left and Right" 4 "2Row Left" 5 "2Row Right" 6 "2Row Left and 2Row Right" 7 "Front Left and 2Row Right" 8 "Front Right and 2Row Left" 9 "Front Left and 2Row Left" 10 "Front Right and 2Row Right" ;
VAL_ 1022 FLZCU_MedClosePrompt 0 "Not Active" 1 "Low Voltage Battery Low" 2 "High Voltage Battery Low" ;
VAL_ 1022 FLZCU_NapArea2Fb 0 "Not Active" 1 "2Row Left" 2 "2Row Right" 3 "2Row Left and Right" 4 "Front Left and 2Row Right" 5 "Front Right and 2Row Left" 6 "Front Left and 2Row Left" 7 "Front Right and 2Row Right" ;
VAL_ 1022 FLZCU_2LSeatLvltargetCmd 0 "Not active" ;
VAL_ 1022 FLZCU_2LSeatBackAgtargetCmd 0 "Not active" ;
VAL_ 1022 FLZCU_2LSeatLegSpprttargetCmd 0 "Not active" ;
VAL_ 1022 FLZCU_FLWinThermalStatus 0 "Normal" 1 "Thermal protection" ;
VAL_ 1022 FLZCU_RLWinThermalStatus 0 "Normal" 1 "Thermal protection" ;
VAL_ 1022 FLZCU_MonoAmbLigSts 0 "OFF" 1 "ON" ;
VAL_ 1022 FLZCU_LogoChargingSts 0 "Not Active" 1 "ON" 2 "OFF" 3 "Reserved" ;
VAL_ 1022 FLZCU_2RSeatLvltargetCmd 0 "Not active" ;
VAL_ 1022 FLZCU_2RSeatBackAgtargetCmd 0 "Not active" ;
VAL_ 1022 FLZCU_2RSeatLegSpprttargetCmd 0 "Not active" ;
VAL_ 1022 FLZCU_SeatVentLvlFL2 0 "Not Active" 1 "OFF" 2 "Level1" 3 "Level2" 4 "Level3" 5 "Level4" 6 "Level5" 7 "Level6" 8 "Level7" 9 "Level8" 10 "Level9" ;
VAL_ 1022 FLZCU_SeatVentLvlRL2 0 "Not Active" 1 "OFF" 2 "Level1" 3 "Level2" 4 "Level3" 5 "Level4" 6 "Level5" 7 "Level6" 8 "Level7" 9 "Level8" 10 "Level9" ;
VAL_ 1022 FLZCU_SeatHeatLvlFL2 0 "Not Active" 1 "OFF" 2 "Level1" 3 "Level2" 4 "Level3" 5 "Level4" 6 "Level5" 7 "Level6" 8 "Level7" 9 "Level8" 10 "Level9" ;
VAL_ 1022 FLZCU_SeatHeatLvlRL2 0 "Not Active" 1 "OFF" 2 "Level1" 3 "Level2" 4 "Level3" 5 "Level4" 6 "Level5" 7 "Level6" 8 "Level7" 9 "Level8" 10 "Level9" ;
VAL_ 1022 FLZCU_FLSitPosnSts 0 "Not Active" 1 "Location1" 2 "Location2" 3 "Location3" 4 "FaceID" ;
VAL_ 1022 FLZCU_SteerOverHeatWarn 0 "Not Active" 1 "Active" ;
VAL_ 1020 BMSH_MaxChgPwrPeak 4095 "Invalid" ;
VAL_ 1020 BMSH_MaxDchgPwrPeak 4095 "Invalid" ;
VAL_ 1020 FMCU_8_ISGF_SpdAct 65535 "Invalid" ;
VAL_ 1020 RMCU_1_Speed 65535 "Invalid" ;
VAL_ 1020 CSA_2_AllWarningInfo 0 "No error" 1 "First grade failure of gear shift mechanism" 2 "Second grade failure of gear shift mechanism" 3 "Third grade failure of gear shift mechanism(Reserved)" 4 "Please check the position of the gear shift" 5 "Reserved" 6 "Reserved" 7 "Reserved" ;
VAL_ 1020 RELC_RoofCampLampConfigDisp 0 "Not_Active" 1 "Active" ;
VAL_ 1020 RELC_TopLightConfigDisp 0 "Not_Active" 1 "Active" ;
VAL_ 1020 EELC_APillarLightConfigDisp 0 "Not_Active" 1 "Active" ;
VAL_ 1020 RELC_RoofCampLampStsL 0 "Not_Active" 1 "ON" 2 "OFF" 3 "Reserved" ;
VAL_ 1020 RELC_RoofCampLampStsR 0 "Not_Active" 1 "ON" 2 "OFF" 3 "Reserved" ;
VAL_ 1020 RELC_TopLightSts 0 "Not_Active" 1 "ON" 2 "OFF" 3 "Reserved" ;
VAL_ 1020 EELC_APillarYellowAmbientSts 0 "Not_Active" 1 "ON" 2 "OFF" 3 "Reserved" ;
VAL_ 1020 EELC_APillarWhiteAmbientSts 0 "Not_Active" 1 "ON" 2 "OFF" 3 "Reserved" ;
VAL_ 1020 EELC_APillarSpotLampSts 0 "Not_Active" 1 "ON" 2 "OFF" 3 "Reserved" ;
VAL_ 1020 RMCU_1_TCURErrLvlDis 0 "No Error" 1 "Err_Level1" 2 "Err_Level2" 3 "Err_Level3" 4 "Err_Level4" ;
VAL_ 1142 HCU_4_G_SumEgyCns 511 "Invalid" ;
VAL_ 1314 HCU_V2lDisChgBck 0 "Not_Active" 1 "V2L_ON" 2 "OFF" ;
VAL_ 1314 HCU_DisChgMemFed 0 "Not_Active" 1 "Remember" 2 "No_Remember" 3 "Reserved" ;
VAL_ 1314 HCU_V2VDisChgBck 0 "Not_Active" 1 "V2V_ON" 2 "OFF" ;
VAL_ 1314 HCU_V2l_IntlDisChgBck 0 "Not_Active" 1 "V2L_ON" 2 "OFF" ;
VAL_ 1314 HCU_FuelDetnOpDefeated 0 "No_Prompt" 1 "Prompt" ;
VAL_ 1314 HCU_FuelDetnModSwtFed 0 "Not_Active" 1 "ON" 2 "OFF" 3 "Invalid" ;
VAL_ 1314 HCU_FuelDetnStateFed 0 "Not_Active" 1 "HighIdle" 2 "LowIdle" 3 "Invalid" ;
VAL_ 1314 HCU_HVDownRepairModeFed 0 "Not_Active" 1 "ON" 2 "OFF" 3 "Invalid" ;
VAL_ 1314 HCU_TrailerMode 0 "Not_Active" 1 "ON" 2 "OFF" 3 "Invalid" ;
VAL_ 1314 HCU_DrivePowerDispSetFed 0 "Not_Active" 1 "PercentDisp" 2 "kWDisp" ;
VAL_ 1314 HCU_KeyDriveModememory 0 "Not_Active" 1 "Remember_" 2 "No_Remember" ;
VAL_ 1314 HCU_DRIFTModeSts 0 "Not_Active" 1 "Entry_Mode" 2 "Master_mode" 3 "Expert_mode" ;
VAL_ 1314 HCU_EXPERTEcoFed 0 "Not_Active" 1 "ON" 2 "OFF" 3 "Invalid" ;
VAL_ 1314 HCU_4LModeFed 0 "Not_Active" 1 "Active" ;
VAL_ 1314 HCU_EXPERTNormFed 0 "Not_Active" 1 "ON" 2 "OFF" 3 "Invalid" ;
VAL_ 1314 HCU_SingleRegnRmn 0 "Not_Active" 1 "Active" ;
VAL_ 1314 HCU_EXPERTSportFed 0 "Not_Active" 1 "ON" 2 "OFF" 3 "Invalid" ;
VAL_ 1314 HCU_CrossaxisFed 0 "Not_Active" 1 "Active" 2 "Stand_by" 3 "Failed" ;
VAL_ 1314 HCU_EXPERTRWDFed 0 "Not_Active" 1 "ON" 2 "OFF" 3 "Invalid" ;
VAL_ 1314 HCU_EXPERTAWDFed 0 "Not_Active" 1 "ON" 2 "OFF" 3 "Invalid" ;
VAL_ 1314 HCU_EXPERTAutoFed 0 "Not_Active" 1 "ON" 2 "OFF" 3 "Invalid" ;
VAL_ 1314 HCU_CLIMBFed 0 "Not_Active" 1 "ON" 2 "OFF" 3 "Invalid" ;
VAL_ 1314 HCU_StopChrgnFed 0 "Not_Active" 1 "ON" 2 "OFF" 3 "Invalid" ;
VAL_ 1314 HCU_StopChrgnModeFed 0 "Not_Active" 1 "Silence" 2 "Quick" ;
VAL_ 1314 HCU_ChrgnFctMemSt 0 "Not_Active" 1 "Remember" 2 "No_Remember" 3 "Reserved" ;
VAL_ 1314 HCU_LVPowSupSYSAbn_lit 0 "Not_Active" 1 "Active" ;
VAL_ 1314 HCU_IMMOReleaseSignal 0 "Not_Active" 1 "Active" ;
VAL_ 1314 HCU_PowerCut 0 "Not_Active" 1 "Active" ;
VAL_ 1314 HCU_ParkingChargeReminder 0 "Not_Active" 1 "Active" ;
VAL_ 1314 HCU_HEV_FunctionLimit 0 "Not_Active" 1 "Active" ;
VAL_ 1314 HCU_SetModeNotChange 0 "Not_Active" 1 "Active" ;
VAL_ 1314 HCU_UTURNSnowFed 0 "Not_Active" 1 "Active" ;
VAL_ 1314 HCU_DriveInhibit_GearP 0 "Not_Active" 1 "Active" ;
VAL_ 1314 HCU_AccleAbility_Limit 0 "Not_Active" 1 "Active" ;
VAL_ 1314 HCU_VehicleSpeedMax_Limit 0 "Not_Active" 1 "Active" ;
VAL_ 1314 HCU_EngineRunClmReq 0 "Not_Active" 1 "Active" ;
VAL_ 1314 HCU_DisconnectChagWarn 0 "Not_Active" 1 "Active" ;
VAL_ 1314 HCU_PowerModeChangeInhibit 0 "Not_Active" 1 "Active" ;
VAL_ 1314 HCU_DisChargeStopFault 0 "Init" 1 "LowSOC" 2 "LowFuel" ;
VAL_ 1314 HCU_DedicatedModeInhibit 0 "Not_Active" 1 "Active" ;
VAL_ 1314 HCU_LeaveVehicleWarning 0 "Not_Active" 1 "Active" ;
VAL_ 1314 HCU_TowingModeEna 0 "No Prompt" 1 "Prompt" ;
VAL_ 1314 HCU_PowerLevel 0 "Init" 1 "Level_1" 2 "Level_2" 3 "Level_3" 4 "Level_4" ;
VAL_ 1314 HCU_FrntEDLSts 0 "No Lock" 1 "UNLock" 2 "Lock" 3 "Warning" 4 "UnAvailable" 5 "Stuck Open" 6 "Stuck Close" 7 "Rear4LReq" 8 "RearReq" 9 "4LReq" ;
VAL_ 1314 HCU_RearEDLSts 0 "No Lock" 1 "UNLock" 2 "Lock" 3 "Warning" 4 "UnAvailable" 5 "Stuck_Open" 6 "Stuck_Close" 7 "Reserved" 8 "Reserved" 9 "Reserved" ;
VAL_ 1314 HCU_DriveMode_JT 0 "ECO" 1 "NORMAL" 2 "SPORT" 3 "SNOW" 4 "MUD" 5 "OffRoad" 6 "SAND" 7 "ROCK" 8 "EXPERT" 9 "X" 10 "WADE" 11 "UTURN" 12 "DRIFT" 13 "TOW" 14 "OffroadRace" ;
VAL_ 1314 HCU_CCOSwtFed 0 "Not_Active" 1 "Active" 2 "Stand_by" 3 "Failed" ;
VAL_ 1314 HCU_SinglePedalMemFed 0 "ON" 1 "OFF" ;
VAL_ 1314 HCU_SocManageFed 0 "Default" 1 "Pure_electricity_priority_mode" 2 "Fuel_priority_mode" 3 "SOC_hold_mode" 4 "SAVE" 5 "Charge" ;
VAL_ 1314 HCU_EgyRegenLevel 0 "Off" 1 "Low" 2 "High" 3 "middle" 4 "SinglePedl" ;
VAL_ 1314 HCU_DrvGearShiftFailureIndcn 0 "No_Command" 1 "brake_pedal_applied" 2 "Over_Speed" 3 "Charge_Gun_Connect" 4 "EPB_Can_Not_Lock" 5 "EPB_Can_Not_Release" 6 "Invalid_shift" 7 "Shift_fault" 8 "BrkPedl_to_start" 9 "OpenDoor_Shift" ;
VAL_ 1314 HCU_EXPERTEESPSet 0 "ALLON" 1 "TCS_VDC_OFF" 2 "ALLOFF" 3 "Reserved" ;
VAL_ 1314 HCU_UTURNSandFed 0 "OFF" 1 "ON" ;
VAL_ 1314 HCU_CruiseControlStatus 0 "Not_Active" 1 "Active" 2 "Stand_by" 3 "Fault" ;
VAL_ 1314 HCU_LTCDispFed 0 "Not Active" 1 "WLTC" 2 "CLTC" ;
VAL_ 1314 HCU_UTURNMudFed 0 "OFF" 1 "ON" ;
VAL_ 1314 HCU_UTURNGrassFed 0 "OFF" 1 "ON" ;
VAL_ 1314 HCU_EngyFlowToDisp 0 "Init" 1 "No_EngyFlow" 2 "Engine Idling" 3 "EV_FWD" 4 "EV_FWD_Regene" 5 "EV_RWD" 6 "EV_RWD_Regene" 7 "EV_4WD" 8 "EV_4WD_Regene" 9 "Series_FWD_BattChg" 10 "Series_FWD_BattDisChg" 11 "Series_FWD_BattNoCurr" 12 "Series_FWD_Regene" 13 "Series_RWD_BattChg" 14 "Series_RWD_BattDisChg" 15 "Series_RWD_BattNoCurr" 16 "Series_RWD_Regene" 17 "Series_4WD_BattChg" 18 "Series_4WD_BattDisChg" 19 "Series_4WD_BattNoCurr" 20 "Series_4WD_Regene" 21 "Parallel_FWD_BattChg" 22 "Parallel_FWD_BattDisChg" 23 "Parallel_FWD_BattNoCurr" 24 "Parallel_FWD_Regene" 25 "Parallel_4WD_BattChg" 26 "Parallel_4WD_BattDisChg" 27 "Parallel_4WD_BattNoCurr" 28 "Parallel_4WD_Regene" 29 "StopCharging_BatChg" 30 "StopCharging_BatDChg" 31 "StopCharging_BatNoCurr" ;
VAL_ 1314 HCU_DriveModeChangeFail 0 "NOT FAIL" 1 "FAIL" ;
VAL_ 1314 HCU_iCCO_Warn 0 "No_Warn" 1 "Please_Release_EPB" 2 "Please_slow_down" 3 "Please_Close_ Door and Belt" 4 "Please_Open in D" 5 "Please_Close_APA/ACC/CC" 6 "Please_Exit_HDC" 7 "Please_Switch to Snow/Mud/Sand/Rock" 8 "Please Depress the brake pedal" 9 "iCCO Exited" 10 "Reserved" 11 "Reserved" 12 "Reserved" 13 "Reserved" 14 "Reserved" 15 "Reserved" ;
VAL_ 1314 HCU_iTAS_Warn 0 "No_Warn" 1 "ELD Unable to lock" 2 "Please_Release_EPB" 3 "Please_slow_down" 4 "Disc temperature too high" 5 "vehicle is stuck" 6 "iTAS active max time" 7 "Please Open in D" ;
VAL_ 1314 HCU_DraggingModeRemind 0 "Not_Active" 1 "Enter" 2 "Working" 3 "Exit" 4 "Reserved" 5 "Reserved" 6 "Reserved" 7 "Reserved" ;
VAL_ 1314 HCU_25_EDLFed 0 "Not_Active" 1 "Forward" 2 "Backward" 3 "Reserved" ;
VAL_ 1314 HCU_25_Crossaxis_Warn 0 "No_Warn" 1 "Please_Release_EPB" 2 "Crossaxis Exited" 3 "Please_Open in D" 4 "Please_Close_ Door and Belt" 5 "Please Depress the brake pedal" 6 "Not Adjust Suspension Height" 7 "Reserved" ;
VAL_ 1314 HCU_iTAS_Active 0 "Not_Active" 1 "Standby" 2 "Active" 3 "Filed" ;
VAL_ 1314 HCU_ExterTempLowHint 0 "Init" 1 "Temp to HEV" 2 "Temp to EngRun" 3 "reserved" ;
VAL_ 1314 HCU_25_iTAS_SlopWarn 0 "No_Warn" 1 "Active" 2 "Reserved" 3 "Reserved" ;
VAL_ 1314 HCU_iTASSceneReq 0 "Not Active" 1 "Snow" 2 "Mud" 3 "Sand" 4 "Grass" 5 "Exit" ;
VAL_ 1314 HCU_DrivingModReq 0 "Normal" 1 "Snow" 2 "Mud" 3 "Sand" 4 "Rock" 5 "Wade" 6 "Expert" 7 "UTURN" 8 "DRIFT" 9 "OffroadRace" 10 "Reserved" 11 "Reserved" 12 "Reserved" 13 "Reserved" 14 "Reserved" 15 "Reserved" 16 "Reserved" 17 "Reserved" 18 "Reserved" 19 "Reserved" 20 "Reserved" 21 "Reserved" 22 "Reserved" 23 "Reserved" 24 "Reserved" 25 "Reserved" 26 "Reserved" 27 "Reserved" 28 "Reserved" 29 "Reserved" 30 "Reserved" 31 "Reserved" ;
VAL_ 1314 HCU_25_VehSpdOffroadRmn 0 "Not Acitve" 1 "Acitve" ;
VAL_ 1314 HCU_25_LaunchMod_Warn 0 "No_Warn" 1 "Active" 2 "Exit" 3 "Error" 4 "Reserved" 5 "Reserved" 6 "Reserved" 7 "Reserved" ;
VAL_ 1314 HCU_25_SetVehSpdOffroad 0 "No_Warn" 1 "Active" 2 "Reserved" 3 "Reserved" ;
VAL_ 1314 HCU_25_iDRIFT_Warn 0 "No_Warn" 1 "Please_Close_ Door and Belt" 2 "Please stop the vehicle" 3 "Error" 4 "Not Adjust Suspension Height" 5 "Reserved" 6 "Reserved" 7 "Reserved" ;
VAL_ 1314 HCU_25_TAB_Warn 0 "No Warn" 1 "Please open CCO" 2 "Please Unlock EDL" 3 "Prohibit locking EDL" 4 "Reserved" ;
VAL_ 1314 HCU_25_CCO_TextDisp 0 "No_Warn" 1 "Please_Release_EPB" 2 "Please_Slow_Down" 3 "Please_Close_ Door and Belt" 4 "Please_Open in D" 5 "Please_Close_APA/ACC/CC" 6 "Please_Exit_HDC" 7 "Please_Switch to Mud/Sand/Rock" 8 "Reduce_Speed_Below 12kph" 9 "Please_Close_CCO" ;
VAL_ 1075 VCC_2_ConfigurationMessageTrg 0 "not active" 1 "active" ;
VAL_ 1196 TDL_SwitchSts 0 "Not_Active" 1 "ON" 2 "OFF" 3 "reserved" ;
VAL_ 1196 TDL_ColourModeSts 0 "Not_Active" 1 "Monochrome" 2 "panchromatic" 3 "OFF" 4 "Reserved" 5 "Reserved" 6 "Reserved" 7 "Reserved" ;
VAL_ 1196 TDL_RhythmSwSts 0 "Not_Active" 1 "ON" 2 "OFF" 3 "reserved" ;
VAL_ 1196 TDL_ApiluminanceSts 0 "Not_Active" 1 "Level1" 2 "Level2" 3 "Level3" 4 "Level4" 5 "Level5" 6 "Level6" 7 "Level7" 8 "Level8" 9 "Reserved" 10 "Reserved" 11 "Reserved" 12 "Reserved" 13 "Reserved" 14 "Reserved" 15 "Reserved" ;
VAL_ 1196 TDL_VioceFunctionDone 0 "Not_Active" 1 "success" 2 "fail" 3 "reserved" ;
VAL_ 1196 TDL_FlowLightSwSts 0 "Not_Active" 1 "ON" 2 "OFF" 3 "reserved" ;
VAL_ 1196 TDL_FlowLightModeSts 0 "Not Active" 1 "mode1" 2 "mode2" 3 "mode3" 4 "mode4" 5 "mode5" 6 "mode6" 7 "Reserved" ;
VAL_ 1196 TDL_RhythmModeSts 0 "Not_Active" 1 "Mode1" 2 "Mode2" 3 "Mode3" 4 "Mode4" 5 "Mode5" 6 "Mode6" 7 "Reserved" ;
VAL_ 1177 FuelTankLidSts 0 "Close" 1 "Open" ;
VAL_ 1177 FuelTankLidLockFailureSts 0 "No failure" 1 "Failure" ;
VAL_ 1177 FuelTankLidSensorFailureSts 0 "No failure" 1 "Failure" ;
VAL_ 1109 CWC_ChargingSts 0 "No charging" 1 "Charging" 2 "Charging completed" 3 "Charging fault" ;
VAL_ 1109 CWC_workingSts 0 "CWC OFF" 1 "CWC ON" ;
VAL_ 1109 CWC_Phoneforgotten 0 "phone not forgotten" 1 "phone forgotten" ;
VAL_ 1109 CWC_Phoneforgotten_ON_OFF_Sts 0 "Function OFF" 1 "Function ON" ;
VAL_ 1109 CWC_1_ChrgFlt 0 "Not active" 1 "Low_Volf" 2 "High_Volf" 3 "High_Temp" 4 "Foreign_matter_detected" 5 "NFC_card_protect_L" 6 "Reserved" 7 "Reserved" ;
VAL_ 1109 CWC_ChargingSts_R 0 "No charging" 1 "Charging" 2 "Charging completed" 3 "Charging fault" ;
VAL_ 1109 CWC_workingSts_R 0 "CWC OFF" 1 "CWC ON" ;
VAL_ 1109 CWC_Phoneforgotten_R 0 "phone not forgotten" 1 "phone forgotten" ;
VAL_ 1109 CWC_Phoneforgotten_ON_OFF_Sts_R 0 "Function OFF" 1 "Function ON" ;
VAL_ 1109 CWC_1_ChrgFlt_R 0 "Not active" 1 "Low_Volf" 2 "High_Volf" 3 "High_Temp" 4 "Foreign_matter_detected_R" 5 "NFC_card_protect_R" 6 "Reserved" 7 "Reserved" ;
VAL_ 1231 TBOX_1_BookChrgActiveReq 0 "Not Active" 1 "StartCharge" 2 "EndCharge" 3 "Not used" ;
VAL_ 1231 TBOX_BookChrgSts 0 "Default" 1 "WaitingCharge" 2 "Charging" 3 "ChargeFinished" 4 "Reserved" ;
VAL_ 1231 TBOX_HvBattKeepWarmActiveReq 0 "Not active" 1 "StartWarm" 2 "EndWarm" 3 "Not Used" ;
VAL_ 1231 TBOX_BookChrgSetReq 0 "default" 1 "BookSet" 2 "CancellBook" 3 "Reserved" ;
VAL_ 1231 TBOX_StopChrgReq 0 "not active" 1 "active" ;
VAL_ 1231 TBOX_KeepWarmSet 0 "OFF" 1 "ON" ;
VAL_ 1231 TBOX_HV_Req 0 "not active" 1 "HVON" 2 "HVOFF" 3 "Reserved" ;
VAL_ 1063 TBOX_PetmodeSwitch 0 "Not Active" 1 "ON" 2 "OFF" 3 "Reserved" ;
VAL_ 1148 TBOX_GPSSwitchSts 0 "Not Active" 1 "On" 2 "Off" 3 "Not Used" ;
VAL_ 1148 TBOX_BkChrgCycleType 0 "default" 1 "Once" 2 "EveryDay" 3 "WorkDay" 4 "Reserved" 5 "Reserved" ;
VAL_ 1148 TBOX_BkChrgCycleMon 0 "Not active" 1 "Active" ;
VAL_ 1148 TBOX_BkChrgCycleTues 0 "Not active" 1 "Active" ;
VAL_ 1148 TBOX_BkChrgCycleWen 0 "Not active" 1 "Active" ;
VAL_ 1148 TBOX_BkChrgCycleThur 0 "Not active" 1 "Active" ;
VAL_ 1148 TBOX_BkChrgCycleFri 0 "Not active" 1 "Active" ;
VAL_ 1148 TBOX_BkChrgCycleSat 0 "Not active" 1 "Active" ;
VAL_ 1148 TBOX_BkChrgCycleSun 0 "Not active" 1 "Active" ;
VAL_ 1162 VehicleSpeedVSOSigValidData 0 "Valid" 1 "Not valid" ;
VAL_ 1162 ESPSwitchStatus 0 "On" 1 "Disable" ;
VAL_ 1162 ABSActive 0 "Not active" 1 "Active" ;
VAL_ 1162 ABSFailSts 0 "Fail not present" 1 "Fail present (lamp on)" ;
VAL_ 1162 EBDFailSts 0 "Fail not present" 1 "Fail present (lamp on)" ;
VAL_ 1162 TCSFailSts 0 "Fail not present" 1 "Fail present (lamp on)" ;
VAL_ 1162 VDCFailSts 0 "Fail not present" 1 "Fail present (lamp on)" ;
VAL_ 1162 TCSActive 0 "Not active" 1 "Active(blinking lamp)" ;
VAL_ 1162 VDCActive 0 "Not active" 1 "Active(blinking lamp)" ;
VAL_ 1162 BLRequestController 0 "Not illuminate" 1 "Illuminate" ;
VAL_ 1202 FuelRollingCounter 255 "Invalid" ;
VAL_ 1202 MILSts 0 "Off" 1 "Not used" 2 "Active" 3 "Not used" ;
VAL_ 1202 GPFWarning 0 "No GPF warning" 1 "GPF Full" 2 "GPF Overlimited" 3 "Reserved" ;
VAL_ 1202 EngineSpeed 2047 "Invalid" ;
VAL_ 1202 EngineSpeedValidData 0 "Valid" 1 "Not valid" ;
VAL_ 1202 EPCSts 0 "Off" 1 "Active" ;
VAL_ 1202 EMS_1_G_EngineSts 0 "Not Run" 1 "Run" ;
VAL_ 1202 EMS_EngineSts_Actual 0 "Not Run" 1 "Run" ;
VAL_ 1202 OilPressureWarningLamp 0 "Off" 1 "On" ;
VAL_ 683 RHFDoorSts 0 "Close" 1 "Ajar_" 2 "full_open" 3 "Reserved" ;
VAL_ 683 FRZCU_1_ParkLightSts 0 "Close" 1 "Open" ;
VAL_ 683 RHRDoorSts 0 "Close" 1 "Ajar_" 2 "full_open" 3 "Reserved" ;
VAL_ 33 ACU_3_LongitudinalAcceleration 65535 "Invalid" ;
VAL_ 33 ACU_3_LongitudinalAccelerationVD 0 "Valid" 1 "Reserved" 2 "Invalid" 3 "Initialize" ;
VAL_ 632 EngineCoolantTemperature 255 "Invalid" ;
VAL_ 1217 ASU_1_ASUSysFailrSts 0 "No Fail" 1 "LimpupMode" 2 "Fail" 3 "Reserved" ;
VAL_ 1217 ASU_1_SuspCurrentLvl 0 "Invalid" 1 "Very High level" 2 "Between Very high and high level" 3 "High level" 4 "Between high and normal level" 5 "Normal level" 6 "Between normal and low level" 7 "Low level" 8 "Between low and very low level" 9 "Very low level" 10 "easy Entry Enable level" 11 "easy Loading level" 12 "Reserved" 13 "Reserved" 14 "Reserved" 15 "Reserved" ;
VAL_ 1217 ASU_1_ECASSysSts 0 "InValid" 1 "AxisLifting" 2 "AxisLowering" 3 "AxisHolding" 4 "Function Shutdown" ;
VAL_ 1217 ASU_1_ECASErrSts 0 "no error" 1 "fault priority 1(minor)" 2 "fault priority 2(seriously)" 3 "fault priority 3(Very seriously)" ;
VAL_ 1217 ASU_1_SuspTarLvl 0 "No requirement" 1 "Very high level" 2 "high level" 3 "normal level" 4 "low level" 5 "very low level" 6 "easy Entry Enable level" 7 "easy Loading level" ;
VAL_ 1217 ASU_1_EasyEntryEna 0 "Not Enable" 1 "Enable" ;
VAL_ 1217 ASU_1_CDCErrSts 0 "no error" 1 "error" ;
VAL_ 1217 ASU_1_RearaxlewithTaildoorFb 0 "Not Enable" 1 "Enable" ;
VAL_ 1217 ASU_1_Overheat_warning 0 "No failure" 1 "Warnig for overheat" ;
VAL_ 1217 ASU_1_MaintainMod 0 "Initializing" 1 "ON,susp is in MaintainMod" 2 "OFF, susp isnot in MaintainMod" 3 "MaintainModexitReq" ;
VAL_ 1217 ASU_1_drivemodeheightlevFb 0 "Not Active" 1 "Very High" 2 "High" 3 "Standard" 4 "Low" 5 "Very Low" 6 "easy Entry Enable level" 7 "easy Loading level" 8 "Reserved" 9 "Reserved" 10 "Reserved" 11 "Reserved" 12 "Reserved" 13 "Reserved" 14 "Reserved" 15 "Reserved" ;
VAL_ 1217 ASU_1_HMIFailFb 0 "Work Normally" 1 "Non-P file" 2 "ASUSysFailrStsFail" 3 "Car running" 4 "Door is open" 5 "Slope is steep" 6 "Warnig for overheat" 7 "susp is in MaintainMod" 8 "susp is in Lifting Mod" 9 "CC connect" 10 "Low Battery" 11 "In Crash state" 12 "Airbag pressure too high" 13 "Unadjustable" 14 "AssistPassOut" 15 "Reserved" ;
VAL_ 1217 ASU_1_AssistPass 0 "Inactive" 1 "Active" ;
VAL_ 258 BMS_PackVoltage 65534 "Abnormal" 65535 "Invalid" ;
VAL_ 258 BMS_PackCurrent 65534 "Abnormal" 65535 "Invalid" ;
VAL_ 258 BMS_HvBattSts 0 "Init" 1 "standby" 2 "Precharge" 3 "HVOn" 4 "AC charge Mode" 5 "DC charge Mode" 6 "Boost charging mode" 7 "PreHeat Mode" 8 "keep warm" 9 "powerdown" 10 "emergencypowerdown" 11 "fault" 12 "afterrun" 13 "Keep warm complete Mode" 14 "PreHeat complete Mode" ;
VAL_ 258 BMS_SysSelfCheck 1 "self_checking" 2 "flaut" 3 "no fault" ;
VAL_ 258 BMS_HVBattThermRunaway 0 "normal" 1 "warning" 2 "invalid" 3 "Reserved" ;
VAL_ 258 BMS_ChargeVoltageReq 16382 "Error" 16383 "Init" ;
VAL_ 258 BMS_ChgCurrReq 16382 "Error" 16383 "Init" ;
VAL_ 258 BMS_InfraDcUActDc 16382 "Error" 16383 "Init" ;
VAL_ 258 BMS_InfraDcIActDc 16382 "Error" 16383 "Init" ;
VAL_ 258 BMS_HvBattDynChrgnILim 16382 "Error" 16383 "Init" ;
VAL_ 258 BMS_HvBattUChrgnLim 16382 "Error" 16383 "Init" ;
VAL_ 258 BMS_DChrgAPlusSt 0 "not active" 1 "active" ;
VAL_ 258 BMS_ChrgDcIAvl 16382 "Error" 16383 "Init" ;
VAL_ 258 BMS_ChrgDcCnctrDetd 0 "Init" 1 "Connector not detected" 2 "Connector detected" 3 "SNS/Fault" ;
VAL_ 258 BMS_DCChgMode 0 "Default" 1 "HandOver" 2 "ParaConfig" 3 "Chging" 4 "ChgEnd" 5 "ChgWaring" 6 "ChgFault" 7 "Reserved" ;
VAL_ 258 BMS_ChrgDcChrgnFltStopReas 0 "no fault" 1 "End by Infrastructure fault" 2 "BMS fault" 3 "CC2 fault" 4 "DC charge not allowd because low temperature" 5 "VCU fault" 6 "Boost fault" 7 "Other fault" ;
VAL_ 258 BMS_ChargeRequest_Mode 0 "No request" 1 "AC Charging request" 2 "Boost Charging request" 3 "DC Fast Charging request" 4 "Charge precharge request" 5 "Reserved" 6 "Reserved" 7 "Reserved" 8 "Reserved" 9 "Reserved" 10 "Reserved" 11 "Reserved" 12 "Reserved" 13 "Reserved" 14 "Reserved" 15 "init" ;
VAL_ 258 BMS_ChgRemTime 2046 "SNA/Fault" 2047 "Init" ;
VAL_ 258 BMS_1_StateOfChargeDis 254 "Abnormal" 255 "Invalid" ;
VAL_ 258 BMS_StateOfEnergy 65534 "Abnormal" 65535 "Invalid" ;
VAL_ 258 BMS_StateOfHealth 126 "Error" 127 "Init" ;
VAL_ 258 BMS_BlanceState 0 "Balance OFF" 1 "Balance ON" ;
VAL_ 258 BMS_IsolationFault 0 "no fault" 1 "Fault L1" 2 "Fault L2" 3 "Fault L3" ;
VAL_ 258 BMS_HVILFault_DC 0 "No fault" 1 "Fault" ;
VAL_ 258 BMS_HVILFault_FMCU 0 "No fault" 1 "Fault" ;
VAL_ 258 BMS_HVILFault_RMCU 0 "No fault" 1 "Fault" ;
VAL_ 258 BMS_SOCDis 16382 "Abnormal" 16383 "Invalid" ;
VAL_ 258 BMS_InfraDcIActDcMin 16382 "Error" 16383 "Init" ;
VAL_ 1290 BMS_HvBattCellOverU 0 "Normal" 1 "Fault Level 1" 2 "Fault Level 2" 3 "Fault Level 3" 4 "Fault Level 4" ;
VAL_ 1290 BMS_HvBattCellUnderU 0 "Normal" 1 "Fault Level 1" 2 "Fault Level 2" 3 "Fault Level 3" 4 "Fault Level 4" ;
VAL_ 1290 BMS_HvBattUnderU 0 "Normal" 1 "Fault Level 1" 2 "Fault Level 2" ;
VAL_ 1290 BMS_HvBattDischargeOverCurrent 0 "Normal" 1 "Fault Level 1" 2 "Fault Level 2" 3 "Fault Level 3" 4 "Fault Level 4" ;
VAL_ 1290 BMS_HvBattChargeOverCurrent 0 "Normal" 1 "Fault Level 1" 2 "Fault Level 2" 3 "Fault Level 3" 4 "Fault Level 4" ;
VAL_ 1290 BMS_HvBattOverU 0 "Normal" 1 "Fault Level 1" 2 "Fault Level 2" ;
VAL_ 1290 BMS_HvBattMismatching 0 "Normal State" 1 "Battery Pack Mismatch Failure" ;
VAL_ 1290 BMS_HvBattSocJump 0 "Normal," 1 "SOC jump warning" ;
VAL_ 1290 BMS_HvBattCellUUnif 0 "Normal" 1 "Failure" ;
VAL_ 1290 BMS_HvBattLowSoc 0 "Normal" 1 "Failure" ;
VAL_ 1290 BMS_HvBattOverSoc 0 "Normal" 1 "Failure" ;
VAL_ 1290 BMS_HvBattTempUniformity 0 "Normal" 1 "Failure" ;
VAL_ 1290 BMS_BattInterCANErr 0 "Normal" 1 "Failure" ;
VAL_ 1290 BMS_HvBattOverCharging 0 "Normal" 1 "Failure" ;
VAL_ 1290 BMS_HvBattOverTemperature 0 "Normal" 1 "Fault Level 1" 2 "Fault Level 2" 3 "Fault Level 3" 4 "Fault Level 4" ;
VAL_ 1163 FMCU_SysTempOvrInd 0 "Lamp off" 1 "Lamp on" ;
VAL_ 1324 TirePositionWarning_LHFTire 0 "Normal" 1 "Rapid_Air_Loss(Reserved)" 2 "Low_Pressure" 3 "Low Batter" 4 "High_Pressure(Reserved)" 5 "High_Temperature" 6 "Error_Mode" 7 "Not_used(Reserved)" ;
VAL_ 1324 TirePositionWarning_RHFTire 0 "Normal" 1 "Rapid_Air_Loss(Reserved)" 2 "Low_Pressure" 3 "Low Batter" 4 "High_Pressure(Reserved)" 5 "High_Temperature" 6 "Error_Mode" 7 "Not_used(Reserved)" ;
VAL_ 1324 TirePositionWarning_LHRTire 0 "Normal" 1 "Rapid_Air_Loss(Reserved)" 2 "Low_Pressure" 3 "Low Batter" 4 "High_Pressure(Reserved)" 5 "High_Temperature" 6 "Error_Mode" 7 "Not_used(Reserved)" ;
VAL_ 1324 TirePositionWarning_RHRTire 0 "Normal" 1 "Rapid_Air_Loss(Reserved)_" 2 "Low_Pressure" 3 "Low Batter" 4 "High_Pressure(Reserved)" 5 "High_Temperature" 6 "Error_Mode" 7 "Not_used(Reserved)" ;
VAL_ 1324 TirePressureWarningLampSts 0 "Lamp_Off" 1 "Lamp_Flashing(Reserved)" 2 "Lamp_On" 3 "Not_used" ;
VAL_ 1324 TirePressureSystemFailSts 0 "Fail_Not_Present" 1 "Fail_Present" ;
VAL_ 991 TMS_MotorLoopErrorLevel 0 "No Error" 1 "Derating function" 2 "Disabler" 3 "ShutDown" 4 "Reserved" 5 "Reserved" 6 "Reserved" 7 "Reserved" ;
VAL_ 991 TMS_BatteryLoopErrorLevel 0 "No Error（无差错）" 1 "Derating function（降额功能）" 2 "Disabler（解除）" 3 "ShutDown（关闭）" 4 "Reserved（保留）" 5 "Reserved（保留）" 6 "Reserved（保留）" 7 "Reserved（保留）" ;
VAL_ 1188 FrontDeforestDisplaySts 0 "Not_Active" 1 "Active" ;
VAL_ 1188 TMS_DisplayActive 0 "Off" 1 "On" ;
VAL_ 1188 TMS_ZoneSelectionDisplaySts 0 "Single_zone_mode" 1 "Dual_zone_mode" ;
VAL_ 1188 TMS_AutoDisplaySts 0 "Auto_Off" 1 "Auto_On" ;
VAL_ 1188 TMS_FiltertchangeDisplaySts 0 "Off" 1 "On" ;
VAL_ 1188 TMS_AUTODefrostOnSts 0 "Off" 1 "On" ;
VAL_ 1188 TMS_AUTODefrostDisplaySts 0 "Off" 1 "On" ;
VAL_ 1188 TMS_RefInSufDispSts 0 "Off" 1 "On" ;
VAL_ 1188 TMS_CooltInSufDispSts 0 "Off" 1 "On" ;
VAL_ 1188 TMS_DLOnOffSts 0 "Off" 1 "On" ;
VAL_ 1188 TMS_DROnOffSts 0 "Off" 1 "On" ;
VAL_ 1188 TMS_PLOnOffSts 0 "Off" 1 "On" ;
VAL_ 1188 WorkingSts 0 "Not_Active" 1 "Active" ;
VAL_ 1188 TMS_PROnOffSts 0 "Off" 1 "On" ;
VAL_ 1188 TMS_DCOnOffSts 0 "Off" 1 "On" ;
VAL_ 1188 TMS_ACFastCool 0 "Off" 1 "On" ;
VAL_ 1188 TMS_ACFastHeat 0 "Off" 1 "On" ;
VAL_ 1188 TMS_LoveRemind 0 "Off" 1 "On" ;
VAL_ 1188 TMS_InteCleanCar 0 "Off" 1 "On" ;
VAL_ 1188 TMS_ACVentilationSts 0 "Off" 1 "On" ;
VAL_ 1188 TMS_AutoAirCleanSts 0 "Off" 1 "On" ;
VAL_ 1188 PM25Sts 0 "Not_Active" 1 "Active" ;
VAL_ 1188 TMS_ACModeCustomSts 0 "Not_active" 1 "ECO" 2 "Comfortable" 3 "Strong________________________________________________________" ;
VAL_ 1188 TMS_ACRequestDisplaySts 0 "Off" 1 "On" ;
VAL_ 1188 TMS_AUTODefLevelSts 0 "Not_Active" 1 "OFF" 2 "Low" 3 "Medium" 4 "High" ;
VAL_ 1188 TMS_KeepWarm 0 "Not_active" 1 "Open_AC_" 2 "Open_NotAC" 3 "Closed" ;
VAL_ 1188 TMS_DSwingSts 0 "Not_active" 1 "AllZone_Swing" 2 "Single_Swing" 3 "Mirro_Swing" 4 "Free_Swing" ;
VAL_ 1188 TMS_PSwingSts 0 "Not_active" 1 "AllZone_Swing" 2 "Single_Swing" 3 "Mirro_Swing" 4 "Free_Swing" ;
VAL_ 1188 TMS_TuisongDispSts 0 "Not_Request" 1 "Avoid_fog" 2 "Enhanced_Def" 3 "Enhanced_Purification" 4 "Swing_Operation" ;
VAL_ 1188 TMS_ModeAdjustDisplaySts 0 "BlowFace" 1 "BlowFaceAndBlowFoot" 2 "BlowFoot" 3 "BlowFootAndBlowWindow" 4 "BlowWindow" 5 "Not Active" 6 "BlowFaceAndBlowWindow" 7 "BlowFaceAndBlowFootAndBlowWindow" 8 "Auto" ;
VAL_ 1188 TMS_CirculationModeDisplaySts 0 "Recirculation_mode" 1 "Air_circulation_mode" 2 "Two-Layer_Flow_Mode" 3 "Reserved" ;
VAL_ 1188 AirSwingSts 0 "Off" 1 "On" ;
VAL_ 1188 TemperatureUnit 0 "Centigrade(℃)" 1 "Fahrenheit(℉)" ;
VAL_ 1188 BlowAdvanceOnSts 0 "AdvanceOn" 1 "Not_AdvanceOn" ;
VAL_ 1188 BlowDelayOffSts 0 "DelayOff" 1 "Not_DelayOff" ;
VAL_ 1188 TMS_PM25_ExtSts 0 "Normal" 1 "failure" ;
VAL_ 1188 TMS_PM25_IncarSts 0 "Normal" 1 "failure" ;
VAL_ 1188 TMS_AQS_Sts 0 "Normal" 1 "failure" ;
VAL_ 1188 PM25overproofDisplaySts 0 "Off" 1 "On" ;
VAL_ 1188 AQSDisplaySts 0 "Off" 1 "On" ;
VAL_ 1188 PM25AutoRunSts 0 "Off" 1 "On" ;
VAL_ 1188 PM25AutoRunSetSts 0 "Off" 1 "On" ;
VAL_ 1188 FragranceWelcomeModeSts 0 "Off" 1 "On" ;
VAL_ 1188 FragranceDisplaysts 0 "Off" 1 "On" ;
VAL_ 1188 TMS_AQS_Level 0 "Good" 1 "Light_pollution" 2 "Moderate_pollution" 3 "High_levels_of_pollution" ;
VAL_ 1188 ACRequestCommand 0 "Not_Active" 1 "Cooling" 2 "Heating" 3 "Venting" 4 "Auto" ;
VAL_ 1188 PM25_Outcar_Level 0 "Good" 1 "Favorable_pollution" 2 "Light_pollution" 3 "Moderate_pollution" 4 "High_levels_of_pollution" 5 "Serious_pollution" 6 "Reserved" 7 "Reserved" ;
VAL_ 1188 PM25_Incar_Level 0 "Good" 1 "Favorable_pollution" 2 "Light_pollution" 3 "Moderate_pollution" 4 "High_levels_of_pollution" 5 "Serious_pollution" 6 "Reserved" 7 "Reserved" ;
VAL_ 1188 TMS_KeepWarmMemoryFb 0 "Not_Active" 1 "Memory_On" 2 "Memory_Off" 3 "Not_Used" ;
VAL_ 612 EPB_1_FltLamp 0 "Lamp OFF" 1 "Lamp ON" 2 "Lamp Flash" 3 "Reserved" ;
VAL_ 612 EPB_1_ParkLamp 0 "Lamp OFF" 1 "Lamp ON" 2 "Lamp Flash" 3 "Reserved" ;
VAL_ 612 EPB_1_ActrSt 0 "Unknow" 1 "Applied" 2 "Released" 3 "Applying" 4 "Releasing" 5 "CompletelyReleased" 6 "Half Applied" 7 "Reserved" ;
VAL_ 612 EPB_1_RWUSt 0 "No active" 1 "active" ;
VAL_ 612 EPB_1_TextDisp 0 "NO text message" 1 "Gradient too high" 2 "Clampforce not enough" 3 "fasten seatbelt" 4 "Press brake pedal" 5 "No_Release_Tip_for_Shift" 6 "Reserved" 7 "Reserved" 8 "Reserved" 9 "Reserved" 10 "Reserved" 11 "Reserved" 12 "Reserved" 13 "Reserved" 14 "Reserved" 15 "Reserved" ;
VAL_ 612 IPB_EPBErrorStatus 0 "No_Error" 1 "Error" ;
VAL_ 1193 AVHWarningMessage 0 "Off" 1 "Fasten DriverSeatBelt and Close the LHF door" ;
VAL_ 1193 CDPActive 0 "Not active" 1 "Active" ;
VAL_ 1193 HDCFailSts 0 "Fail not present" 1 "Fail present (lamp on)" ;
VAL_ 1193 HDCCtrlSts 0 "OFF" 1 "not active braking(lamp on)" 2 "On active braking(flash)" 3 "Not used" ;
VAL_ 1193 AVHSts 0 "Off" 1 "Standby" 2 "Active" 3 "Not Used" ;
VAL_ 1193 AVHFailSts 0 "Fail not present" 1 "Fail present (lamp on)" ;
VAL_ 1193 FWAWarningSts 0 "No failure" 1 "BrakeSys High Temperature Leve1" 2 "BrakeSys High Temperature Leve2" 3 "Not used" ;
VAL_ 1193 BrakeFluidSts 0 "Normal" 1 "Empty" 2 "Electric_error" 3 "Not used" ;
VAL_ 1193 BrakesystemFailSts 0 "Fail not present" 1 "Fail present" ;
VAL_ 1197 CST_Status 0 "CST is disabled" 1 "CST is Standby" 2 "CST is Active" 3 "CST is Failure" ;
VAL_ 1197 BrakepedalFeelSts 0 "Comfort" 1 "Sport" 2 "Offroad" 3 "Reserved" ;
VAL_ 1197 CST_SensitivitySts 0 "Not Active" 1 "Comfort Low" 2 "Comfort Middle" 3 "Comfort High" ;
VAL_ 1061 DriverSeatMsgStr_LvlSts 0 "OFF/Intial" 1 "Low" 2 "Middle" 3 "High" ;
VAL_ 1061 DriverSeatMsg_ModeSts 0 "NotActive" 1 "PulseMode" 2 "WaveMode" 3 "CatPawMode" 4 "SigleRowMode" 5 "CrossMode" 6 "ButterflyMode" 7 "WaistMode" 8 "SnakeMode" 9 "Special 1" 10 "Special 2" 11 "Special 3" 12 "Special 4" ;
VAL_ 1065 LeftSeatMsgStr_LvlSts 0 "OFF/Intial" 1 "Low" 2 "Middle" 3 "High" 4 "Reserved" 5 "Reserved" 6 "Reserved" 7 "Reserved" ;
VAL_ 1065 LeftSeatMsg_ModeSts 0 "NotActive" 1 "PulseMode" 2 "WaveMode" 3 "CatPawMode" 4 "SigleRowMode" 5 "CrossMode" 6 "ButterflyMode" 7 "WaistMode" 8 "SnakeMode" 9 "Special 1" 10 "Special 2" 11 "Special 3" 12 "Special 4" ;
VAL_ 1069 PassSeatMsgStr_LvlSts 0 "OFF/Intial" 1 "Low" 2 "Middle" 3 "High" 4 "Reserved" 5 "Reserved" 6 "Reserved" 7 "Reserved" ;
VAL_ 1069 PassSeatMsg_ModeSts 0 "NotActive" 1 "PulseMode" 2 "WaveMode" 3 "CatPawMode" 4 "SigleRowMode" 5 "CrossMode" 6 "ButterflyMode" 7 "WaistMode" 8 "SnakeMode" 9 "Special 1" 10 "Special 2" 11 "Special 3" 12 "Special 4" ;
VAL_ 1087 RightSeatMsgStr_LvlSts 0 "OFF/Intial" 1 "Low" 2 "Middle" 3 "High" 4 "Reserved" 5 "Reserved" 6 "Reserved" 7 "Reserved" ;
VAL_ 1087 RightSeatMsg_ModeSts 0 "NotActive" 1 "PulseMode" 2 "WaveMode" 3 "CatPawMode" 4 "SigleRowMode" 5 "CrossMode" 6 "ButterflyMode" 7 "WaistMode" 8 "SnakeMode" 9 "Special 1" 10 "Special 2" 11 "Special 3" 12 "Special 4" ;
VAL_ 1189 SRF_OperateSts 0 "Not Active" 1 "Tilt" 2 "Close" 3 "Opening" 4 "Stop" 5 "Closing" 6 "Open" 7 "Comfort_open" ;
VAL_ 1189 SRF_PositionSts 0 "Not Active" 1 "0%" 2 "10%" 3 "20%" 4 "30%" 5 "40%" 6 "50%" 7 "60%" 8 "70%" 9 "80%" 10 "90%" 11 "100%" 12 "Tilt" ;
VAL_ 1189 SRF_OverHeatProtect 0 "No_Error_Inactive" 1 "Active" ;
VAL_ 1189 SRF_Sunshade_OperateSts 0 "Not Active" 1 "Close" 2 "Opening" 3 "Stop" 4 "Closing" 5 "Open" 6 "Half_Open" 7 "Reserved" ;
VAL_ 1189 Sunshade_OverHeatProtect 0 "No_Error_Inactive" 1 "Active" ;
VAL_ 1192 SRF_Sunroof_ActualSts 0 "Not Active" 1 "Open" 2 "Close" 3 "Tilt" 4 "Reserved" 5 "Reserved" 6 "Reserved" 7 "Error" ;
VAL_ 1192 SRF_Sunshade_ActualSts 0 "Not Active" 1 "Open" 2 "Close" 3 "Tilt" 4 "Reserved" 5 "Reserved" 6 "Reserved" 7 "Error" ;
VAL_ 1192 SRF_Sunshade_PositionSts 0 "Not Active" 1 "0%" 2 "10%" 3 "20%" 4 "30%" 5 "40%" 6 "50%" 7 "60%" 8 "70%" 9 "80%" 10 "90%" 11 "100%" 12 "Reserved" ;
VAL_ 1143 OBC_CC_ConnectSts 0 "Not connected" 1 "Charge Connected" 2 "V2V" 3 "V2L" 4 "Half Connection" 5 "Error" 6 "Reserved" 7 "Reserved" ;
VAL_ 1143 CDU_MILSts 0 "Not Active" 1 "Active" ;
VAL_ 1295 BMS_BattFaultLampSts 0 "Lamp OFF" 1 "Lamp ON" ;
VAL_ 1295 BMS_OverTemp_LightSts 0 "Lamp OFF" 1 "Lamp ON" ;
VAL_ 1295 BMS_RemainChg_Time 2047 "Invalid" ;
VAL_ 1295 BMS_ThermalRunawayDis 0 "no thermalrunaway" 1 "thermalrunaway occur" ;
VAL_ 1295 BMS_TBOXIsolationFault 0 "no fault" 1 "Fault L1" 2 "Fault L2" 3 "Fault L3" ;
VAL_ 1295 BMS_PreWarmDis 0 "none" 1 "preheat state" 2 "keepwarm state" ;
VAL_ 1531 BMS_HvBattSoeActDisChaCyc 65534 "Abnormal" 65535 "Invalid" ;
VAL_ 1531 BMS_HvBattSoeActReChaCyc 65534 "Abnormal" 65535 "Invalid" ;
VAL_ 1531 BMS_HvBattRatedEnergy 16382 "Abnormal" 16383 "Invalid" ;
VAL_ 1531 BMS_HvBattRatedU 16382 "Abnormal" 16383 "Invalid" ;
VAL_ 1531 BMS_HvBattTypeCode 0 "reserved" 1 "LFP" 2 "LMO" 3 "LCO" 4 "NCM" 5 "Polymer Lithium ion" 6 "Supercapacitors" 7 "LTO" 252 "Fuel Cell" 255 "other type" ;
VAL_ 1531 BMS_HvBattManufcCode -2147483648 "Abnormal" -2147483648 "Invalid" ;
VAL_ 1531 BMS_HvBattTempSensorTotalNum 65534 "Abnormal" 65535 "Invalid" ;
VAL_ 1531 BMS_HvBattTempSensorTempMaxNum 254 "Abnormal" 255 "Invalid" ;
VAL_ 1531 BMS_HvBattTempSensorTempMinNum 254 "Abnormal" 255 "Invalid" ;
VAL_ 1531 BMS_HvBattTempMaxNum 254 "Abnormal" 255 "Invalid" ;
VAL_ 1531 BMS_HvBattTempMinNum 254 "Abnormal" 255 "Invalid" ;
VAL_ 1531 BMS_BattCellTotalNum 65534 "Abnormal" 65535 "Invalid" ;
VAL_ 1531 BMS_HvBattVoltMaxNum 254 "Abnormal" 255 "Invalid" ;
VAL_ 1531 BMS_HvBattVoltMinNum 254 "Abnormal" 255 "Invalid" ;
VAL_ 1531 BMS_ActualSOCMin 4095 "Invalid" ;
VAL_ 1531 BMS_ActualSOCMax 4095 "Invalid" ;
VAL_ 1224 BMS_HvBattCellVoltMax_Num 254 "Abnormal" 255 "Invalid" ;
VAL_ 1224 BMS_HvBattCellVoltMax 65534 "Abnormal" 65535 "Invalid" ;
VAL_ 1224 BMS_HvBattCellVoltMin_Num 254 "Abnormal" 255 "Invalid" ;
VAL_ 1224 BMS_HvBattCellVoltMin 65534 "Abnormal" 65535 "Invalid" ;
VAL_ 1224 BMS_Chg_Sts 1 "Parking chagre" 2 "Driving charge" 3 "no charge" 4 "charge complete" 14 "Abnomal" 15 "Invalid" ;
VAL_ 1235 EPS_2_Steer_ReturnRmd_Sts 0 "No_Active" 1 "ON" 2 "OFF" 3 "Reserved" ;
VAL_ 1235 EPS_2_Steer_ReturnRmd 0 "No Tip" 1 "Tip return finish" 2 "Tip return left" 3 "Tip return right" ;
VAL_ 1235 EPS_2_MFS_ShakeSts 0 "No_Active" 1 "ON" 2 "OFF" 3 "reserved" ;
VAL_ 1330 DWD_TextDisp 0 "No Active" 1 "Speed exceed 10km/h" 2 "Speed exceed 5km/h" 3 "Controller pedal undeploy" 4 "Slope exceed 10°" 5 "Driving mode is snow、mud、sand" 6 "Keep low speed" 7 "Out rearview mirror undeploy" 8 "Doors are open" 9 "Trunk are open" 10 "System is fail" 11 "System is not available" 12 "Sys exit" ;
VAL_ 1330 DWD_SoundIndcn 0 "No warning" 1 "Long beep" 2 "3Hz" 3 "1.5Hz" ;
VAL_ 1330 LSensorFailSts 0 "Sensor normal" 1 "Sensor fault" ;
VAL_ 1330 RSensorFailSts 0 "Sensor normal" 1 "Sensor fault" ;
VAL_ 1330 DWD_Distance 0 "No object" 1 "Object in zone 1, 0~5cm" 2 "Object in zone 2, 6~10cm" 3 "Object in zone 3, 11~15cm" 4 "Object in zone 4, 16~20cm" 5 "Object in zone 5, 21~25cm" 6 "Object in zone 6, 26~30cm" 7 "Object in zone 7, 31~35cm" 8 "Object in zone 8, 36~40cm" 9 "Object in zone 9, 41~45cm" 10 "Object in zone 10, 46~50cm" 11 "Object in zone 11, 51~55cm" 12 "Object in zone 12, 56~60cm" 13 "Object in zone 13, 61~65cm" 14 "Object in zone 14, 66~70cm" 15 "Object in zone 15, 71~75cm" 16 "Object in zone 16, 76~80cm" 17 "Object in zone 17, 81~85cm" 18 "Object in zone 18, 86~90cm" 19 "Object in zone 19, 91~95cm" 20 "Object in zone 20, 96~100cm" 21 "Object in zone 21, 101~105cm" 22 "Object in zone 22, 105~110cm" 23 "Object in zone 23, 111~115cm" 24 "Object in zone 24, 116~120cm" 25 "Object in zone 25, 121~125cm" 26 "Object in zone 26, 126~130cm" 27 "Object in zone 27, 131~135cm" 28 "Object in zone 28, 136~140cm" 29 "Object in zone 29, 141~145cm" 30 "Object in zone 30, 146~150cm" ;
VAL_ 1330 DWD_Switch 0 "Not Active" 1 "ON" 2 "OFF" 3 "Reserved" ;
SIG_GROUP_ 1209 VCU_2_G_0x4B9_E2E_P01_1 1 : VCU_2_G_CRC VCU_2_G_RollgCntr VCU_2_G_Resd VCU_2_G_GasPedalPosInvalidData VCU_2_G_PowerLimit VCU_2_G_BrakeLightReq VCU_2_G_VehicleSystemFailure VCU_2_G_BootloadSts VCU_2_G_DischgSts VCU_2_G_BrakePedalStsValidData VCU_2_G_ExhibitionMod VCU_2_G_BrakePedalSts VCU_2_G_DCDCEnable VCU_2_G_HVReady Res_VCU_2_G_Brake_state VCU_2_G_VCUEnergyflow VCU_2_G_DrvGearShiftFailureIndcn VCU_2_G_GasPedalPosition;
SIG_GROUP_ 1204 VCU_1_G_0x4B4_E2E_P01_1 1 : Fusa_4B4_1 Fusa_4B4_2 Fusa_4B4_3 Fusa_4B4_4 Fusa_4B4_5 VCU_1_G_CRC VCU_1_G_RollgCntr VCU_1_G_Pwr VCU_1_G_PTReady VCU_1_G_DriveMode VCU_1_G_BookChrgSetResponse VCU_1_G_HvBattKeepWarmActiveReq VCU_1_G_PRNDGearAct;
SIG_GROUP_ 1136 VCC_3_0x470_E2E_P01_1 1 : VCC_3_CRC VCC_3_RollgCntr VCC_3_Resd1 VCC_3_SN;
SIG_GROUP_ 1162 ONEBOX_1_G_0x48A_E2E_P01_1 1 : Fusa_48A_1 Fusa_48A_2 Fusa_48A_3 ONEBOX_1_G_CRC ONEBOX_1_G_RollgCntr VehicleSpeedVSOSig VehicleSpeedVSOSigValidData ESPSwitchStatus ABSActive ABSFailSts EBDFailSts TCSFailSts VDCFailSts TCSActive VDCActive BLRequestController;
SIG_GROUP_ 258 BMS_1_0x102_E2E_P01_1 1 : BMS_1_CRC1 BMS_1_RollgCntr1 BMS_1_Resd1 BMS_PackVoltage BMS_PackCurrent BMS_HvBattSts BMS_SysSelfCheck BMS_HVBattThermRunaway;
SIG_GROUP_ 258 BMS_1_0x102_E2E_P01_3 1 : BMS_1_CRC3 BMS_1_RollgCntr3 BMS_1_Resd3 BMS_InfraDcIActDc BMS_HvBattDynChrgnILim BMS_HvBattUChrgnLim;
SIG_GROUP_ 258 BMS_1_0x102_E2E_P01_4 1 : BMS_1_CRC4 BMS_1_RollgCntr4 BMS_1_Resd4 BMS_DChrgAPlusSt BMS_ChrgDcIAvl BMS_Insulation_R BMS_ChrgDcCnctrDetd BMS_DCChgMode BMS_ChrgDcChrgnFltStopReas;
SIG_GROUP_ 258 BMS_1_0x102_E2E_P01_5 1 : BMS_1_CRC5 BMS_1_RollgCntr5 BMS_1_Resd5 BMS_ChargeRequest_Mode BMS_ChgRemTime BMS_1_StateOfChargeDis BMS_StateOfEnergy;
SIG_GROUP_ 258 BMS_1_0x102_E2E_P01_6 1 : BMS_1_CRC6 BMS_1_RollgCntr6 BMS_1_Resd6 BMS_StateOfHealth BMS_BlanceState BMS_IsolationFault BMS_HVILFault_DC BMS_HVILFault_FMCU BMS_HVILFault_RMCU BMS_SOCDis BMS_InfraDcIActDcMin;
SIG_GROUP_ 1290 BMS_8_0x50A_E2E_P01_1 1 : BMS_8_CRC1 BMS_8_RollgCntr1 BMS_8_Resd1 BMS_HvBattCellOverU BMS_HvBattCellUnderU BMS_HvBattUnderU BMS_HvBattDischargeOverCurrent BMS_HvBattChargeOverCurrent BMS_HvBattOverU BMS_HvBattMismatching BMS_HvBattSocJump BMS_HvBattCellUUnif BMS_HvBattLowSoc BMS_HvBattOverSoc BMS_HvBattTempUniformity BMS_BattInterCANErr BMS_HvBattOverCharging BMS_HvBattOverTemperature;
SIG_GROUP_ 612 EPB_R_1_0x264_E2E_P01_1 1 : Fusa_264_1 Fusa_264_2 Fusa_264_3 Fusa_264_4 Fusa_264_5 EPB_R_1_CRC1 EPB_R_1_RollgCntr1 EPB_1_FltLamp EPB_1_ParkLamp EPB_1_ActrSt EPB_1_RWUSt EPB_1_TextDisp IPB_EPBErrorStatus;
